VERSION ""

NS_ :

BS_:

BU_: VMM IMR BCS GSM EMS EPB SRS TEL ICM ACU VCU WCM TSCM Tester Test SCMRR SCMRL SCM SBM RCP PSDR PSDL PLGM PAS LCU IHU IBCM IAL HVSPRR HVSPRL HVSMR HVSM HVACF HUD GWM FRDCM FLDCM FCP FAPA ETC Diagnostic Messages AVAS AMP

BO_ 796 BCM_BCAN_4: 8 IBCM
 SG_ BCM_RearWiperSerPstFuncCfgSt : 26|1@0+ (1,0) [0|1] ""  IHU
 SG_ BCM_RLSAutoSRWinCloseCfgSt : 36|1@0+ (1,0) [0|1] ""  IHU,GWM
 SG_ BCM_AutoSRWinCloseCfgSt : 35|1@0+ (1,0) [0|1] ""  IHU,GWM
 SG_ BCM_HeadlightDelayCfgSt : 37|1@0+ (1,0) [0|1] ""  IHU,GWM
 SG_ BCM_IGNOffTime : 23|10@0+ (1,0) [0|1000] "min"  IHU,GWM
 SG_ BCM_IGNOffTimeVD : 29|1@0+ (1,0) [0|1] ""  IHU,GWM
 SG_ BCM_AutoDomeLightCfgSt : 27|1@0+ (1,0) [0|1] ""  IHU
 SG_ BCM_AutoWiperCfgSt : 25|1@0+ (1,0) [0|1] ""  IHU,GWM
 SG_ BCM_IALFuncCfgSt : 24|1@0+ (1,0) [0|1] ""  FCP,IHU,GWM
 SG_ BCM_OSRMAutoFoldCfgSt : 15|1@0+ (1,0) [0|1] ""  FLDCM,FRDCM,IHU,GWM
 SG_ BCM_HornCfgSt : 14|1@0+ (1,0) [0|1] ""  IHU,GWM
 SG_ BCM_DTRLFuncCfgSt : 13|1@0+ (1,0) [0|1] ""  IHU,GWM
 SG_ BCM_RGearEnableRearWipeCfgSt : 12|1@0+ (1,0) [0|1] ""  IHU,GWM
 SG_ BCM_FrontWiperSerPstFuncCfgSt : 11|1@0+ (1,0) [0|1] ""  IHU,GWM
 SG_ BCM_AutoLightSnsCfgSt : 10|3@0+ (1,0) [0|7] ""  IHU,GWM
 SG_ BCM_FollowMeHomeCfgSt : 7|2@0+ (1,0) [0|3] ""  IHU,GWM
 SG_ BCM_AutoUnlockCfgSt : 5|2@0+ (1,0) [0|3] ""  IHU,GWM
 SG_ BCM_SpdAutoLockCfgSt : 3|1@0+ (1,0) [0|1] ""  IHU,GWM
 SG_ BCM_RemoteUnlockCfgSt : 2|1@0+ (1,0) [0|1] ""  IHU,GWM
 SG_ BCM_FogLampTurnCfgSt : 1|1@0+ (1,0) [0|1] ""  IHU,GWM
 SG_ BCM_RemoteCtrlFDMRMCfgSt : 0|1@0+ (1,0) [0|1] ""  FLDCM,FRDCM,IHU,GWM

BO_ 605 BCM_BCAN_2: 8 IBCM
 SG_ BCM_CentralLockSWSt : 55|1@0+ (1,0) [0|1] ""  IHU,GWM
 SG_ BCM_InteriorTrunkReleaseSwitch : 54|1@0+ (1,0) [0|1] ""  PLGM,IHU,GWM
 SG_ BCM_MainLampSwitchSt : 47|2@0+ (1,0) [0|3] ""  LCU,IHU,GWM
 SG_ BCM_BeamSwitchSt : 45|2@0+ (1,0) [0|3] ""  LCU,IHU,GWM
 SG_ BCM_AutoHighBeamCtrlSt : 43|1@0+ (1,0) [0|1] ""  LCU,IHU,FAPA,GWM
 SG_ BCM_RightTurnLampFaultSt : 36|1@0+ (1,0) [0|1] ""  LCU,IHU,PAS,FAPA,GWM
 SG_ BCM_RightTurnLampSt : 35|1@0+ (1,0) [0|1] ""  LCU,FLDCM,FRDCM,IHU,PAS,FAPA,GWM
 SG_ BCM_LeftTurnLampFaultSt : 34|1@0+ (1,0) [0|1] ""  LCU,IHU,PAS,FAPA,GWM
 SG_ BCM_LeftTurnLampSt : 33|1@0+ (1,0) [0|1] ""  LCU,FLDCM,FRDCM,IHU,PAS,FAPA,GWM
 SG_ BCM_LowBeamFaultSt : 31|1@0+ (1,0) [0|1] ""  IHU,GWM
 SG_ BCM_PositionLightFaultSt : 30|1@0+ (1,0) [0|1] ""  IHU,GWM
 SG_ BCM_PositionLightswitchSt : 29|1@0+ (1,0) [0|1] ""  IHU,GWM
 SG_ BCM_BrakeLightFaultSt : 28|1@0+ (1,0) [0|1] ""  IHU,GWM
 SG_ BCM_DRLRFaultSt : 25|1@0+ (1,0) [0|1] ""  IHU,GWM
 SG_ BCM_DRLLFaultSt : 20|1@0+ (1,0) [0|1] ""  IHU,GWM
 SG_ BCM_RearWasherSt : 23|1@0+ (1,0) [0|1] ""  IHU,GWM
 SG_ BCM_ReverseSwitchSt : 13|1@0+ (1,0) [0|1] ""  IHU,FAPA,GWM
 SG_ BCM_RearWiperSt : 12|1@0+ (1,0) [0|1] ""  IHU,GWM
 SG_ BCM_DTRLSt : 10|1@0+ (1,0) [0|1] ""  IHU,GWM
 SG_ BCM_FrontWiperSt : 5|2@0+ (1,0) [0|3] ""  IHU,FAPA,GWM

BO_ 792 BCM_BCAN_1: 8 IBCM
 SG_ RLS_LightSwitchReason : 63|4@0+ (1,0) [0|15] ""  HVACF,IHU,GWM
 SG_ BCM_RemoteControlSt : 59|4@0+ (1,0) [0|15] ""  PLGM,FLDCM,FRDCM,IHU,SBM,GWM
 SG_ BCM_HornSt : 55|1@0+ (1,0) [0|1] ""  IHU,SBM,GWM
 SG_ BCM_FOB_ID : 54|4@0+ (1,0) [0|15] ""  IHU,GWM
 SG_ BCM_DRLRFaultSt : 50|1@0+ (1,0) [0|1] ""  IHU,GWM
 SG_ BCM_DRLLFaultSt : 49|1@0+ (1,0) [0|1] ""  IHU,GWM
 SG_ BCM_FrontWasherSt : 48|1@0+ (1,0) [0|1] ""  HVACF,IHU,GWM
 SG_ BCM_SunRoofPstSt : 47|4@0+ (1,0) [0|15] ""  AMP,IHU,SBM,GWM
 SG_ BCM_WinMoveSt : 43|2@0+ (1,0) [0|3] ""  IHU,SBM,GWM
 SG_ BCM_ETWS_St : 41|1@0+ (1,0) [0|1] ""  IHU,GWM
 SG_ BCM_RoomlampSt : 40|1@0+ (1,0) [0|1] ""  IAL,FCP,IHU,GWM
 SG_ BCM_PsngrDoorLockSt : 39|1@0+ (1,0) [0|1] ""  FLDCM,FRDCM,IAL,IHU,SBM,GWM
 SG_ BCM_DriverDoorLockSt : 38|1@0+ (1,0) [0|1] ""  FLDCM,FRDCM,IAL,IHU,SBM,GWM
 SG_ BCM_ATWS_St : 37|3@0+ (1,0) [0|7] ""  FLDCM,FRDCM,HVACF,IHU,SBM,GWM
 SG_ BCM_AlarmHistory : 34|3@0+ (1,0) [0|7] ""  IHU,GWM
 SG_ BCM_KeyInsertSt : 31|1@0+ (1,0) [0|1] ""  IHU,GWM
 SG_ BCM_KeyInReminderWarnReq : 30|1@0+ (1,0) [0|1] ""  IHU,SBM,GWM
 SG_ BCM_RmtCtrlFobBattLow : 29|1@0+ (1,0) [0|1] ""  IHU,SBM,GWM
 SG_ BCM_TransportModeSt : 28|1@0+ (1,0) [0|1] ""  IHU,GWM
 SG_ BCM_SunRoofOpenWarning : 27|1@0+ (1,0) [0|1] ""  IAL,IHU,SBM,GWM
 SG_ BCM_VehReverseSt : 26|1@0+ (1,0) [0|1] ""  AMP,IAL,IHU,SBM,GWM
 SG_ BCM_BrakeLightSwitchSt : 25|1@0+ (1,0) [0|1] ""  AMP,FLDCM,FRDCM,HVACF,IHU,GWM
 SG_ BCM_ParkingLampSt : 24|1@0+ (1,0) [0|1] ""  HVSPRR,HVSPRL,HVACF,IAL,RCP,FCP,IHU,SBM,GWM
 SG_ BCM_RearFogLampSt : 23|1@0+ (1,0) [0|1] ""  IHU,SBM,GWM
 SG_ BCM_FrontFogLampSt : 22|1@0+ (1,0) [0|1] ""  IHU,SBM,GWM
 SG_ BCM_HighBeamSt : 21|1@0+ (1,0) [0|1] ""  IHU,SBM,GWM
 SG_ BCM_LowBeamSt : 20|1@0+ (1,0) [0|1] ""  IHU,SBM,GWM
 SG_ BCM_RightTurnLampFaultSt : 19|1@0+ (1,0) [0|1] ""  IHU,SBM,GWM
 SG_ BCM_RightTurnLampSt : 18|1@0+ (1,0) [0|1] ""  IAL,FCP,IHU,SBM,GWM
 SG_ BCM_LeftTurnLampFaultSt : 17|1@0+ (1,0) [0|1] ""  IHU,SBM,GWM
 SG_ BCM_LeftTurnLampSt : 16|1@0+ (1,0) [0|1] ""  IAL,FCP,IHU,SBM,GWM
 SG_ BCM_DTRLSt : 15|1@0+ (1,0) [0|1] ""  IHU,GWM
 SG_ BCM_TrunkReleaseCmd : 14|1@0+ (1,0) [0|1] ""  IHU,SBM,GWM
 SG_ BCM_TrunkAjarSt : 13|1@0+ (1,0) [0|1] ""  AMP,IHU,SBM,GWM
 SG_ BCM_BonnetAjarSt : 12|1@0+ (1,0) [0|1] ""  AMP,IHU,SBM,GWM
 SG_ BCM_RRDoorAjarSt : 11|1@0+ (1,0) [0|1] ""  SCMRR,AMP,FLDCM,FRDCM,IAL,IHU,SBM,GWM
 SG_ BCM_RLDoorAjarSt : 10|1@0+ (1,0) [0|1] ""  SCMRL,AMP,FLDCM,FRDCM,IAL,IHU,SBM,GWM
 SG_ BCM_PsngrDoorAjarSt : 9|1@0+ (1,0) [0|1] ""  AMP,FLDCM,FRDCM,IAL,IHU,SBM,GWM
 SG_ BCM_DriverDoorAjarSt : 8|1@0+ (1,0) [0|1] ""  AMP,FLDCM,FRDCM,SCM,IAL,IHU,SBM,GWM
 SG_ BCM_LampOnWarningReq : 5|1@0+ (1,0) [0|1] ""  IHU,SBM,GWM
 SG_ BCM_PGearSt : 4|1@0+ (1,0) [0|1] ""  HUD,IHU,GWM
 SG_ BCM_KeySt : 1|2@0+ (1,0) [0|3] ""  HVSMR,HVSPRR,HVSPRL,SCMRR,SCMRL,AMP,LCU,HUD,FLDCM,FRDCM,SCM,TSCM,HVACF,IAL,RCP,FCP,HVSM,IHU,SBM,GWM

BO_ 1835 ACU_Phys_Diag_Rx: 8 Tester
 SG_ ACU_Diag_Request : 7|64@0+ (1,0) [0|0] ""  IHU

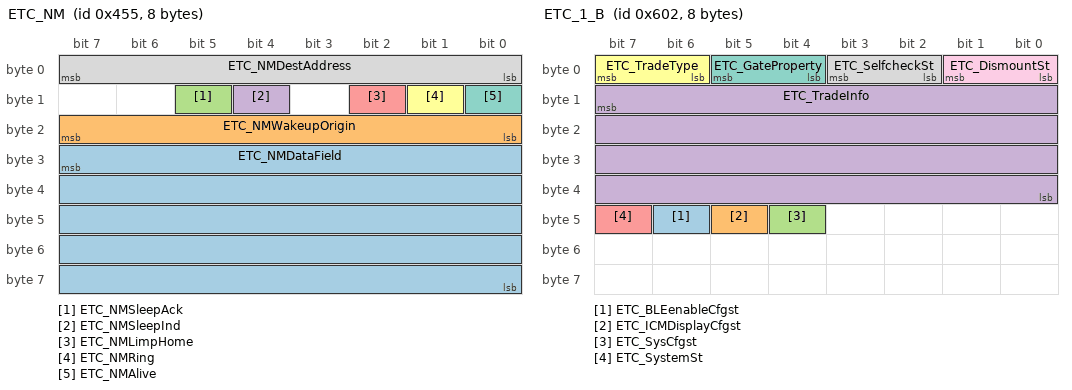
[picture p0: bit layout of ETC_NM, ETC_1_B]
BO_ 1109 ETC_NM: 8 ETC
 SG_ ETC_NMDataField : 31|40@0+ (1,0) [0|0] ""  PSDR,PSDL,AMP,LCU,HUD,PLGM,FLDCM,FRDCM,SCM,TSCM,IBCM,HVACF,IAL,RCP,FCP,HVSM,IHU,SBM,WCM
 SG_ ETC_NMWakeupOrigin : 23|8@0+ (1,0) [0|255] ""  PSDR,PSDL,AMP,LCU,HUD,PLGM,FLDCM,FRDCM,SCM,TSCM,IBCM,HVACF,IAL,RCP,FCP,HVSM,IHU,SBM,WCM
 SG_ ETC_NMSleepAck : 13|1@0+ (1,0) [0|1] ""  PSDR,PSDL,AMP,LCU,HUD,PLGM,FLDCM,FRDCM,SCM,TSCM,IBCM,HVACF,IAL,RCP,FCP,HVSM,IHU,SBM,WCM
 SG_ ETC_NMSleepInd : 12|1@0+ (1,0) [0|1] ""  PSDR,PSDL,AMP,LCU,HUD,PLGM,FLDCM,FRDCM,SCM,TSCM,IBCM,HVACF,IAL,RCP,FCP,HVSM,IHU,SBM,WCM
 SG_ ETC_NMLimpHome : 10|1@0+ (1,0) [0|1] ""  PSDR,PSDL,AMP,LCU,HUD,PLGM,FLDCM,FRDCM,SCM,TSCM,IBCM,HVACF,IAL,RCP,FCP,HVSM,IHU,SBM,WCM
 SG_ ETC_NMRing : 9|1@0+ (1,0) [0|1] ""  PSDR,PSDL,AMP,LCU,HUD,PLGM,FLDCM,FRDCM,SCM,TSCM,IBCM,HVACF,IAL,RCP,FCP,HVSM,IHU,SBM,WCM
 SG_ ETC_NMAlive : 8|1@0+ (1,0) [0|1] ""  PSDR,PSDL,AMP,LCU,HUD,PLGM,FLDCM,FRDCM,SCM,TSCM,IBCM,HVACF,IAL,RCP,FCP,HVSM,IHU,SBM,WCM
 SG_ ETC_NMDestAddress : 7|8@0+ (1,0) [0|255] ""  PSDR,PSDL,AMP,LCU,HUD,PLGM,FLDCM,FRDCM,SCM,TSCM,IBCM,HVACF,IAL,RCP,FCP,HVSM,IHU,SBM,WCM

BO_ 1538 ETC_1_B: 8 ETC
 SG_ ETC_BLEenableCfgst : 46|1@0+ (1,0) [0|1] ""  IHU
 SG_ ETC_ICMDisplayCfgst : 45|1@0+ (1,0) [0|1] ""  IHU
 SG_ ETC_SysCfgst : 44|1@0+ (1,0) [0|1] ""  IHU
 SG_ ETC_TradeInfo : 15|32@0+ (0.01,0) [0|42949672.94] ""  IHU
 SG_ ETC_SystemSt : 47|1@0+ (1,0) [0|3] ""  IHU
 SG_ ETC_TradeType : 7|2@0+ (1,0) [0|3] ""  IHU
 SG_ ETC_GateProperty : 5|2@0+ (1,0) [0|3] ""  IHU
 SG_ ETC_SelfcheckSt : 3|2@0+ (1,0) [0|3] ""  IHU
 SG_ ETC_DismountSt : 1|2@0+ (1,0) [0|3] ""  IHU

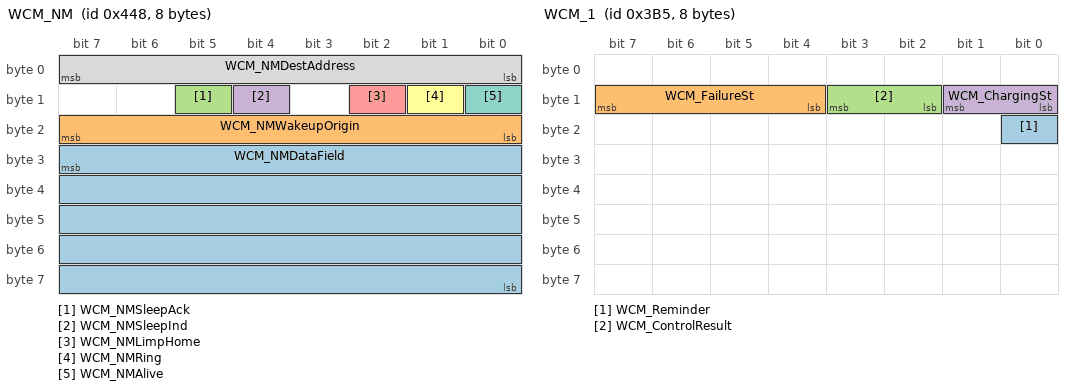
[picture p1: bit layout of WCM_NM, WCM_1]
BO_ 1096 WCM_NM: 8 WCM
 SG_ WCM_NMDataField : 31|40@0+ (1,0) [0|0] ""  PSDR,PSDL,AMP,LCU,HUD,PLGM,FLDCM,FRDCM,SCM,TSCM,IBCM,HVACF,IAL,RCP,FCP,HVSM,IHU,SBM,ETC,GWM
 SG_ WCM_NMWakeupOrigin : 23|8@0+ (1,0) [0|255] ""  PSDR,PSDL,AMP,LCU,HUD,PLGM,FLDCM,FRDCM,SCM,TSCM,IBCM,HVACF,IAL,RCP,FCP,HVSM,IHU,SBM,ETC,GWM
 SG_ WCM_NMSleepAck : 13|1@0+ (1,0) [0|1] ""  PSDR,PSDL,AMP,LCU,HUD,PLGM,FLDCM,FRDCM,SCM,TSCM,IBCM,HVACF,IAL,RCP,FCP,HVSM,IHU,SBM,ETC,GWM
 SG_ WCM_NMSleepInd : 12|1@0+ (1,0) [0|1] ""  PSDR,PSDL,AMP,LCU,HUD,PLGM,FLDCM,FRDCM,SCM,TSCM,IBCM,HVACF,IAL,RCP,FCP,HVSM,IHU,SBM,ETC,GWM
 SG_ WCM_NMLimpHome : 10|1@0+ (1,0) [0|1] ""  PSDR,PSDL,AMP,LCU,HUD,PLGM,FLDCM,FRDCM,SCM,TSCM,IBCM,HVACF,IAL,RCP,FCP,HVSM,IHU,SBM,ETC,GWM
 SG_ WCM_NMRing : 9|1@0+ (1,0) [0|1] ""  PSDR,PSDL,AMP,LCU,HUD,PLGM,FLDCM,FRDCM,SCM,TSCM,IBCM,HVACF,IAL,RCP,FCP,HVSM,IHU,SBM,ETC,GWM
 SG_ WCM_NMAlive : 8|1@0+ (1,0) [0|1] ""  PSDR,PSDL,AMP,LCU,HUD,PLGM,FLDCM,FRDCM,SCM,TSCM,IBCM,HVACF,IAL,RCP,FCP,HVSM,IHU,SBM,ETC,GWM
 SG_ WCM_NMDestAddress : 7|8@0+ (1,0) [0|255] ""  PSDR,PSDL,AMP,LCU,HUD,PLGM,FLDCM,FRDCM,SCM,TSCM,IBCM,HVACF,IAL,RCP,FCP,HVSM,IHU,SBM,ETC,GWM

BO_ 949 WCM_1: 8 WCM
 SG_ WCM_Reminder : 16|1@0+ (1,0) [0|1] ""  IHU,GWM
 SG_ WCM_FailureSt : 15|4@0+ (1,0) [0|15] ""  IHU,GWM
 SG_ WCM_ControlResult : 11|2@0+ (1,0) [0|3] ""  IHU,GWM
 SG_ WCM_ChargingSt : 9|2@0+ (1,0) [0|3] ""  IHU,GWM

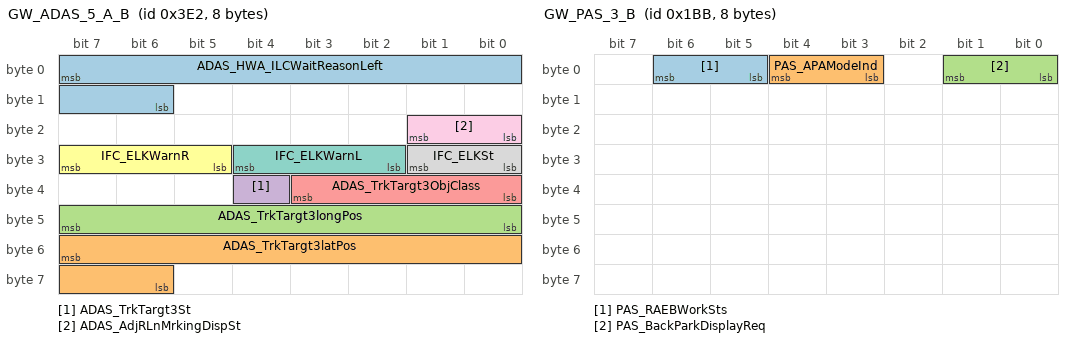
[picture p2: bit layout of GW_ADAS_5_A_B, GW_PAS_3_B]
BO_ 994 GW_ADAS_5_A_B: 8 GWM
 SG_ ADAS_HWA_ILCWaitReasonLeft : 7|10@0+ (1,0) [0|1023] ""  IHU
 SG_ ADAS_TrkTargt3latPos : 55|10@0+ (0.1,-51.2) [-51.2|51.1] "m"  IHU
 SG_ ADAS_TrkTargt3longPos : 47|8@0+ (1,0) [0|254] "m"  IHU
 SG_ ADAS_TrkTargt3St : 36|1@0+ (1,0) [0|1] ""  IHU
 SG_ ADAS_TrkTargt3ObjClass : 35|4@0+ (1,0) [0|15] ""  IHU
 SG_ IFC_ELKWarnR : 31|3@0+ (1,0) [0|7] ""  HUD,IHU
 SG_ IFC_ELKWarnL : 28|3@0+ (1,0) [0|7] ""  HUD,IHU
 SG_ IFC_ELKSt : 25|2@0+ (1,0) [0|3] ""  HUD,IHU
 SG_ ADAS_AdjRLnMrkingDispSt : 17|2@0+ (1,0) [0|3] ""  HUD,IHU

BO_ 760 GW_PADS_1_B: 8 GWM
 SG_ PADS_ICM_MenuBtnStVD : 55|1@0+ (1,0) [0|1] ""  IHU
 SG_ PADS_ICM_MenuBtnSt : 54|1@0+ (1,0) [0|1] ""  IHU
 SG_ PADS_ACU_CusBtnStVD : 53|1@0+ (1,0) [0|1] ""  IHU
 SG_ PADS_ACU_CusBtnSt : 52|1@0+ (1,0) [0|1] ""  IHU
 SG_ PADS_ACU_WechatBtnStVD : 43|1@0+ (1,0) [0|1] ""  IHU
 SG_ PADS_ACU_WechatBtnSt : 42|1@0+ (1,0) [0|1] ""  IHU
 SG_ PADS_ICM_SkipslideBtnSt : 26|2@0+ (1,0) [0|3] ""  IHU
 SG_ PADS_ICM_OkBtnStVD : 24|1@0+ (1,0) [0|1] ""  IHU
 SG_ PADS_ICM_OkBtnSt : 23|1@0+ (1,0) [0|1] ""  IHU
 SG_ PADS_ICM_DowmBtnStVD : 22|1@0+ (1,0) [0|1] ""  IHU
 SG_ PADS_ICM_DowmBtnSt : 21|1@0+ (1,0) [0|1] ""  IHU
 SG_ PADS_ICM_UpBtnStVD : 20|1@0+ (1,0) [0|1] ""  IHU
 SG_ PADS_ICM_UpBtnSt : 19|1@0+ (1,0) [0|1] ""  IHU
 SG_ PADS_ACU_PhoneBtnStVD : 18|1@0+ (1,0) [0|1] ""  IHU
 SG_ PADS_ACU_PhoneBtnSt : 17|1@0+ (1,0) [0|1] ""  IHU
 SG_ PADS_ACU_VrBtnStVD : 16|1@0+ (1,0) [0|1] ""  IHU
 SG_ PADS_ACU_VrBtnSt : 15|1@0+ (1,0) [0|1] ""  IHU
 SG_ PADS_ICM_ViewBtnStVD : 14|1@0+ (1,0) [0|1] ""  IHU
 SG_ PADS_ICM_ViewBtnSt : 13|1@0+ (1,0) [0|1] ""  IHU
 SG_ PADS_ACU_SkipslideBtnStVD : 12|1@0+ (1,0) [0|1] ""  IHU
 SG_ PADS_ACU_SkipslideBtnSt : 11|2@0+ (1,0) [0|3] ""  IHU
 SG_ PADS_ACU_SkipDecBtnStVD : 9|1@0+ (1,0) [0|1] ""  IHU
 SG_ PADS_ACU_SkipDecBtnSt : 8|1@0+ (1,0) [0|1] ""  IHU
 SG_ PADS_ACU_SkipIncBtnStVD : 7|1@0+ (1,0) [0|1] ""  IHU
 SG_ PADS_ACU_SkipIncBtnSt : 6|1@0+ (1,0) [0|1] ""  IHU
 SG_ PADS_ACU_VolDecBtnStVD : 5|1@0+ (1,0) [0|1] ""  IHU
 SG_ PADS_ACU_VolDecBtnSt : 4|1@0+ (1,0) [0|1] ""  IHU
 SG_ PADS_ACU_VolIncBtnStVD : 3|1@0+ (1,0) [0|1] ""  IHU
 SG_ PADS_ACU_VolIncBtnSt : 2|1@0+ (1,0) [0|1] ""  IHU
 SG_ PADS_ACU_ModeBtnStVD : 1|1@0+ (1,0) [0|1] ""  IHU
 SG_ PADS_ACU_ModeBtnSt : 0|1@0+ (1,0) [0|1] ""  IHU

BO_ 443 GW_PAS_3_B: 8 GWM
 SG_ PAS_RAEBWorkSts : 6|2@0+ (1,0) [0|3] "-"  IHU
 SG_ PAS_APAModeInd : 4|2@0+ (1,0) [0|3] ""  IHU
 SG_ PAS_BackParkDisplayReq : 1|2@0+ (1,0) [0|3] ""  IHU

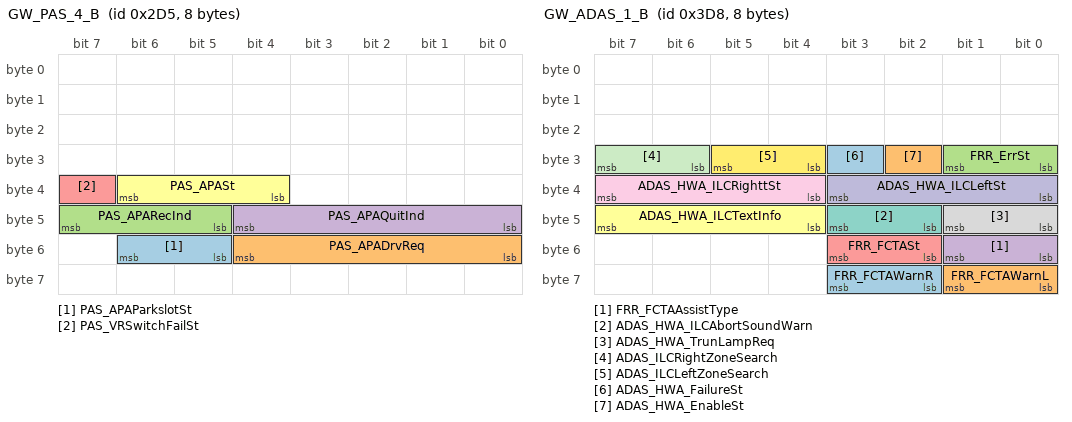
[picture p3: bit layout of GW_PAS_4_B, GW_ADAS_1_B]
BO_ 725 GW_PAS_4_B: 8 GWM
 SG_ PAS_APAParkslotSt : 54|2@0+ (1,0) [0|3] "-"  IHU
 SG_ PAS_APADrvReq : 52|5@0+ (1,0) [0|31] "-"  AMP,IHU,SBM
 SG_ PAS_APARecInd : 47|3@0+ (1,0) [0|7] "-"  AMP,IHU,SBM
 SG_ PAS_APAQuitInd : 44|5@0+ (1,0) [0|31] "-"  AMP,IHU,SBM
 SG_ PAS_VRSwitchFailSt : 39|1@0+ (1,0) [0|1] ""  IHU
 SG_ PAS_APASt : 38|3@0+ (1,0) [0|7] "-"  AMP,IBCM,IHU,SBM

BO_ 984 GW_ADAS_1_B: 8 GWM
 SG_ FRR_FCTAWarnR : 59|2@0+ (1,0) [0|3] ""  HUD,IHU
 SG_ FRR_FCTAWarnL : 57|2@0+ (1,0) [0|3] ""  HUD,IHU
 SG_ FRR_ErrSt : 25|2@0+ (1,0) [0|3] ""  IHU
 SG_ FRR_FCTAAssistType : 49|2@0+ (1,0) [0|3] ""  IHU
 SG_ FRR_FCTASt : 51|2@0+ (1,0) [0|3] ""  HUD,IHU
 SG_ ADAS_HWA_ILCTextInfo : 47|4@0+ (1,0) [0|15] ""  HUD,IHU
 SG_ ADAS_HWA_ILCAbortSoundWarn : 43|2@0+ (1,0) [0|3] ""  IHU
 SG_ ADAS_HWA_TrunLampReq : 41|2@0+ (1,0) [0|3] ""  HUD,IHU
 SG_ ADAS_HWA_ILCRighttSt : 39|4@0+ (1,0) [0|15] ""  IHU
 SG_ ADAS_HWA_ILCLeftSt : 35|4@0+ (1,0) [0|15] ""  IHU
 SG_ ADAS_ILCRightZoneSearch : 31|2@0+ (1,0) [0|3] ""  IHU
 SG_ ADAS_ILCLeftZoneSearch : 29|2@0+ (1,0) [0|3] ""  HUD,IHU
 SG_ ADAS_HWA_FailureSt : 27|1@0+ (1,0) [0|1] ""  HUD,IHU
 SG_ ADAS_HWA_EnableSt : 26|1@0+ (1,0) [0|1] ""  HUD,IHU

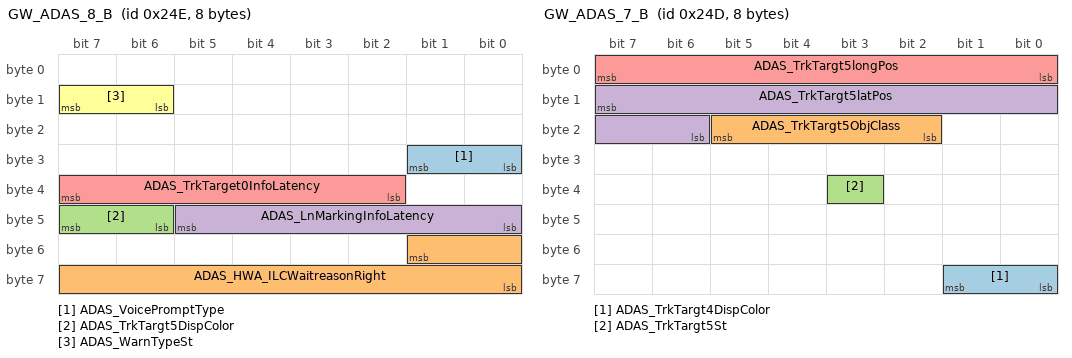
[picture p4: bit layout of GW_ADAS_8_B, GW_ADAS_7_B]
BO_ 590 GW_ADAS_8_B: 8 GWM
 SG_ ADAS_VoicePromptType : 25|2@0+ (1,0) [0|3] ""  ACU,IHU
 SG_ ADAS_HWA_ILCWaitreasonRight : 49|10@0+ (1,0) [0|1023] ""  IHU
 SG_ ADAS_TrkTargt5DispColor : 47|2@0+ (1,0) [0|3] ""  IHU
 SG_ ADAS_LnMarkingInfoLatency : 45|6@0+ (10,0) [0|630] "ms"  IHU
 SG_ ADAS_TrkTarget0InfoLatency : 39|6@0+ (10,0) [0|630] "ms"  IHU
 SG_ ADAS_WarnTypeSt : 15|2@0+ (1,0) [0|3] ""  SCM,IHU

BO_ 589 GW_ADAS_7_B: 8 GWM
 SG_ ADAS_TrkTargt4DispColor : 57|2@0+ (1,0) [0|3] ""  IHU
 SG_ ADAS_TrkTargt5ObjClass : 21|4@0+ (1,0) [0|15] "-"  IHU
 SG_ ADAS_TrkTargt5St : 35|1@0+ (1,0) [0|1] "-"  IHU
 SG_ ADAS_TrkTargt5latPos : 15|10@0+ (0.1,-51.2) [-51.2|51.1] "m"  IHU
 SG_ ADAS_TrkTargt5longPos : 7|8@0+ (1,0) [0|254] "m"  IHU

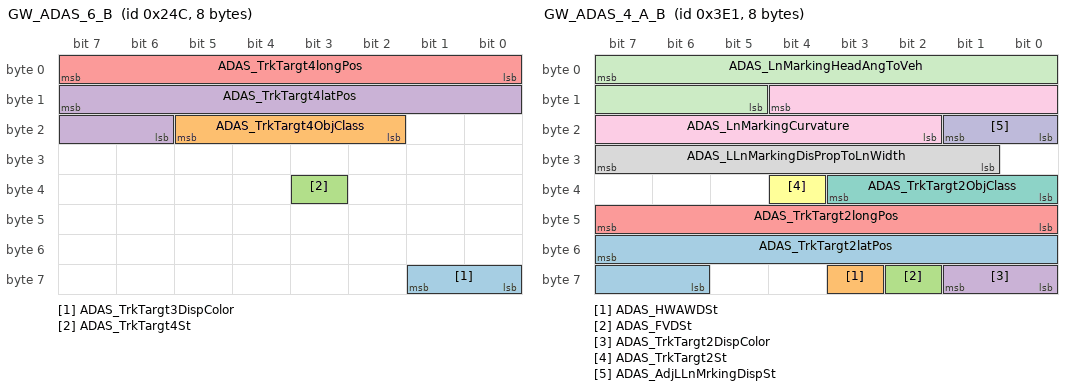
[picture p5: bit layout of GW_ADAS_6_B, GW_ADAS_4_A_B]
BO_ 588 GW_ADAS_6_B: 8 GWM
 SG_ ADAS_TrkTargt3DispColor : 57|2@0+ (1,0) [0|3] ""  HUD,IHU
 SG_ ADAS_TrkTargt4ObjClass : 21|4@0+ (1,0) [0|15] "-"  IHU
 SG_ ADAS_TrkTargt4St : 35|1@0+ (1,0) [0|1] "-"  IHU
 SG_ ADAS_TrkTargt4latPos : 15|10@0+ (0.1,-51.2) [-51.2|51.1] "m"  IHU
 SG_ ADAS_TrkTargt4longPos : 7|8@0+ (1,0) [0|254] "m"  IHU

BO_ 993 GW_ADAS_4_A_B: 8 GWM
 SG_ ADAS_TrkTargt2latPos : 55|10@0+ (0.1,-51.2) [-51.2|51.1] "m"  IHU
 SG_ ADAS_HWAWDSt : 59|1@0+ (1,0) [0|1] ""  IHU
 SG_ ADAS_FVDSt : 58|1@0+ (1,0) [0|1] ""  IHU
 SG_ ADAS_TrkTargt2DispColor : 57|2@0+ (1,0) [0|3] ""  IHU
 SG_ ADAS_TrkTargt2longPos : 47|8@0+ (1,0) [0|254] "m"  IHU
 SG_ ADAS_TrkTargt2St : 36|1@0+ (1,0) [0|1] ""  IHU
 SG_ ADAS_TrkTargt2ObjClass : 35|4@0+ (1,0) [0|15] ""  IHU
 SG_ ADAS_LLnMarkingDisPropToLnWidth : 31|7@0+ (1,0) [0|100] "%"  HUD,IHU
 SG_ ADAS_LnMarkingCurvature : 12|11@0+ (1E-005,-0.01023) [-0.01023|0.01023] "1/m"  HUD,IHU
 SG_ ADAS_AdjLLnMrkingDispSt : 17|2@0+ (1,0) [0|3] ""  HUD,IHU
 SG_ ADAS_LnMarkingHeadAngToVeh : 7|11@0+ (0.001,-1.023) [-1.023|1.023] "rad"  HUD,IHU

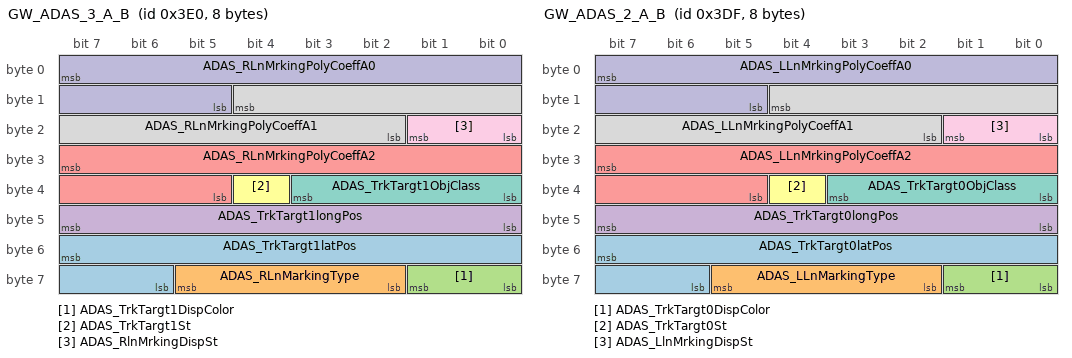
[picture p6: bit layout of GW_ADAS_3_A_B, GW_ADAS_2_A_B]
BO_ 992 GW_ADAS_3_A_B: 8 GWM
 SG_ ADAS_TrkTargt1latPos : 55|10@0+ (0.1,-51.2) [-51.2|51.1] "m"  HUD,IHU
 SG_ ADAS_RLnMarkingType : 61|4@0+ (1,0) [0|15] ""  HUD,IHU
 SG_ ADAS_TrkTargt1DispColor : 57|2@0+ (1,0) [0|3] "-"  HUD,IHU
 SG_ ADAS_TrkTargt1longPos : 47|8@0+ (1,0) [0|254] "m"  HUD,IHU
 SG_ ADAS_RLnMrkingPolyCoeffA2 : 31|11@0+ (1E-005,-0.01023) [-0.01023|0.01023] "1/m"  HUD,IHU
 SG_ ADAS_TrkTargt1St : 36|1@0+ (1,0) [0|1] ""  HUD,IHU
 SG_ ADAS_TrkTargt1ObjClass : 35|4@0+ (1,0) [0|15] ""  HUD,IHU
 SG_ ADAS_RLnMrkingPolyCoeffA1 : 12|11@0+ (0.001,-1.023) [-1.023|1.023] "rad"  HUD,IHU
 SG_ ADAS_RlnMrkingDispSt : 17|2@0+ (1,0) [0|3] ""  HUD,IHU
 SG_ ADAS_RLnMrkingPolyCoeffA0 : 7|11@0+ (0.01,-10.23) [-10.23|10.23] "m"  HUD,IHU

BO_ 991 GW_ADAS_2_A_B: 8 GWM
 SG_ ADAS_TrkTargt0latPos : 55|10@0+ (0.1,-51.2) [-51.2|51.1] "m"  HUD,IHU
 SG_ ADAS_LLnMarkingType : 61|4@0+ (1,0) [0|15] ""  HUD,IHU
 SG_ ADAS_TrkTargt0DispColor : 57|2@0+ (1,0) [0|3] "-"  HUD,IHU
 SG_ ADAS_TrkTargt0longPos : 47|8@0+ (1,0) [0|254] "m"  HUD,IHU
 SG_ ADAS_LLnMrkingPolyCoeffA2 : 31|11@0+ (1E-005,-0.01023) [-0.01023|0.01023] "1/m"  HUD,IHU
 SG_ ADAS_TrkTargt0St : 36|1@0+ (1,0) [0|1] ""  HUD,IHU
 SG_ ADAS_TrkTargt0ObjClass : 35|4@0+ (1,0) [0|15] ""  HUD,IHU
 SG_ ADAS_LLnMrkingPolyCoeffA1 : 12|11@0+ (0.001,-1.023) [-1.023|1.023] "rad"  HUD,IHU
 SG_ ADAS_LlnMrkingDispSt : 17|2@0+ (1,0) [0|3] ""  HUD,IHU
 SG_ ADAS_LLnMrkingPolyCoeffA0 : 7|11@0+ (0.01,-10.23) [-10.23|10.23] "m"  HUD,IHU

BO_ 931 GW_IFC_1_A_B: 8 GWM
 SG_ IFC_TJA_ICA_St : 55|3@0+ (1,0) [0|7] ""  HUD,IHU
 SG_ IFC_TSR_AcousticWarn : 52|1@0+ (1,0) [0|1] ""  HUD,IHU
 SG_ IFC_TSR_VisualWarn : 51|1@0+ (1,0) [0|1] ""  HUD,IHU
 SG_ IFC_IHBC_Enable : 50|1@0+ (1,0) [0|1] ""  IHU
 SG_ IFC_TSR_Enable : 49|1@0+ (1,0) [0|1] ""  HUD,IHU
 SG_ IFC_IHBC_HighBeamReq : 48|1@0+ (1,0) [0|1] ""  IBCM,IHU
 SG_ IFC_IHBC_St : 47|3@0+ (1,0) [0|7] ""  IHU
 SG_ IFC_TSR_OperatingSt : 44|3@0+ (1,0) [0|7] ""  HUD,IHU
 SG_ IFC_TSR_SpdLimitUnit : 41|2@0+ (1,0) [0|3] ""  HUD,IHU
 SG_ IFC_TSR_SpdLimit : 39|5@0+ (1,0) [0|31] ""  HUD,IHU
 SG_ IFC_HWAHF_HandsOnIcon : 34|3@0+ (1,0) [0|7] ""  HUD,IHU
 SG_ IFC_LKS_TakeoverReq : 31|1@0+ (1,0) [0|1] ""  HUD,IHU
 SG_ IFC_RightTrackingSt : 30|2@0+ (1,0) [0|3] ""  HUD,IHU
 SG_ IFC_LeftTrackingSt : 28|2@0+ (1,0) [0|3] ""  HUD,IHU
 SG_ IFC_LKS_St : 26|3@0+ (1,0) [0|7] ""  HUD,IHU
 SG_ IFC_LKS_LaneAssistType : 23|2@0+ (1,0) [0|3] ""  HUD,IHU
 SG_ IFC_TSR_AudioWarnEnable : 20|1@0+ (1,0) [0|1] ""  HUD,IHU
 SG_ IFC_CruiseMode : 15|2@0+ (1,0) [0|3] ""  HUD,IHU
 SG_ IFC_TSR_SpdLimType : 13|2@0+ (1,0) [0|3] ""  HUD,IHU
 SG_ IFC_TSR_ISDRestOfDis : 11|4@0+ (1,0) [0|12] ""  HUD,IHU
 SG_ IFC_LateralCtrlQuitWarn : 7|1@0+ (1,0) [0|1] ""  HUD,IHU
 SG_ IFC_CameraBlockageSt : 6|1@0+ (1,0) [0|1] ""  HUD,IHU
 SG_ IFC_SysCalibrationSt : 5|2@0+ (1,0) [0|3] ""  HUD,IHU
 SG_ IFC_TSR_SLCAheadDis : 3|4@0+ (1,0) [0|12] ""  HUD,IHU

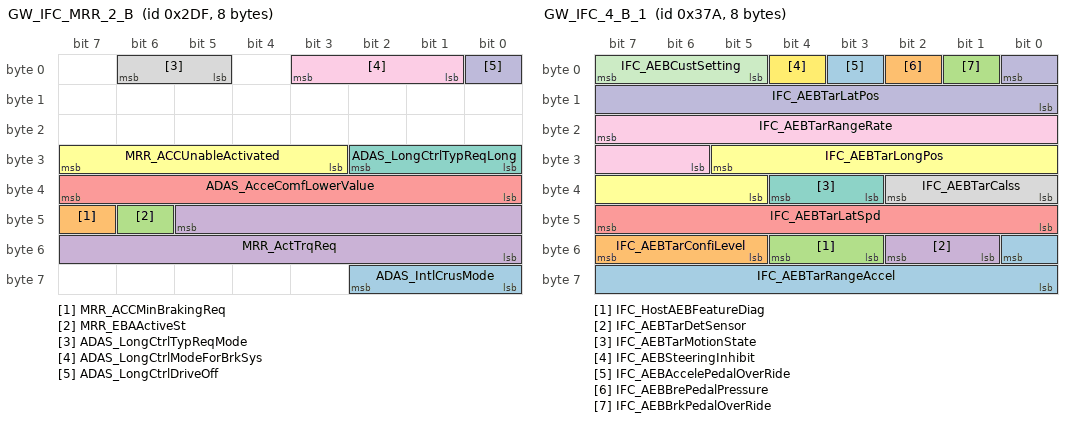
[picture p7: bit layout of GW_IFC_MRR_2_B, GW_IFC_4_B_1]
BO_ 735 GW_IFC_MRR_2_B: 8 GWM
 SG_ ADAS_IntlCrusMode : 58|3@0+ (1,0) [0|7] ""  IHU,PAS
 SG_ MRR_ACCMinBrakingReq : 47|1@0+ (1,0) [0|1] ""  IHU,PAS
 SG_ MRR_EBAActiveSt : 46|1@0+ (1,0) [0|1] ""  IHU,PAS
 SG_ MRR_ActTrqReq : 45|14@0+ (1,-5000) [-5000|5000] "Nm"  IHU,PAS
 SG_ ADAS_AcceComfLowerValue : 39|8@0+ (0.05,-7) [-7|5.75] "m/s2"  IHU,PAS
 SG_ MRR_ACCUnableActivated : 31|5@0+ (1,0) [0|31] ""  IHU,PAS
 SG_ ADAS_LongCtrlTypReqLong : 26|3@0+ (1,0) [0|7] ""  IHU,PAS
 SG_ ADAS_LongCtrlTypReqMode : 6|2@0+ (1,0) [0|3] ""  IHU,PAS
 SG_ ADAS_LongCtrlModeForBrkSys : 3|3@0+ (1,0) [0|7] ""  IHU
 SG_ ADAS_LongCtrlDriveOff : 0|1@0+ (1,0) [0|1] ""  IHU

BO_ 890 GW_IFC_4_B_1: 8 GWM
 SG_ IFC_AEBTarRangeAccel : 48|9@0+ (0.1,-25.5) [-25.5|25.5] "m/s^2"  IHU
 SG_ IFC_AEBTarConfiLevel : 55|3@0+ (1,0) [0|7] ""  IHU
 SG_ IFC_HostAEBFeatureDiag : 52|2@0+ (1,0) [0|3] ""  IHU
 SG_ IFC_AEBTarDetSensor : 50|2@0+ (1,0) [0|3] ""  IHU
 SG_ IFC_AEBTarLatSpd : 47|8@0+ (0.2,-25) [-25|25] "m/s"  IHU
 SG_ IFC_AEBTarLongPos : 29|9@0+ (0.2,0) [0|102.2] "m"  IHU
 SG_ IFC_AEBTarMotionState : 36|2@0+ (1,0) [0|3] ""  IHU
 SG_ IFC_AEBTarCalss : 34|3@0+ (1,0) [0|7] ""  IHU
 SG_ IFC_AEBTarRangeRate : 23|10@0+ (0.1,-51) [-51|51] "m/s"  IHU
 SG_ IFC_AEBTarLatPos : 0|9@0+ (0.2,-51) [-51|51] "m"  IHU
 SG_ IFC_AEBCustSetting : 7|3@0+ (1,0) [0|7] ""  IHU
 SG_ IFC_AEBSteeringInhibit : 4|1@0+ (1,0) [0|1] ""  IHU
 SG_ IFC_AEBAccelePedalOverRide : 3|1@0+ (1,0) [0|1] ""  IHU
 SG_ IFC_AEBBrePedalPressure : 2|1@0+ (1,0) [0|1] ""  IHU
 SG_ IFC_AEBBrkPedalOverRide : 1|1@0+ (1,0) [0|1] ""  IHU

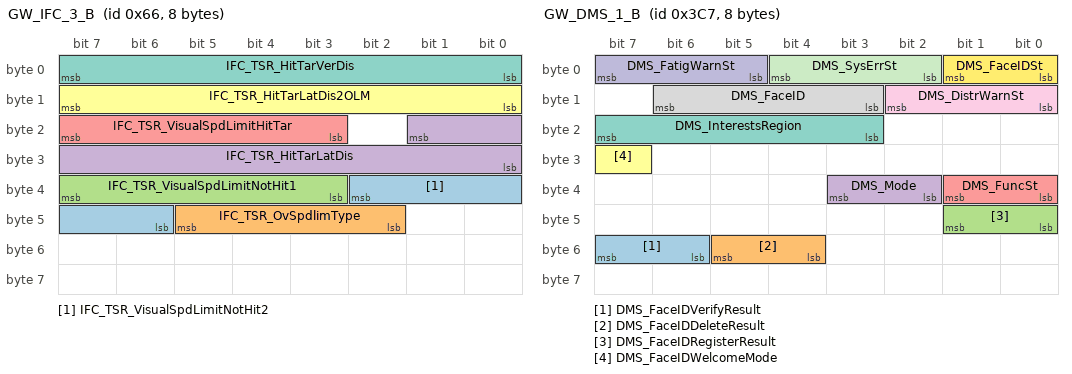
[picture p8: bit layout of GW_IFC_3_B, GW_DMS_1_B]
BO_ 102 GW_IFC_3_B: 8 GWM
 SG_ IFC_TSR_VisualSpdLimitNotHit2 : 34|5@0+ (1,0) [0|31] "km/h"  IHU
 SG_ IFC_TSR_OvSpdlimType : 45|4@0+ (1,0) [0|15] "-"  IHU
 SG_ IFC_TSR_VisualSpdLimitNotHit1 : 39|5@0+ (1,0) [0|31] "km/h"  IHU
 SG_ IFC_TSR_HitTarLatDis : 17|10@0+ (0.1,-51.2) [-25.4|25.4] "m"  IHU
 SG_ IFC_TSR_VisualSpdLimitHitTar : 23|5@0+ (1,0) [0|31] "km/h"  IHU
 SG_ IFC_TSR_HitTarLatDis2OLM : 15|8@0+ (0.1,0) [0|25.4] "m"  IHU
 SG_ IFC_TSR_HitTarVerDis : 7|8@0+ (0.1,0) [0|25.4] "m"  IHU

BO_ 967 GW_DMS_1_B: 8 GWM
 SG_ DMS_FaceIDVerifyResult : 55|2@0+ (1,0) [0|3] ""  IHU
 SG_ DMS_FaceIDDeleteResult : 53|2@0+ (1,0) [0|3] ""  IHU
 SG_ DMS_FaceIDRegisterResult : 41|2@0+ (1,0) [0|3] ""  IHU
 SG_ DMS_Mode : 35|2@0+ (1,0) [0|3] ""  IHU
 SG_ DMS_FuncSt : 33|2@0+ (1,0) [0|3] ""  IHU
 SG_ DMS_FaceIDWelcomeMode : 31|1@0+ (1,0) [0|1] ""  IHU
 SG_ DMS_InterestsRegion : 23|5@0+ (1,0) [0|31] ""  IHU
 SG_ DMS_FaceID : 14|4@0+ (1,0) [0|15] ""  IHU
 SG_ DMS_DistrWarnSt : 10|3@0+ (1,0) [0|7] ""  IHU
 SG_ DMS_FatigWarnSt : 7|3@0+ (1,0) [0|7] ""  IHU
 SG_ DMS_SysErrSt : 4|3@0+ (1,0) [0|7] ""  IHU
 SG_ DMS_FaceIDSt : 1|2@0+ (1,0) [0|3] ""  IHU

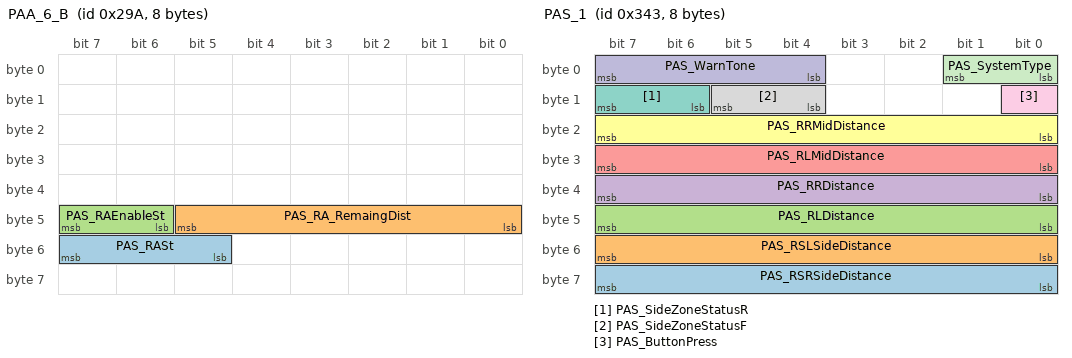
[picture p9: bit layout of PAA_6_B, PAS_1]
BO_ 666 PAA_6_B: 8 FAPA
 SG_ PAS_RASt : 55|3@0+ (1,0) [0|7] ""  IHU
 SG_ PAS_RA_RemaingDist : 45|6@0+ (1,0) [0|63] ""  IHU
 SG_ PAS_RAEnableSt : 47|2@0+ (1,0) [0|3] ""  IHU

BO_ 730 FAPA_1_B: 8 FAPA
 SG_ APA_VoiceReminder_SwitchSts : 52|1@0+ (1,0) [0|1] ""  IHU
 SG_ FAPA_APAActFuncInd : 3|4@0+ (1,0) [0|15] ""  IBCM,IHU,SBM

BO_ 355 PAS_3: 8 PAS
 SG_ PAS_Mode : 53|4@0+ (1,0) [0|15] ""  IHU

BO_ 839 PAS_2: 8 PAS
 SG_ PAS_PCSDisplayReq : 62|1@0+ (1,0) [0|1] ""  AMP,IHU,GWM
 SG_ PAS_BattVoltErrFlag : 61|1@0+ (1,0) [0|1] ""  AMP,IHU,GWM
 SG_ PAS_CtrlModulerrFlag : 60|1@0+ (1,0) [0|1] ""  AMP,IHU,GWM
 SG_ PAS_FSRSnsErrFlag : 59|1@0+ (1,0) [0|1] ""  AMP,IHU,GWM
 SG_ PAS_FSLSnsErrFlag : 58|1@0+ (1,0) [0|1] ""  AMP,IHU,GWM
 SG_ PAS_FLMidSnsErrFlag : 57|1@0+ (1,0) [0|1] ""  AMP,IHU,GWM
 SG_ PAS_FRMidSnsErrFlag : 56|1@0+ (1,0) [0|1] ""  AMP,IHU,GWM
 SG_ PAS_FLSnsErrFlag : 55|1@0+ (1,0) [0|1] "-"  AMP,IHU,GWM
 SG_ PAS_FRSnsErrFlag : 54|1@0+ (1,0) [0|1] "-"  AMP,IHU,GWM
 SG_ PAS_RSRSnsErrFlag : 53|1@0+ (1,0) [0|1] ""  AMP,IHU,GWM
 SG_ PAS_RSLSnsErrFlag : 52|1@0+ (1,0) [0|1] ""  AMP,IHU,GWM
 SG_ PAS_RLSnsErrFlag : 51|1@0+ (1,0) [0|1] ""  AMP,IHU,GWM
 SG_ PAS_RRSnsErrFlag : 50|1@0+ (1,0) [0|1] ""  AMP,IHU,GWM
 SG_ PAS_RLMidSnsErrFlag : 49|1@0+ (1,0) [0|1] ""  AMP,IHU,GWM
 SG_ PAS_RRMidSnsErrFlag : 48|1@0+ (1,0) [0|1] ""  AMP,IHU,GWM
 SG_ PAS_FSLSideDistance : 47|8@0+ (1,0) [0|255] "cm"  AMP,IHU,GWM
 SG_ PAS_FSRSideDistance : 39|8@0+ (1,0) [0|255] "cm"  AMP,IHU,GWM
 SG_ PAS_FLMidDistance : 31|8@0+ (1,0) [0|255] "cm"  AMP,IHU,GWM
 SG_ PAS_FRMidDistance : 23|8@0+ (1,0) [0|255] "cm"  AMP,IHU,GWM
 SG_ PAS_FLDistance : 15|8@0+ (1,0) [0|255] "cm"  AMP,IHU,GWM
 SG_ PAS_FRDistance : 7|8@0+ (1,0) [0|255] "cm"  AMP,IHU,GWM

BO_ 835 PAS_1: 8 PAS
 SG_ PAS_RSRSideDistance : 63|8@0+ (1,0) [0|255] "cm"  AMP,IHU,GWM
 SG_ PAS_RSLSideDistance : 55|8@0+ (1,0) [0|255] "cm"  AMP,IHU,GWM
 SG_ PAS_RLDistance : 47|8@0+ (1,0) [0|255] "cm"  AMP,IHU,GWM
 SG_ PAS_RRDistance : 39|8@0+ (1,0) [0|255] "cm"  AMP,IHU,GWM
 SG_ PAS_RLMidDistance : 31|8@0+ (1,0) [0|255] "cm"  AMP,IHU,GWM
 SG_ PAS_RRMidDistance : 23|8@0+ (1,0) [0|255] "cm"  AMP,IHU,GWM
 SG_ PAS_SideZoneStatusR : 15|2@0+ (1,0) [0|3] "-"  AMP,IHU,GWM
 SG_ PAS_SideZoneStatusF : 13|2@0+ (1,0) [0|3] "-"  AMP,IHU,GWM
 SG_ PAS_ButtonPress : 8|1@0+ (1,0) [0|1] "-"  AMP,IHU,GWM
 SG_ PAS_WarnTone : 7|4@0+ (1,0) [0|15] "-"  AMP,IHU,GWM
 SG_ PAS_SystemType : 1|2@0+ (1,0) [0|3] "-"  AMP,IHU,GWM

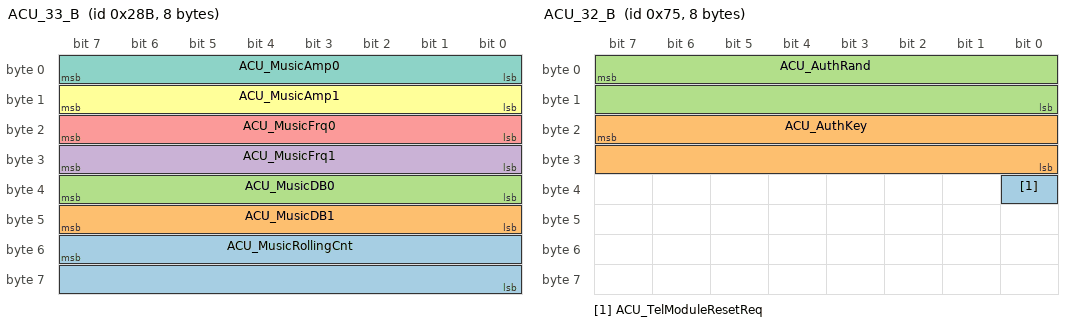
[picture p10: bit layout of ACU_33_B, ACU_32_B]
BO_ 651 ACU_33_B: 8 IHU
 SG_ ACU_MusicRollingCnt : 55|16@0+ (1,0) [0|65535] "" Vector__XXX
 SG_ ACU_MusicDB1 : 47|8@0+ (1,0) [0|255] ""  IBCM
 SG_ ACU_MusicDB0 : 39|8@0+ (1,0) [0|255] ""  IBCM
 SG_ ACU_MusicFrq1 : 31|8@0+ (1,0) [0|255] ""  IBCM
 SG_ ACU_MusicFrq0 : 23|8@0+ (1,0) [0|255] ""  IBCM
 SG_ ACU_MusicAmp1 : 15|8@0+ (1,0) [0|255] ""  IBCM
 SG_ ACU_MusicAmp0 : 7|8@0+ (1,0) [0|255] ""  IBCM

BO_ 117 ACU_32_B: 8 IHU
 SG_ ACU_TelModuleResetReq : 32|1@0+ (1,0) [0|1] ""  GWM
 SG_ ACU_AuthKey : 23|16@0+ (1,0) [0|65535] ""  GWM
 SG_ ACU_AuthRand : 7|16@0+ (1,0) [0|65535] ""  GWM

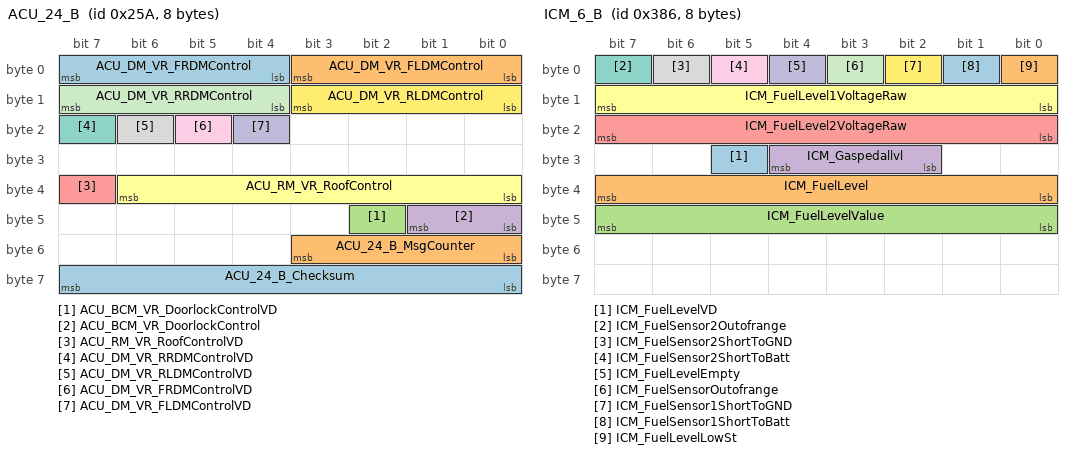
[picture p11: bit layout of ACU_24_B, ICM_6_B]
BO_ 602 ACU_24_B: 8 IHU
 SG_ ACU_24_B_Checksum : 63|8@0+ (1,0) [0|255] ""  IBCM
 SG_ ACU_24_B_MsgCounter : 51|4@0+ (1,0) [0|15] ""  IBCM
 SG_ ACU_BCM_VR_DoorlockControlVD : 42|1@0+ (1,0) [0|1] ""  IBCM
 SG_ ACU_BCM_VR_DoorlockControl : 41|2@0+ (1,0) [0|3] ""  IBCM
 SG_ ACU_RM_VR_RoofControlVD : 39|1@0+ (1,0) [0|1] ""  IBCM
 SG_ ACU_RM_VR_RoofControl : 38|7@0+ (1,0) [0|127] "1%"  IBCM
 SG_ ACU_DM_VR_RRDMControlVD : 23|1@0+ (1,0) [0|1] ""  FLDCM,FRDCM
 SG_ ACU_DM_VR_RLDMControlVD : 22|1@0+ (1,0) [0|1] ""  FLDCM,FRDCM
 SG_ ACU_DM_VR_FRDMControlVD : 21|1@0+ (1,0) [0|1] ""  FLDCM,FRDCM
 SG_ ACU_DM_VR_FLDMControlVD : 20|1@0+ (1,0) [0|1] ""  FLDCM,FRDCM
 SG_ ACU_DM_VR_RRDMControl : 15|4@0+ (1,0) [0|15] ""  FLDCM,FRDCM
 SG_ ACU_DM_VR_RLDMControl : 11|4@0+ (1,0) [0|15] ""  FLDCM,FRDCM
 SG_ ACU_DM_VR_FRDMControl : 7|4@0+ (1,0) [0|15] ""  FLDCM,FRDCM
 SG_ ACU_DM_VR_FLDMControl : 3|4@0+ (1,0) [0|15] ""  FLDCM,FRDCM

BO_ 64 ACU_8_B: 8 IHU
 SG_ ACU_NaviCharacter : 7|64@0+ (1,0) [0|0] "" Vector__XXX

BO_ 902 ICM_6_B: 8 IHU
 SG_ ICM_FuelLevelVD : 29|1@0+ (1,0) [0|1] "" Vector__XXX
 SG_ ICM_FuelLevel : 39|8@0+ (0.5,0) [0|100] "%" Vector__XXX
 SG_ ICM_FuelLevelValue : 47|8@0+ (0.3,0) [0|75] "" Vector__XXX
 SG_ ICM_Gaspedallvl : 28|3@0+ (1,0) [0|7] ""  GWM
 SG_ ICM_FuelLevel2VoltageRaw : 23|8@0+ (0.392,0) [0|99.96] "%"  GWM
 SG_ ICM_FuelLevel1VoltageRaw : 15|8@0+ (0.392,0) [0|99.96] "%"  GWM
 SG_ ICM_FuelSensor2Outofrange : 7|1@0+ (1,0) [0|1] ""  GWM
 SG_ ICM_FuelSensor2ShortToGND : 6|1@0+ (1,0) [0|1] ""  GWM
 SG_ ICM_FuelSensor2ShortToBatt : 5|1@0+ (1,0) [0|1] ""  GWM
 SG_ ICM_FuelLevelEmpty : 4|1@0+ (1,0) [0|1] ""  GWM
 SG_ ICM_FuelSensorOutofrange : 3|1@0+ (1,0) [0|1] ""  GWM
 SG_ ICM_FuelSensor1ShortToGND : 2|1@0+ (1,0) [0|1] ""  GWM
 SG_ ICM_FuelSensor1ShortToBatt : 1|1@0+ (1,0) [0|1] ""  GWM
 SG_ ICM_FuelLevelLowSt : 0|1@0+ (1,0) [0|1] ""  GWM

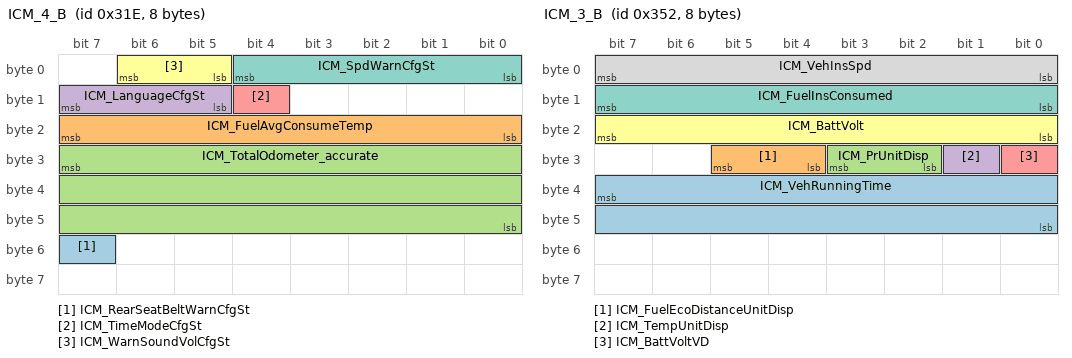
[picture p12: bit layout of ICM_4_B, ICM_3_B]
BO_ 798 ICM_4_B: 8 IHU
 SG_ ICM_RearSeatBeltWarnCfgSt : 55|1@0+ (1,0) [0|1] ""  GWM
 SG_ ICM_FuelAvgConsumeTemp : 23|8@0+ (0.1,0) [0|25.4] "L/100km"  GWM
 SG_ ICM_TotalOdometer_accurate : 31|24@0+ (0.1,0) [0|999999.9] "km"  GWM
 SG_ ICM_LanguageCfgSt : 15|3@0+ (1,0) [0|7] ""  HUD,GWM
 SG_ ICM_TimeModeCfgSt : 12|1@0+ (1,0) [0|1] ""  GWM
 SG_ ICM_WarnSoundVolCfgSt : 6|2@0+ (1,0) [0|3] ""  GWM
 SG_ ICM_SpdWarnCfgSt : 4|5@0+ (10,0) [0|200] "km/h"  GWM

BO_ 850 ICM_3_B: 8 IHU
 SG_ ICM_VehRunningTime : 39|16@0+ (1,0) [0|59999] "min"  GWM
 SG_ ICM_FuelEcoDistanceUnitDisp : 29|2@0+ (1,0) [0|3] ""  GWM
 SG_ ICM_PrUnitDisp : 27|2@0+ (1,0) [0|3] ""  GWM
 SG_ ICM_TempUnitDisp : 25|1@0+ (1,0) [0|1] ""  GWM
 SG_ ICM_BattVoltVD : 24|1@0+ (1,0) [0|1] ""  GWM
 SG_ ICM_BattVolt : 23|8@0+ (0.1,0) [0|25.4] "V"  GWM
 SG_ ICM_FuelInsConsumed : 15|8@0+ (0.1,0) [0|25.4] "L/100km"  GWM
 SG_ ICM_VehInsSpd : 7|8@0+ (1,0) [0|254] "km/h"  HUD,GWM

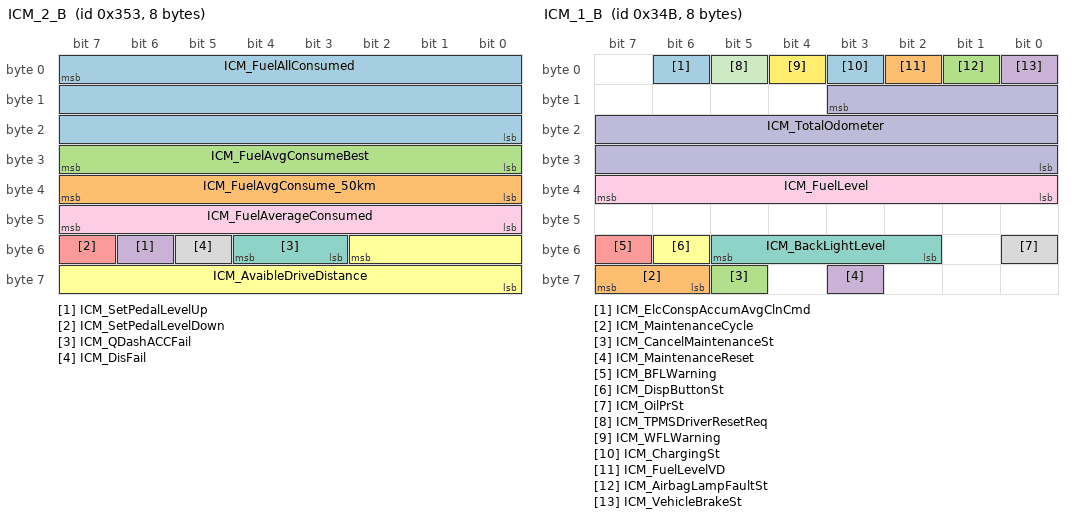
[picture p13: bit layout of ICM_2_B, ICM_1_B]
BO_ 851 ICM_2_B: 8 IHU
 SG_ ICM_FuelAllConsumed : 7|24@0+ (0.01,0) [0|167772.15] "" Vector__XXX
 SG_ ICM_FuelAvgConsume_50km : 39|8@0+ (0.1,0) [0|25.4] "" Vector__XXX
 SG_ ICM_FuelAvgConsumeBest : 31|8@0+ (0.1,0) [0|25.4] "" Vector__XXX
 SG_ ICM_SetPedalLevelUp : 54|1@0+ (1,0) [0|1] "" Vector__XXX
 SG_ ICM_SetPedalLevelDown : 55|1@0+ (1,0) [0|1] "" Vector__XXX
 SG_ ICM_AvaibleDriveDistance : 50|11@0+ (1,0) [0|2047] "km"  GWM
 SG_ ICM_QDashACCFail : 52|2@0+ (1,0) [0|3] ""  GWM
 SG_ ICM_DisFail : 53|1@0+ (1,0) [0|1] ""  GWM
 SG_ ICM_FuelAverageConsumed : 47|8@0+ (0.1,0) [0|25.4] "L/100km"  GWM

BO_ 843 ICM_1_B: 8 IHU
 SG_ ICM_ElcConspAccumAvgClnCmd : 6|1@0+ (1,0) [0|1] "" Vector__XXX
 SG_ ICM_MaintenanceCycle : 63|2@0+ (1,0) [0|3] "" Vector__XXX
 SG_ ICM_CancelMaintenanceSt : 61|1@0+ (1,0) [0|1] "" Vector__XXX
 SG_ ICM_MaintenanceReset : 59|1@0+ (1,0) [0|1] "" Vector__XXX
 SG_ ICM_BFLWarning : 55|1@0+ (1,0) [0|1] ""  GWM
 SG_ ICM_DispButtonSt : 54|1@0+ (1,0) [0|1] ""  GWM
 SG_ ICM_BackLightLevel : 53|4@0+ (1,0) [0|15] ""  HVSPRR,HVSPRL,IBCM,RCP,FCP,GWM
 SG_ ICM_OilPrSt : 48|1@0+ (1,0) [0|1] ""  GWM
 SG_ ICM_FuelLevel : 39|8@0+ (0.5,0) [0|100] "%"  GWM
 SG_ ICM_TotalOdometer : 11|20@0+ (1,0) [0|999999] "km"  IBCM,PAS,FAPA,GWM
 SG_ ICM_TPMSDriverResetReq : 5|1@0+ (1,0) [0|1] ""  GWM
 SG_ ICM_WFLWarning : 4|1@0+ (1,0) [0|1] ""  GWM
 SG_ ICM_ChargingSt : 3|1@0+ (1,0) [0|1] ""  GWM
 SG_ ICM_FuelLevelVD : 2|1@0+ (1,0) [0|1] ""  GWM
 SG_ ICM_AirbagLampFaultSt : 1|1@0+ (1,0) [0|1] ""  GWM
 SG_ ICM_VehicleBrakeSt : 0|1@0+ (1,0) [0|1] ""  HUD,PAS,FAPA,GWM

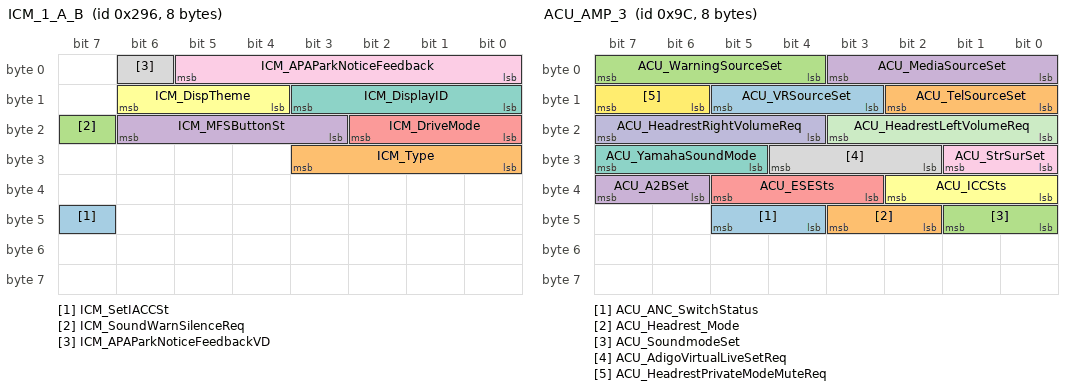
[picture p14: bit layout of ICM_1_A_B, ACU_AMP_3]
BO_ 662 ICM_1_A_B: 8 IHU
 SG_ ICM_SetIACCSt : 47|1@0+ (1,0) [0|1] "" Vector__XXX
 SG_ ICM_Type : 27|4@0+ (1,0) [0|15] "" Vector__XXX
 SG_ ICM_SoundWarnSilenceReq : 23|1@0+ (1,0) [0|1] "" Vector__XXX
 SG_ ICM_MFSButtonSt : 22|4@0+ (1,0) [0|15] "" Vector__XXX
 SG_ ICM_DriveMode : 18|3@0+ (1,0) [0|7] "" Vector__XXX
 SG_ ICM_DispTheme : 14|3@0+ (1,0) [0|7] "" Vector__XXX
 SG_ ICM_DisplayID : 11|4@0+ (1,0) [0|15] "" Vector__XXX
 SG_ ICM_APAParkNoticeFeedbackVD : 6|1@0+ (1,0) [0|1] "" Vector__XXX
 SG_ ICM_APAParkNoticeFeedback : 5|6@0+ (1,0) [0|63] "" Vector__XXX

BO_ 1963 ACU_Diag_Tx: 8 IHU
 SG_ ACU_Diag_Response : 7|64@0+ (1,0) [0|0] "" Vector__XXX

BO_ 156 ACU_AMP_3: 8 IHU
 SG_ ACU_ANC_SwitchStatus : 45|2@0+ (1,0) [0|3] ""  AMP
 SG_ ACU_Headrest_Mode : 43|2@0+ (1,0) [0|3] ""  AMP
 SG_ ACU_SoundmodeSet : 41|2@0+ (1,0) [0|3] ""  AMP
 SG_ ACU_A2BSet : 39|2@0+ (1,0) [0|3] ""  AMP
 SG_ ACU_ESESts : 37|3@0+ (1,0) [0|10] ""  AMP
 SG_ ACU_ICCSts : 34|3@0+ (1,0) [0|10] ""  AMP
 SG_ ACU_YamahaSoundMode : 31|3@0+ (1,0) [0|3] ""  AMP
 SG_ ACU_AdigoVirtualLiveSetReq : 28|3@0+ (1,0) [0|3] ""  AMP
 SG_ ACU_StrSurSet : 25|2@0+ (1,0) [0|1] ""  AMP
 SG_ ACU_HeadrestRightVolumeReq : 23|4@0+ (1,0) [0|15] ""  AMP
 SG_ ACU_HeadrestLeftVolumeReq : 19|4@0+ (1,0) [0|15] ""  AMP
 SG_ ACU_HeadrestPrivateModeMuteReq : 15|2@0+ (1,0) [0|1] ""  AMP
 SG_ ACU_VRSourceSet : 13|3@0+ (1,0) [0|7] ""  AMP
 SG_ ACU_TelSourceSet : 10|3@0+ (1,0) [0|7] ""  AMP
 SG_ ACU_WarningSourceSet : 7|4@0+ (1,0) [0|15] ""  AMP
 SG_ ACU_MediaSourceSet : 3|4@0+ (1,0) [0|15] ""  AMP

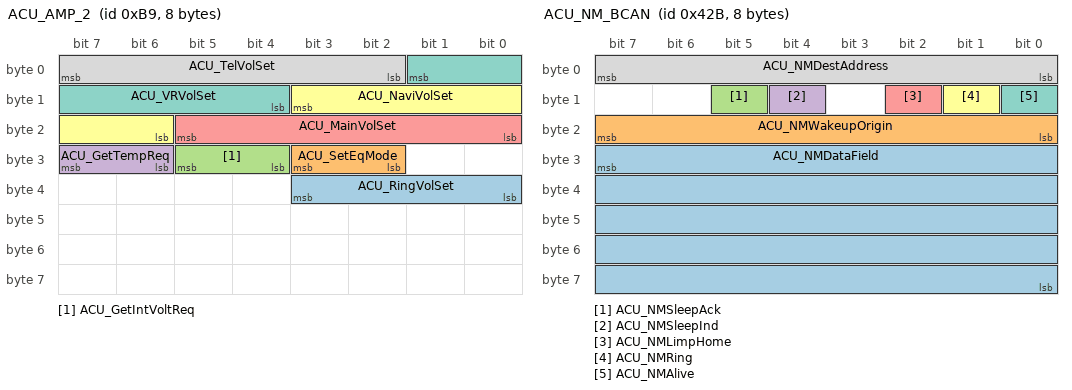
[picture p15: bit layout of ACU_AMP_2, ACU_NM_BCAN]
BO_ 185 ACU_AMP_2: 8 IHU
 SG_ ACU_RingVolSet : 35|4@0+ (1,0) [0|15] "" Vector__XXX
 SG_ ACU_SetEqMode : 27|2@0+ (1,0) [0|3] ""  AMP
 SG_ ACU_GetIntVoltReq : 29|2@0+ (1,0) [0|3] ""  AMP
 SG_ ACU_GetTempReq : 31|2@0+ (1,0) [0|3] ""  AMP
 SG_ ACU_MainVolSet : 21|6@0+ (1,0) [0|63] ""  AMP
 SG_ ACU_NaviVolSet : 11|6@0+ (1,0) [0|63] ""  AMP
 SG_ ACU_VRVolSet : 1|6@0+ (1,0) [0|63] ""  AMP
 SG_ ACU_TelVolSet : 7|6@0+ (1,0) [0|63] ""  AMP

BO_ 186 ACU_AMP_1: 8 IHU
 SG_ ACU_SpeakMid : 57|2@0+ (1,0) [0|3] ""  AMP
 SG_ ACU_SpeakRR : 59|2@0+ (1,0) [0|3] ""  AMP
 SG_ ACU_SpeakRL : 61|2@0+ (1,0) [0|3] ""  AMP
 SG_ ACU_SpeakFR : 63|2@0+ (1,0) [0|3] ""  AMP
 SG_ ACU_SpeakFL : 49|2@0+ (1,0) [0|3] ""  AMP
 SG_ ACU_ClariFiSet : 55|2@0+ (1,0) [0|3] ""  AMP
 SG_ ACU_PowerSet : 41|2@0+ (1,0) [0|3] ""  AMP
 SG_ ACU_HighFrqSet : 46|5@0+ (1,0) [0|31] ""  AMP
 SG_ ACU_TEL_ECallSet : 36|2@0+ (1,0) [0|3] ""  AMP
 SG_ ACU_MuteRearSet : 38|2@0+ (1,0) [0|1] ""  AMP
 SG_ ACU_MuteSet : 24|2@0+ (1,0) [0|1] ""  AMP
 SG_ ACU_DrvSideSet : 26|2@0+ (1,0) [0|3] ""  AMP
 SG_ ACU_MidFrqSet : 31|5@0+ (1,0) [0|31] ""  AMP
 SG_ ACU_LowFrqSet : 20|5@0+ (1,0) [0|31] ""  AMP
 SG_ ACU_VSCModeReq : 23|3@0+ (1,0) [0|3] ""  AMP
 SG_ ACU_NaviSourceSet : 10|3@0+ (1,0) [0|7] ""  AMP
 SG_ ACU_FaderSet : 15|5@0+ (1,0) [0|31] ""  AMP
 SG_ ACU_BeepSourceSet : 2|3@0+ (1,0) [0|7] ""  AMP
 SG_ ACU_BlcSet : 7|5@0+ (1,0) [0|31] ""  AMP

BO_ 1067 ACU_NM_BCAN: 8 IHU
 SG_ ACU_NMDataField : 31|40@0+ (1,0) [0|0] ""  PSDR,PSDL,AMP,LCU,HUD,PLGM,FLDCM,FRDCM,SCM,TSCM,HVACF,IAL,RCP,FCP,HVSM,SBM,WCM,ETC,GWM
 SG_ ACU_NMWakeupOrigin : 23|8@0+ (1,0) [0|255] ""  PSDR,PSDL,AMP,LCU,HUD,PLGM,FLDCM,FRDCM,SCM,TSCM,HVACF,IAL,RCP,FCP,HVSM,SBM,WCM,ETC,GWM
 SG_ ACU_NMSleepAck : 13|1@0+ (1,0) [0|1] ""  PSDR,PSDL,AMP,LCU,HUD,PLGM,FLDCM,FRDCM,SCM,TSCM,HVACF,IAL,RCP,FCP,HVSM,SBM,WCM,ETC,GWM
 SG_ ACU_NMSleepInd : 12|1@0+ (1,0) [0|1] ""  PSDR,PSDL,AMP,LCU,HUD,PLGM,FLDCM,FRDCM,SCM,TSCM,HVACF,IAL,RCP,FCP,HVSM,SBM,WCM,ETC,GWM
 SG_ ACU_NMLimpHome : 10|1@0+ (1,0) [0|1] ""  PSDR,PSDL,AMP,LCU,HUD,PLGM,FLDCM,FRDCM,SCM,TSCM,HVACF,IAL,RCP,FCP,HVSM,SBM,WCM,ETC,GWM
 SG_ ACU_NMRing : 9|1@0+ (1,0) [0|1] ""  PSDR,PSDL,AMP,LCU,HUD,PLGM,FLDCM,FRDCM,SCM,TSCM,HVACF,IAL,RCP,FCP,HVSM,SBM,WCM,ETC,GWM
 SG_ ACU_NMAlive : 8|1@0+ (1,0) [0|1] ""  PSDR,PSDL,AMP,LCU,HUD,PLGM,FLDCM,FRDCM,SCM,TSCM,HVACF,IAL,RCP,FCP,HVSM,SBM,WCM,ETC,GWM
 SG_ ACU_NMDestAddress : 7|8@0+ (1,0) [0|255] ""  PSDR,PSDL,AMP,LCU,HUD,PLGM,FLDCM,FRDCM,SCM,TSCM,HVACF,IAL,RCP,FCP,HVSM,SBM,WCM,ETC,GWM

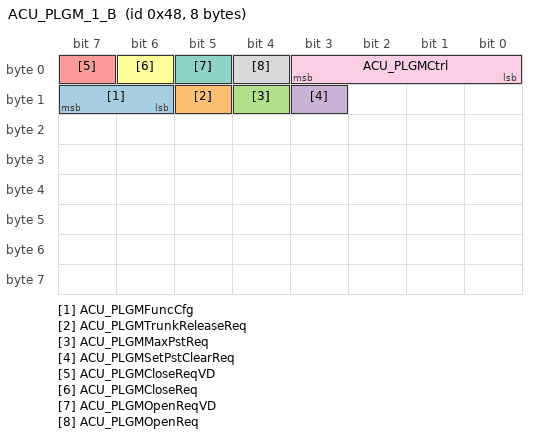
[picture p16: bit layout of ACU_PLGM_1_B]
BO_ 72 ACU_PLGM_1_B: 8 IHU
 SG_ ACU_PLGMFuncCfg : 15|2@0+ (1,0) [0|3] ""  PLGM
 SG_ ACU_PLGMTrunkReleaseReq : 13|1@0+ (1,0) [0|1] ""  PLGM
 SG_ ACU_PLGMMaxPstReq : 12|1@0+ (1,0) [0|1] ""  PLGM
 SG_ ACU_PLGMSetPstClearReq : 11|1@0+ (1,0) [0|1] ""  PLGM
 SG_ ACU_PLGMCloseReqVD : 7|1@0+ (1,0) [0|1] ""  PLGM
 SG_ ACU_PLGMCloseReq : 6|1@0+ (1,0) [0|1] ""  PLGM
 SG_ ACU_PLGMOpenReqVD : 5|1@0+ (1,0) [0|1] ""  PLGM
 SG_ ACU_PLGMOpenReq : 4|1@0+ (1,0) [0|1] ""  PLGM
 SG_ ACU_PLGMCtrl : 3|4@0+ (1,0) [0|15] ""  PLGM

CM_ SG_ 796 BCM_RLSAutoSRWinCloseCfgSt "Automactic Sunroof/Window Close configuration status in rain";
CM_ SG_ 796 BCM_AutoSRWinCloseCfgSt "Automactic Sunroof/Window Close configuration status of locking";
CM_ SG_ 796 BCM_HeadlightDelayCfgSt "Headlight Delay Function Configuration Status";
CM_ SG_ 796 BCM_IGNOffTime "Ignition off time";
CM_ SG_ 796 BCM_IGNOffTimeVD "Ignition off time validity";
CM_ SG_ 796 BCM_AutoDomeLightCfgSt "BCM auto dome light configuration status";
CM_ SG_ 796 BCM_AutoWiperCfgSt "Auto Wiper configuration status";
CM_ SG_ 796 BCM_IALFuncCfgSt "IAL(Interior Ambient Light) function status";
CM_ SG_ 796 BCM_OSRMAutoFoldCfgSt "BCM outside rear view mirror auto folding function configuration status";
CM_ SG_ 796 BCM_HornCfgSt "BCM horn active on lock and unlock
configuration status";
CM_ SG_ 796 BCM_DTRLFuncCfgSt "BCM day time running lamp function configuration status";
CM_ SG_ 796 BCM_RGearEnableRearWipeCfgSt "Reverse gear enable rear wiping configuration status";
CM_ SG_ 796 BCM_FrontWiperSerPstFuncCfgSt "Front wiper service position function configuration status";
CM_ SG_ 796 BCM_AutoLightSnsCfgSt "Sensibility of auto light configuration status";
CM_ SG_ 796 BCM_FollowMeHomeCfgSt "Follow me home function configuration status";
CM_ SG_ 796 BCM_AutoUnlockCfgSt "Auto unlock doors configuration status";
CM_ SG_ 796 BCM_SpdAutoLockCfgSt "High speed auto lock doors configuration status";
CM_ SG_ 796 BCM_RemoteUnlockCfgSt "Remote unlock doors configuration status";
CM_ SG_ 796 BCM_FogLampTurnCfgSt "Fog lamp auxiliary lighting when turning configuration status";
CM_ SG_ 796 BCM_RemoteCtrlFDMRMCfgSt "Remote control driver door window and sun roof configuration status";
CM_ SG_ 605 BCM_CentralLockSWSt "Central lock switch status";
CM_ SG_ 605 BCM_InteriorTrunkReleaseSwitch "Trunk release command";
CM_ SG_ 605 BCM_MainLampSwitchSt "Main Lamp switch status";
CM_ SG_ 605 BCM_BeamSwitchSt "Beam switch status";
CM_ SG_ 605 BCM_AutoHighBeamCtrlSt "Auto high Beam control by IFC(Intelligent Front Camera)status";
CM_ SG_ 605 BCM_RightTurnLampFaultSt "Right turn lamp fault status";
CM_ SG_ 605 BCM_RightTurnLampSt "Right turn lamp status";
CM_ SG_ 605 BCM_LeftTurnLampFaultSt "Left turn lamp fault status";
CM_ SG_ 605 BCM_LeftTurnLampSt "Left turn lamp status";
CM_ SG_ 605 BCM_LowBeamFaultSt "Lowbeam fault status";
CM_ SG_ 605 BCM_PositionLightFaultSt "Position light fault status";
CM_ SG_ 605 BCM_PositionLightswitchSt "Position light switch status";
CM_ SG_ 605 BCM_BrakeLightFaultSt "Brake light fault status";
CM_ SG_ 605 BCM_DRLRFaultSt "Right side DRL(Daytime Running Lamp) fault status";
CM_ SG_ 605 BCM_DRLLFaultSt "Left side DRL(Daytime Running Lamp) fault status";
CM_ SG_ 605 BCM_RearWasherSt "Rear washer status";
CM_ SG_ 605 BCM_ReverseSwitchSt "Reverse switch status";
CM_ SG_ 605 BCM_RearWiperSt "Rear wiper status";
CM_ SG_ 605 BCM_DTRLSt "Day time running lamp status";
CM_ SG_ 605 BCM_FrontWiperSt "Front wiper status";
CM_ SG_ 792 RLS_LightSwitchReason "This signal indicates which ambient conditions have been detected by the running light sensor";
CM_ SG_ 792 BCM_RemoteControlSt "BCM leave out remote mode reasons";
CM_ SG_ 792 BCM_HornSt "Horn status";
CM_ SG_ 792 BCM_FOB_ID "Fob Identification";
CM_ SG_ 792 BCM_DRLRFaultSt "Right side DRL(Daytime Running Lamp) fault status";
CM_ SG_ 792 BCM_DRLLFaultSt "Left side DRL(Daytime Running Lamp) fault status";
CM_ SG_ 792 BCM_FrontWasherSt "Front washer status";
CM_ SG_ 792 BCM_SunRoofPstSt "The sun roof position status.";
CM_ SG_ 792 BCM_WinMoveSt "Window move Status";
CM_ SG_ 792 BCM_ETWS_St "Engine theft warning status";
CM_ SG_ 792 BCM_RoomlampSt "Room lamp status";
CM_ SG_ 792 BCM_PsngrDoorLockSt "Passenger door lock status";
CM_ SG_ 792 BCM_DriverDoorLockSt "Driver door lock status";
CM_ SG_ 792 BCM_ATWS_St "Anti-theft warning status";
CM_ SG_ 792 BCM_AlarmHistory "BCM recent alarm trigger reason";
CM_ SG_ 792 BCM_KeyInsertSt "Key insert status";
CM_ SG_ 792 BCM_KeyInReminderWarnReq "Key in reminder warning";
CM_ SG_ 792 BCM_RmtCtrlFobBattLow "Remote Control Fob Battery Low";
CM_ SG_ 792 BCM_TransportModeSt "Vehicle transport mode request";
CM_ SG_ 792 BCM_SunRoofOpenWarning "SunRoofOpenWarning";
CM_ SG_ 792 BCM_VehReverseSt "Indication the BCM judgement of the vehicle reverse status";
CM_ SG_ 792 BCM_BrakeLightSwitchSt "Brake light switch status";
CM_ SG_ 792 BCM_ParkingLampSt "Parking lamp status";
CM_ SG_ 792 BCM_RearFogLampSt "Rear fog lamp status";
CM_ SG_ 792 BCM_FrontFogLampSt "Front fog lamp status";
CM_ SG_ 792 BCM_HighBeamSt "High beam status";
CM_ SG_ 792 BCM_LowBeamSt "Low beam status";
CM_ SG_ 792 BCM_RightTurnLampFaultSt "Right turn lamp fault status";
CM_ SG_ 792 BCM_RightTurnLampSt "Right turn lamp status";
CM_ SG_ 792 BCM_LeftTurnLampFaultSt "Left turn lamp fault status";
CM_ SG_ 792 BCM_LeftTurnLampSt "Left turn lamp status";
CM_ SG_ 792 BCM_DTRLSt "Day time running lamp status";
CM_ SG_ 792 BCM_TrunkReleaseCmd "Trunk release command";
CM_ SG_ 792 BCM_TrunkAjarSt "Trunk ajar status";
CM_ SG_ 792 BCM_BonnetAjarSt "Bonnet/hood ajar status";
CM_ SG_ 792 BCM_RRDoorAjarSt "Rear right door ajar status";
CM_ SG_ 792 BCM_RLDoorAjarSt "Rear left door ajar status";
CM_ SG_ 792 BCM_PsngrDoorAjarSt "Passenger door ajar status";
CM_ SG_ 792 BCM_DriverDoorAjarSt "Driver door ajar status";
CM_ SG_ 792 BCM_LampOnWarningReq "Lamp left on warning request";
CM_ SG_ 792 BCM_PGearSt "P gear status";
CM_ SG_ 792 BCM_KeySt "Ignition key position status";
CM_ SG_ 1835 ACU_Diag_Request "Diagnostic physical request";
CM_ SG_ 1109 ETC_NMWakeupOrigin "Origin of the wake up";
CM_ SG_ 1109 ETC_NMDestAddress "NM destination address";
CM_ SG_ 1538 ETC_BLEenableCfgst "ETC Bluetooth function Enable & Disable configuration status";
CM_ SG_ 1538 ETC_ICMDisplayCfgst "ETC infomation display on ICM function Enable & Disable configuration status";
CM_ SG_ 1538 ETC_SysCfgst "ETC System Enable & Disable configuration status";
CM_ SG_ 1538 ETC_TradeInfo "Trade infomation";
CM_ SG_ 1538 ETC_SystemSt "OBU System status";
CM_ SG_ 1538 ETC_TradeType "RSU trade type";
CM_ SG_ 1538 ETC_GateProperty "RSU gate property";
CM_ SG_ 1538 ETC_SelfcheckSt "OBU Self check statue";
CM_ SG_ 1538 ETC_DismountSt "OBU dismount status";
CM_ SG_ 1096 WCM_NMWakeupOrigin "Origin of the wake up";
CM_ SG_ 1096 WCM_NMDestAddress "NM destination address";
CM_ SG_ 949 WCM_Reminder "Reminder the Phone left";
CM_ SG_ 949 WCM_FailureSt "WCM failure status";
CM_ SG_ 949 WCM_ControlResult "WCM enable/disable status";
CM_ SG_ 949 WCM_ChargingSt "Charging is ongoing or stopped";
CM_ SG_ 994 ADAS_TrkTargt3latPos "Track Target 3（Closest Right Lane）
Lateral Position";
CM_ SG_ 994 ADAS_TrkTargt3longPos "Track Target 3（Closest Right Lane）
Longitudinal Position";
CM_ SG_ 994 ADAS_TrkTargt3St "Track Target 3（Closest Right Lane）
detection state";
CM_ SG_ 994 ADAS_TrkTargt3ObjClass "Track Target 3（Closest Right Lane）
Object class";
CM_ SG_ 994 IFC_ELKWarnR "ELKA warning right";
CM_ SG_ 994 IFC_ELKWarnL "ELKA warning left";
CM_ SG_ 994 IFC_ELKSt "ELK feature status";
CM_ SG_ 994 ADAS_AdjRLnMrkingDispSt "Display state of Right adjacent Lane's
Right Lane Marking";
CM_ SG_ 760 PADS_ICM_MenuBtnStVD "Indicates PADS_ICM_MenuBtnStVD validity";
CM_ SG_ 760 PADS_ICM_MenuBtnSt "Indicates PADS's ICM Menu button press status";
CM_ SG_ 760 PADS_ACU_CusBtnStVD "Indicates signal PADS_ACU_CusBtnStVD validity";
CM_ SG_ 760 PADS_ACU_CusBtnSt "Indicates PADS's ACU Custom  button press status";
CM_ SG_ 760 PADS_ACU_WechatBtnStVD "Indicates signal PADS_ACU_WechaBtnStVD validity";
CM_ SG_ 760 PADS_ACU_WechatBtnSt "Indicates PADS's ACU Wechat Recognition  button press status";
CM_ SG_ 760 PADS_ICM_SkipslideBtnSt "Indicates PADS's ICM Skipslide button press status";
CM_ SG_ 760 PADS_ICM_OkBtnStVD "Indicates PADS_ICM_OkBtnStVD validity";
CM_ SG_ 760 PADS_ICM_OkBtnSt "Indicates PADS's ICM Ok button press status";
CM_ SG_ 760 PADS_ICM_DowmBtnStVD "Indicates signal PADS_ICM_DowmBtnStVD validity";
CM_ SG_ 760 PADS_ICM_DowmBtnSt "Indicates PADS's ICM Dowm button press status";
CM_ SG_ 760 PADS_ICM_UpBtnStVD "Indicates signal PADS_ICM_UpBtnStVD validity";
CM_ SG_ 760 PADS_ICM_UpBtnSt "Indicates PADS's ICM Up button press status";
CM_ SG_ 760 PADS_ACU_PhoneBtnStVD "Indicates PADS_ACU_PhoneBtnStVD validity";
CM_ SG_ 760 PADS_ACU_PhoneBtnSt "Indicates PADS's ACU Phone button press status";
CM_ SG_ 760 PADS_ACU_VrBtnStVD "Indicates signal PADS_ACU_VrBtnStVD validity";
CM_ SG_ 760 PADS_ACU_VrBtnSt "Indicates PADS's ACU Voice Recognition  button press status";
CM_ SG_ 760 PADS_ICM_ViewBtnStVD "Indicates PADS_ICM_ViewBtnStVD validity";
CM_ SG_ 760 PADS_ICM_ViewBtnSt "Indicates PADS's ICM VIEW button press status";
CM_ SG_ 760 PADS_ACU_SkipslideBtnStVD "Indicates PADS_ACU_SkipslideBtnStVD validity";
CM_ SG_ 760 PADS_ACU_SkipslideBtnSt "Indicates PADS's ACU Skipslide button press status";
CM_ SG_ 760 PADS_ACU_SkipDecBtnStVD "Indicates PADS_ACU_SkipDecBtnStVD validity";
CM_ SG_ 760 PADS_ACU_SkipDecBtnSt "Indicates PADS's ACU SKIP decrease button press status";
CM_ SG_ 760 PADS_ACU_SkipIncBtnStVD "Indicates PADS_ACU_SkipIncBtnStVD validity";
CM_ SG_ 760 PADS_ACU_SkipIncBtnSt "Indicates PADS's ACU SKIP increase button press status";
CM_ SG_ 760 PADS_ACU_VolDecBtnStVD "Indicates PADS_ACU_VolDecBtnStVD validity";
CM_ SG_ 760 PADS_ACU_VolDecBtnSt "Indicates PADS's ACU volume decrease button press status";
CM_ SG_ 760 PADS_ACU_VolIncBtnStVD "Indicates PADS_ACU_VolIncBtnStVD validity";
CM_ SG_ 760 PADS_ACU_VolIncBtnSt "Indicates PADS's ACU volume increase button press status";
CM_ SG_ 760 PADS_ACU_ModeBtnStVD "Indicates PADS_ACU_ModeBtnStVD validity";
CM_ SG_ 760 PADS_ACU_ModeBtnSt "Indicates PADS's ACU MODE button press status";
CM_ BO_ 443 "Implement in PT1 phase";
CM_ SG_ 443 PAS_RAEBWorkSts "RAEB working status";
CM_ SG_ 443 PAS_APAModeInd "APA mode indication";
CM_ SG_ 443 PAS_BackParkDisplayReq "APA Background Parking For AVNT Display";
CM_ SG_ 725 PAS_APAParkslotSt "APA parkslot state";
CM_ SG_ 725 PAS_APADrvReq "APA drive request";
CM_ SG_ 725 PAS_APARecInd "APA Recover indication";
CM_ SG_ 725 PAS_APAQuitInd "APA Quit indication";
CM_ SG_ 725 PAS_VRSwitchFailSt "PAS VR Switch Fail State";
CM_ SG_ 725 PAS_APASt "APA status";
CM_ SG_ 984 FRR_FCTAWarnR "FCTA warning right";
CM_ SG_ 984 FRR_FCTAWarnL "FCTA warning left";
CM_ SG_ 984 FRR_ErrSt "front Corner radar error state";
CM_ SG_ 984 FRR_FCTAAssistType "FCTA assist type request";
CM_ SG_ 984 FRR_FCTASt "FCTA feature status";
CM_ SG_ 984 ADAS_HWA_ILCTextInfo "HWA(High Way Assist)  indication lane change text information";
CM_ SG_ 984 ADAS_HWA_ILCAbortSoundWarn "HWA(High Way Assist)  indication lane change abort sound warning";
CM_ SG_ 984 ADAS_HWA_TrunLampReq "HWA(High Way Assist) indication lanechange turn lamp request";
CM_ SG_ 984 ADAS_HWA_ILCRighttSt "HWA(High Way Assist)  indication lane change right side state";
CM_ SG_ 984 ADAS_HWA_ILCLeftSt "HWA(High Way Assist)  indication lane change left side state";
CM_ SG_ 984 ADAS_ILCRightZoneSearch "HWA(High Way Assist) indication lanechange right side indication symbol fordisplay";
CM_ SG_ 984 ADAS_ILCLeftZoneSearch "HWA(High Way Assist) indication lanechange left side indication symbol fordisplay";
CM_ SG_ 984 ADAS_HWA_FailureSt "The HWA(High Way Assist) function
Failure State";
CM_ SG_ 984 ADAS_HWA_EnableSt "The HWA(High Way Assist) function
Enable state";
CM_ SG_ 590 ADAS_LnMarkingInfoLatency "the latency of lanemarking";
CM_ SG_ 590 ADAS_TrkTarget0InfoLatency "the latency of tracking target0 info";
CM_ SG_ 590 ADAS_WarnTypeSt "ADAS warning type state";
CM_ SG_ 589 ADAS_TrkTargt5ObjClass "Track Target 5（Before Tarcet 3, The Second Closest Right Lane）Object class";
CM_ SG_ 589 ADAS_TrkTargt5St "Track Target 5（Before Tarcet 3, The Second Closest Right Lane）detection state";
CM_ SG_ 589 ADAS_TrkTargt5latPos "Track Target 5（Before Tarcet 3, The Second Closest Right Lane） Lateral Position";
CM_ SG_ 589 ADAS_TrkTargt5longPos "Track Target 5（Before Tarcet 3, The Second Closest Right Lane） Longitudinal Position";
CM_ SG_ 588 ADAS_TrkTargt3DispColor "Track Target 3（Closest Right Lane）
Object color";
CM_ SG_ 588 ADAS_TrkTargt4ObjClass "Track Target 2（Closest Left Lane）Object class";
CM_ SG_ 588 ADAS_TrkTargt4St "Track Target 4（Before Tarcet 2, The Second Closest Left Lane）detection state";
CM_ SG_ 588 ADAS_TrkTargt4latPos "Track Target 4（Before Tarcet 2, The Second Closest Left Lane） Lateral Position";
CM_ SG_ 588 ADAS_TrkTargt4longPos "Track Target 4（Before Tarcet 2, The Second Closest Left Lane） Longitudinal Position";
CM_ SG_ 993 ADAS_TrkTargt2latPos "Track Target 2（Closest Left Lane）
Lateral Position";
CM_ SG_ 993 ADAS_HWAWDSt "HWAWD(Wisdom Deviation) Status";
CM_ SG_ 993 ADAS_FVDSt "FVD(Front Vehicle Distance) Status";
CM_ SG_ 993 ADAS_TrkTargt2DispColor "Track Target 2（Closest Left Lane）Object color";
CM_ SG_ 993 ADAS_TrkTargt2longPos "Track Target 2（Closest Left Lane）
Longitudinal Position";
CM_ SG_ 993 ADAS_TrkTargt2St "Track Target 2（Closest Left Lane）
detection state";
CM_ SG_ 993 ADAS_TrkTargt2ObjClass "Track Target 2（Closest Left Lane）
Object class";
CM_ SG_ 993 ADAS_LLnMarkingDisPropToLnWidth "The proportion of left lane marking distance to the lane width.It also stands for The lane markings position to the middle of the ego vehicle for HMI display. 0% means the point the middle of ego vehicle cross left lane marking while 100% means crossing ";
CM_ SG_ 993 ADAS_LnMarkingCurvature "The curvature of the lane markings for HMI display.";
CM_ SG_ 993 ADAS_AdjLLnMrkingDispSt "Display state of Left adjacent Lane's
Left Lane Marking";
CM_ SG_ 993 ADAS_LnMarkingHeadAngToVeh "The heading angle between lane markings and ego vehicle for HMI display.";
CM_ SG_ 992 ADAS_TrkTargt1latPos "Track Target 1（Before Tarcet 0, The
Second Closest Same Lane） Lateral
Position";
CM_ SG_ 992 ADAS_RLnMarkingType "Right side of lane marking indication type";
CM_ SG_ 992 ADAS_TrkTargt1DispColor "Track Target 1（Before Tarcet 0, The Second Closest Same Lane）display color";
CM_ SG_ 992 ADAS_TrkTargt1longPos "Track Target 1（Before Tarcet 0, The
Second Closest Same Lane）
Longitudinal Position";
CM_ SG_ 992 ADAS_RLnMrkingPolyCoeffA2 "Right Lane Marking Polynomial
Coefficient A2, which stands for the
curvature of the lane marking.";
CM_ SG_ 992 ADAS_TrkTargt1St "Track Target 1（Before Tarcet 0, The
Second Closest Same Lane）detection
state";
CM_ SG_ 992 ADAS_TrkTargt1ObjClass "Track Target 1（Before Tarcet 0, The
Second Closest Same Lane）Object
class";
CM_ SG_ 992 ADAS_RLnMrkingPolyCoeffA1 "Right Lane Marking Polynomial
Coefficient A1, which stands for the
heading angle between the lane
marking and the ego vehicle.";
CM_ SG_ 992 ADAS_RlnMrkingDispSt "Display state of the right lane marking";
CM_ SG_ 992 ADAS_RLnMrkingPolyCoeffA0 "Right Lane Marking Polynomial
Coefficient A0, which stands for the
lateral distance between the lane
marking and the middle of the eog
vehicle.";
CM_ SG_ 991 ADAS_TrkTargt0latPos "Track Target 0（Closest Same Lane）
Lateral Position";
CM_ SG_ 991 ADAS_LLnMarkingType "Left side of lane marking indication type";
CM_ SG_ 991 ADAS_TrkTargt0DispColor "Display color of track target 0";
CM_ SG_ 991 ADAS_TrkTargt0longPos "Track Target 0（Closest Same Lane）
Longitudinal Position";
CM_ SG_ 991 ADAS_LLnMrkingPolyCoeffA2 "Left Lane Marking Polynomial
Coefficient A2, which stands for the
curvature of the lane marking.";
CM_ SG_ 991 ADAS_TrkTargt0St "Track Target 0（Closest Same Lane）
detection state";
CM_ SG_ 991 ADAS_TrkTargt0ObjClass "Track Target 0（Closest Same Lane）
Object class";
CM_ SG_ 991 ADAS_LLnMrkingPolyCoeffA1 "Left Lane Marking Polynomial
Coefficient A1, which stands for the
heading angle between the lane
marking and the ego vehicle.";
CM_ SG_ 991 ADAS_LlnMrkingDispSt "Display state of the left lane marking";
CM_ SG_ 991 ADAS_LLnMrkingPolyCoeffA0 "Left Lane Marking Polynomial
Coefficient A0, which stands for the
lateral distance between lane marking
and the middle of the eog vehicle.";
CM_ SG_ 931 IFC_TJA_ICA_St "TJA/ICA（Traffic Jam Assist/Integrated Cruise Assist） Status";
CM_ SG_ 931 IFC_TSR_AcousticWarn "TSR(Traffic Sign Recognition) acoustic  warning";
CM_ SG_ 931 IFC_TSR_VisualWarn "TSR(Traffic Sign Recognition) visual warning";
CM_ SG_ 931 IFC_IHBC_Enable "IHBC (Intelligent High Beam Control) enable status";
CM_ SG_ 931 IFC_TSR_Enable "TSR(Traffic Sign Recognition) enable status";
CM_ SG_ 931 IFC_IHBC_HighBeamReq "IHBC high beam request";
CM_ SG_ 931 IFC_IHBC_St "IHBC (Intelligent High Beam Control) status";
CM_ SG_ 931 IFC_TSR_OperatingSt "Operation status of traffic sign functions";
CM_ SG_ 931 IFC_TSR_SpdLimitUnit "TSR(Traffic Sign Recognition) speed limit unit";
CM_ SG_ 931 IFC_TSR_SpdLimit "TSR(Traffic Sign Recognition)Speed limit values";
CM_ SG_ 931 IFC_HWAHF_HandsOnIcon "TJA/ICA and HWA HandsOff function request driver hands on icon";
CM_ SG_ 931 IFC_LKS_TakeoverReq "Take over request to driver";
CM_ SG_ 931 IFC_RightTrackingSt "Right line tracking/intervention/warning status";
CM_ SG_ 931 IFC_LeftTrackingSt "Left line tracking/intervention/warning status";
CM_ SG_ 931 IFC_LKS_St "LKS state information";
CM_ SG_ 931 IFC_LKS_LaneAssistType "operation mode of IFC(Intelligent Front Camera)";
CM_ SG_ 931 IFC_TSR_AudioWarnEnable "TSR(Traffic Sign Recognition) audio warning on off status";
CM_ SG_ 931 IFC_CruiseMode "ADAS Cruise Mode Setting State";
CM_ SG_ 931 IFC_TSR_SpdLimType "TSR specific speed limit type";
CM_ SG_ 931 IFC_TSR_ISDRestOfDis "the distance(percentage) has passed durning currnt interval speed dectection.";
CM_ SG_ 931 IFC_LateralCtrlQuitWarn "Lateral control quit warning, which would be used to let the driver pay attention to the situation that lateral control is quit while the longitudinal contrl may still working.";
CM_ SG_ 931 IFC_CameraBlockageSt "IFC(Intelligent Front Camera) camera blockage status";
CM_ SG_ 931 IFC_SysCalibrationSt "IFC(Intelligent Front Camera) system calibration status";
CM_ SG_ 931 IFC_TSR_SLCAheadDis "Speed Limit Camera Ahead distance ahead(percentage)";
CM_ SG_ 735 ADAS_IntlCrusMode "Intelligent Cruise Mode For HMI";
CM_ SG_ 735 MRR_ACCMinBrakingReq "From ACC side, after override, ACC should send the bit until the vehcile speed decease and reach the ACC set speed in order to have a smooth brake";
CM_ SG_ 735 MRR_EBAActiveSt "This signal indicates if the EBA(Emergency Braking Assist)  is actived";
CM_ SG_ 735 MRR_ActTrqReq "Effective target torque on wheel level";
CM_ SG_ 735 ADAS_AcceComfLowerValue "this signal indicates the lower taget acceleration";
CM_ SG_ 735 MRR_ACCUnableActivated "ACC suppression/abortion condition";
CM_ SG_ 735 ADAS_LongCtrlTypReqLong "motion service type from LongitudinalControl(from driving)";
CM_ SG_ 735 ADAS_LongCtrlTypReqMode "IntelligentCruise from LongitudinalControl";
CM_ SG_ 735 ADAS_LongCtrlModeForBrkSys "LongitudinalControl Mode For BrakeSys";
CM_ SG_ 735 ADAS_LongCtrlDriveOff "LongitudinalControl requires driving off";
CM_ SG_ 890 IFC_AEBTarRangeAccel "AEB Target Longtitul Acceleration";
CM_ SG_ 890 IFC_AEBTarConfiLevel "AEB Target Confidence Level";
CM_ SG_ 890 IFC_HostAEBFeatureDiag "AEB Diagnosis In Feature Host";
CM_ SG_ 890 IFC_AEBTarDetSensor "AEB Target Property Detected by Sensor";
CM_ SG_ 890 IFC_AEBTarLatSpd "AEB Target  lateral Speed";
CM_ SG_ 890 IFC_AEBTarLongPos "AEB Target Longitudinal Possition";
CM_ SG_ 890 IFC_AEBTarMotionState "Indictate AEB Target in Moving or stationary";
CM_ SG_ 890 IFC_AEBTarCalss "AEB Target Object Class";
CM_ SG_ 890 IFC_AEBTarRangeRate "AEB Target RangeRate";
CM_ SG_ 890 IFC_AEBTarLatPos "AEB Target  lateral Position";
CM_ SG_ 890 IFC_AEBCustSetting "AEB Working Mode setting by the Customer";
CM_ SG_ 890 IFC_AEBSteeringInhibit "AEB override status whith Certain Steering angel or angelSpeed";
CM_ SG_ 890 IFC_AEBAccelePedalOverRide "AEB override status whith Certain gaspedal";
CM_ SG_ 890 IFC_AEBBrePedalPressure "AEB override status when Brakepedal with ESP Pressure";
CM_ SG_ 890 IFC_AEBBrkPedalOverRide "AEB override status when Brakepedal applied";
CM_ SG_ 102 IFC_TSR_VisualSpdLimitNotHit2 "the value of speed limit sign detected by IFC, which is already jduge as NOT belong to current road by IFC.";
CM_ SG_ 102 IFC_TSR_OvSpdlimType "the type of speed limit type detected by IFC";
CM_ SG_ 102 IFC_TSR_VisualSpdLimitNotHit1 "the value of speed limit sign detected by IFC, which is already jduge as NOT belong to current road by IFC.";
CM_ SG_ 102 IFC_TSR_HitTarLatDis "lateral distance between the center of the speed limit sign and the middle of ego vehicle";
CM_ SG_ 102 IFC_TSR_VisualSpdLimitHitTar "the value of speed limit sign detected by IFC, which is already jduge as belong to current road by IFC.";
CM_ SG_ 102 IFC_TSR_HitTarLatDis2OLM "lateral distance between the center of the speed limit sign and the most outside lane marking detected by IFC";
CM_ SG_ 102 IFC_TSR_HitTarVerDis "vertical distance between the center of the speed limit sign and the center point of the rear axle of ego vehicle";
CM_ SG_ 967 DMS_FaceIDVerifyResult "Indication FaceID_Verify_result";
CM_ SG_ 967 DMS_FaceIDDeleteResult "Indication FaceID_Delete_result";
CM_ SG_ 967 DMS_FaceIDRegisterResult "Indication FaceID_Register_result";
CM_ SG_ 967 DMS_Mode "DMS function mode";
CM_ SG_ 967 DMS_FuncSt "DMS function disable state";
CM_ SG_ 967 DMS_FaceIDWelcomeMode "Indication FaceID Welcome mode";
CM_ SG_ 967 DMS_InterestsRegion "region of interests";
CM_ SG_ 967 DMS_FaceID "FaceID";
CM_ SG_ 967 DMS_DistrWarnSt "Provides the driver distraction determined by the driver facing camera.";
CM_ SG_ 967 DMS_FatigWarnSt "Indicates the fatigue level of the driver.";
CM_ SG_ 967 DMS_SysErrSt "Driver monitoring system error status";
CM_ SG_ 967 DMS_FaceIDSt "Indication FaceID Status";
CM_ BO_ 666 "后续可能调整";
CM_ SG_ 666 PAS_RASt "RA working state";
CM_ SG_ 666 PAS_RA_RemaingDist "RA the remaining distance";
CM_ SG_ 666 PAS_RAEnableSt "RA enable state";
CM_ SG_ 730 FAPA_APAActFuncInd "Auto_parking Active Function Indication";
CM_ SG_ 355 PAS_Mode "Ultrasonic Sensor Working Mode";
CM_ SG_ 839 PAS_PCSDisplayReq "PAS request PCS to display";
CM_ SG_ 839 PAS_BattVoltErrFlag "Error flag of IGN voltage.";
CM_ SG_ 839 PAS_CtrlModulerrFlag "Error flag of EEPROM.";
CM_ SG_ 839 PAS_FSRSnsErrFlag "Error flag of front right side sensor";
CM_ SG_ 839 PAS_FSLSnsErrFlag "Error flag of front left side sensor";
CM_ SG_ 839 PAS_FLMidSnsErrFlag "Error flag of front left middle sensor";
CM_ SG_ 839 PAS_FRMidSnsErrFlag "Error flag of front right middle sensor";
CM_ SG_ 839 PAS_FLSnsErrFlag "Error flag of front left sensor";
CM_ SG_ 839 PAS_FRSnsErrFlag "Error flag of front right sensor";
CM_ SG_ 839 PAS_RSRSnsErrFlag "Error flag of rear right side sensor";
CM_ SG_ 839 PAS_RSLSnsErrFlag "Error flag of rear left side sensor";
CM_ SG_ 839 PAS_RLSnsErrFlag "Error flag of rear left sensor";
CM_ SG_ 839 PAS_RRSnsErrFlag "Error flag of rear right sensor";
CM_ SG_ 839 PAS_RLMidSnsErrFlag "Error flag of rear leftt middle sensor";
CM_ SG_ 839 PAS_RRMidSnsErrFlag "Error flag of rear right middle sensor";
CM_ SG_ 839 PAS_FSLSideDistance "Distance from front left side sensor";
CM_ SG_ 839 PAS_FSRSideDistance "Distance from front right side sensor";
CM_ SG_ 839 PAS_FLMidDistance "Distance from front left middle sensor";
CM_ SG_ 839 PAS_FRMidDistance "Distance from front right middle sensor";
CM_ SG_ 839 PAS_FLDistance "Distance from front left sensor";
CM_ SG_ 839 PAS_FRDistance "Distance from front right sensor";
CM_ SG_ 835 PAS_RSRSideDistance "Distance from rear right side sensor";
CM_ SG_ 835 PAS_RSLSideDistance "Distance from rear left side sensor";
CM_ SG_ 835 PAS_RLDistance "Distance from rear left sensor";
CM_ SG_ 835 PAS_RRDistance "Distance from rear right  sensor";
CM_ SG_ 835 PAS_RLMidDistance "Distance from rear left middle sensor";
CM_ SG_ 835 PAS_RRMidDistance "Distance from rear right middle sensor";
CM_ SG_ 835 PAS_SideZoneStatusR "Rear side zone status";
CM_ SG_ 835 PAS_SideZoneStatusF "Front side zone status";
CM_ SG_ 835 PAS_ButtonPress "RPA button press status";
CM_ SG_ 835 PAS_WarnTone "Warning tone";
CM_ SG_ 835 PAS_SystemType "PAS(Parking Assistant Sytem)  system type";
CM_ SG_ 651 ACU_MusicRollingCnt "Music Rolling Counter";
CM_ SG_ 651 ACU_MusicDB1 "Music DB 1";
CM_ SG_ 651 ACU_MusicDB0 "Music DB 0";
CM_ SG_ 651 ACU_MusicFrq1 "Music Frequency 1";
CM_ SG_ 651 ACU_MusicFrq0 "Music Frequency 0";
CM_ SG_ 651 ACU_MusicAmp1 "Music Amplitude 1";
CM_ SG_ 651 ACU_MusicAmp0 "Music Amplitude 0";
CM_ SG_ 117 ACU_TelModuleResetReq "ACU TBOX Module Reset Requst";
CM_ SG_ 117 ACU_AuthKey "ACU TBOX Author  Key";
CM_ SG_ 117 ACU_AuthRand "ACU TBOX Author Random Number";
CM_ BO_ 602 "Only for AVNT";
CM_ SG_ 602 ACU_24_B_MsgCounter "The message counter is a 0-15 counter, increased of one unit on every message transmission";
CM_ SG_ 602 ACU_BCM_VR_DoorlockControlVD "Indicates signal ACU_BCM_VR_DoorlockControlvalidity";
CM_ SG_ 602 ACU_BCM_VR_DoorlockControl "control vehicle lock by VR";
CM_ SG_ 602 ACU_RM_VR_RoofControlVD "Indicates signal ACU_RM_VR_RoofControl validity";
CM_ SG_ 602 ACU_RM_VR_RoofControl "Control the Roof and shade action by VR.";
CM_ SG_ 602 ACU_DM_VR_RRDMControlVD "Indicates signal ACU_DM_VR_RRDMControl validity";
CM_ SG_ 602 ACU_DM_VR_RLDMControlVD "Indicates signal ACU_DM_VR_RLDMControl validity";
CM_ SG_ 602 ACU_DM_VR_FRDMControlVD "Indicates signal ACU_DM_VR_FRDMControl validity";
CM_ SG_ 602 ACU_DM_VR_FLDMControlVD "Indicates signal ACU_DM_VR_FLDMControl validity";
CM_ SG_ 602 ACU_DM_VR_RRDMControl "Control the RR window moving by VR";
CM_ SG_ 602 ACU_DM_VR_RLDMControl "Control the RL window moving by VR";
CM_ SG_ 602 ACU_DM_VR_FRDMControl "Control the FR window moving by VR";
CM_ SG_ 602 ACU_DM_VR_FLDMControl "Control the FL window moving by VR";
CM_ SG_ 64 ACU_NaviCharacter "Navigation character information";
CM_ SG_ 902 ICM_FuelLevelVD "Fuel level sensor fault status";
CM_ SG_ 902 ICM_FuelLevel "Fuel level";
CM_ SG_ 902 ICM_Gaspedallvl "ICM gas pedal level";
CM_ SG_ 902 ICM_FuelLevel2VoltageRaw "Raw/Unprocessed signal for Fuel Level 2 (transfer side)";
CM_ SG_ 902 ICM_FuelLevel1VoltageRaw "Raw/Unprocessed signal for Fuel Level 1 (main side)";
CM_ SG_ 902 ICM_FuelSensor2Outofrange "Fuel level sensor2  value out of normal range";
CM_ SG_ 902 ICM_FuelSensor2ShortToGND "Fuel level sensor2 short to GND";
CM_ SG_ 902 ICM_FuelSensor2ShortToBatt "Fuel level sensor2 short to battry";
CM_ SG_ 902 ICM_FuelLevelEmpty "Fuel level is very low，almost empty";
CM_ SG_ 902 ICM_FuelSensorOutofrange "Fuel level sensor  value out of normal range";
CM_ SG_ 902 ICM_FuelSensor1ShortToGND "Fuel level sensor1 short to GND";
CM_ SG_ 902 ICM_FuelSensor1ShortToBatt "Fuel level sensor1 short to battry";
CM_ SG_ 902 ICM_FuelLevelLowSt "Fuel level low state";
CM_ SG_ 798 ICM_RearSeatBeltWarnCfgSt "turn on the rear seat belt warning  in ICM";
CM_ SG_ 798 ICM_FuelAvgConsumeTemp "ICM fuel average consumed at temporary";
CM_ SG_ 798 ICM_TotalOdometer_accurate "ODO value as accuracy of 0.1 km";
CM_ SG_ 798 ICM_LanguageCfgSt "ICM language configuration status";
CM_ SG_ 798 ICM_TimeModeCfgSt "ICM time mode configuration status";
CM_ SG_ 798 ICM_WarnSoundVolCfgSt "Warning sound volume configuration status";
CM_ SG_ 798 ICM_SpdWarnCfgSt "Speed warning configuration status";
CM_ SG_ 850 ICM_VehRunningTime "Vehicle running time";
CM_ SG_ 850 ICM_FuelEcoDistanceUnitDisp "Unit of fuel economy and distance display";
CM_ SG_ 850 ICM_PrUnitDisp "Unit of pressure display";
CM_ SG_ 850 ICM_TempUnitDisp "Unit of temperature display";
CM_ SG_ 850 ICM_BattVoltVD "Battery voltage valid data";
CM_ SG_ 850 ICM_BattVolt "Battery voltage";
CM_ SG_ 850 ICM_FuelInsConsumed "Engine's instantaneous fuel consumption";
CM_ SG_ 850 ICM_VehInsSpd "Vehicle instantaneous speed";
CM_ SG_ 851 ICM_AvaibleDriveDistance "The available driving distance according to the fuel";
CM_ SG_ 851 ICM_QDashACCFail "Error in the ACC message detected by the ICM, like timeout or alivecounter error.
The error should distinguish reversible and irreversible errors.";
CM_ SG_ 851 ICM_DisFail "Error in the display";
CM_ SG_ 851 ICM_FuelAverageConsumed "Engine's average fuel consumption";
CM_ SG_ 843 ICM_MaintenanceCycle "ICM maintenance reminder cycle";
CM_ SG_ 843 ICM_CancelMaintenanceSt "ICM sending out the repeated reminding status";
CM_ SG_ 843 ICM_MaintenanceReset "ICM reset maintenance reminder";
CM_ SG_ 843 ICM_BFLWarning "Brake fluid level signal status";
CM_ SG_ 843 ICM_DispButtonSt "Display button status";
CM_ SG_ 843 ICM_BackLightLevel "Back light level";
CM_ SG_ 843 ICM_OilPrSt "Oil pressure signal status";
CM_ SG_ 843 ICM_FuelLevel "Fuel level";
CM_ SG_ 843 ICM_TotalOdometer "Total odometer";
CM_ SG_ 843 ICM_TPMSDriverResetReq "For sending the TPMS reset request to ESC";
CM_ SG_ 843 ICM_WFLWarning "Washer fluid level signal status";
CM_ SG_ 843 ICM_ChargingSt "Battery charging signal status";
CM_ SG_ 843 ICM_FuelLevelVD "Fuel level sensor fault status";
CM_ SG_ 843 ICM_AirbagLampFaultSt "Airbag warning lamp fault status";
CM_ SG_ 843 ICM_VehicleBrakeSt "Indicate the vehicle brake status,ICM judge from the Hand brake status or the EPB brake status";
CM_ SG_ 662 ICM_SetIACCSt "ICM set IACC Status";
CM_ SG_ 662 ICM_Type "Type of ICM";
CM_ SG_ 662 ICM_SoundWarnSilenceReq "ICM have some important sound warning,need ACU keep mute";
CM_ SG_ 662 ICM_MFSButtonSt "The button's status of ICM operated by user";
CM_ SG_ 662 ICM_DriveMode "Drive mode of ICM's current display";
CM_ SG_ 662 ICM_DispTheme "Theme of ICM's current display";
CM_ SG_ 662 ICM_DisplayID "Main interface of ICM's current display";
CM_ SG_ 662 ICM_APAParkNoticeFeedbackVD "Signal_ICM_APAParkNoticeFeedback_Validity";
CM_ SG_ 662 ICM_APAParkNoticeFeedback "APA park notice feedback";
CM_ SG_ 1963 ACU_Diag_Response "Diagnostic  response";
CM_ SG_ 156 ACU_ANC_SwitchStatus "ANC_SwitchStatus";
CM_ SG_ 156 ACU_Headrest_Mode "Headrest_Mode";
CM_ SG_ 156 ACU_SoundmodeSet "SoundmodeSet";
CM_ SG_ 156 ACU_A2BSet "ACU_A2BSet";
CM_ SG_ 156 ACU_ESESts "ESESts";
CM_ SG_ 156 ACU_ICCSts "ICCSts";
CM_ SG_ 156 ACU_YamahaSoundMode "Yamaha Sound effect Mode";
CM_ SG_ 156 ACU_AdigoVirtualLiveSetReq "Adigo_VirtualLiveSet_Request";
CM_ SG_ 156 ACU_StrSurSet "Stereo or surround set.";
CM_ SG_ 156 ACU_HeadrestRightVolumeReq "Headrest Right Private Mode Volume Request";
CM_ SG_ 156 ACU_HeadrestLeftVolumeReq "Headrest_Left_PrivateModeVolumeRequest";
CM_ SG_ 156 ACU_HeadrestPrivateModeMuteReq "Headrest (Left or Right) Private Mode Volume Request";
CM_ SG_ 156 ACU_VRSourceSet "VR source set.";
CM_ SG_ 156 ACU_TelSourceSet "Telephone source set.";
CM_ SG_ 156 ACU_WarningSourceSet "Warningsource set.";
CM_ SG_ 156 ACU_MediaSourceSet "Media Source Set";
CM_ SG_ 185 ACU_SetEqMode "Set EQ mode.";
CM_ SG_ 185 ACU_GetIntVoltReq "Get internal working voltage of AMP";
CM_ SG_ 185 ACU_GetTempReq "Get internal temperature of AMP";
CM_ SG_ 185 ACU_MainVolSet "Main volume adjustment";
CM_ SG_ 185 ACU_NaviVolSet "Navi volume adjustment";
CM_ SG_ 185 ACU_VRVolSet "VR/TTS(text to sound).";
CM_ SG_ 185 ACU_TelVolSet "HFM(hand free mode), RT(ring tone) and Tbox-I/B call volume set.";
CM_ SG_ 186 ACU_SpeakMid "Mid speaker";
CM_ SG_ 186 ACU_SpeakRR "RR speaker";
CM_ SG_ 186 ACU_SpeakRL "RL speaker";
CM_ SG_ 186 ACU_SpeakFR "FR speaker";
CM_ SG_ 186 ACU_SpeakFL "FL speaker";
CM_ SG_ 186 ACU_ClariFiSet "Clari-Fi Status request.";
CM_ SG_ 186 ACU_PowerSet "AMP power set. When the systerm power mode (from PEPS or BCM)change to OFF,the bluetooh communication should't be interrupted ,so AMP need this signal to turn off.";
CM_ SG_ 186 ACU_HighFrqSet "High frequency audio set";
CM_ SG_ 186 ACU_TEL_ECallSet "T_box Ecall(emergency call)  set.";
CM_ SG_ 186 ACU_MuteRearSet "Mute rear speakers";
CM_ SG_ 186 ACU_MuteSet "Mute all speakers";
CM_ SG_ 186 ACU_DrvSideSet "Drive side set(Left helm drive or right helm drive).";
CM_ SG_ 186 ACU_MidFrqSet "Mid frequency audio set";
CM_ SG_ 186 ACU_LowFrqSet "Low frequency audio set";
CM_ SG_ 186 ACU_VSCModeReq "Vehicle Speed Compensation mode(on/off) request.";
CM_ SG_ 186 ACU_NaviSourceSet "Navi source set.";
CM_ SG_ 186 ACU_FaderSet "Front/rear audio fader set";
CM_ SG_ 186 ACU_BeepSourceSet "Beep source set.";
CM_ SG_ 186 ACU_BlcSet "Left/Right Audio Balance set";
CM_ SG_ 1067 ACU_NMWakeupOrigin "Origin of the wake up";
CM_ SG_ 72 ACU_PLGMFuncCfg "Configurates power lift gate function";
CM_ SG_ 72 ACU_PLGMTrunkReleaseReq "Power lift gate release request";
CM_ SG_ 72 ACU_PLGMMaxPstReq "Power lift gate Maximum position setting request";
CM_ SG_ 72 ACU_PLGMSetPstClearReq "PLGM set position clear requset(clear = set to 100%)";
CM_ SG_ 72 ACU_PLGMCloseReqVD "AVNT_PLGMCloseReq valid value";
CM_ SG_ 72 ACU_PLGMCloseReq "PLGM(Power Liftgate Module) close request";
CM_ SG_ 72 ACU_PLGMOpenReqVD "AVNT_PLGMOpenReq valid value";
CM_ SG_ 72 ACU_PLGMOpenReq "PLGM(Power Liftgate Module) open request";
CM_ SG_ 72 ACU_PLGMCtrl "Power lift gate position control";
BA_DEF_ SG_  "Remark" STRING ;
BA_DEF_ SG_  "EventCommandSignal" ENUM  "No","Yes";
BA_DEF_ SG_  "GatewayedSignals" ENUM  "No","Yes";
BA_DEF_ SG_  "GenSigTimeoutValue" INT 0 0;
BA_DEF_ SG_  "GenSigStartValue" INT 0 0;
BA_DEF_ SG_  "GenSigInvalidValue" INT 0 0;
BA_DEF_ SG_  "GenSigInactiveValue" INT 0 0;
BA_DEF_ BO_  "GenMsgCycleTimeFast" INT 0 0;
BA_DEF_ BO_  "GenMsgCycleTime" INT 0 0;
BA_DEF_ SG_  "GenSigSendType" ENUM  "Trigger","Passive";
BA_DEF_ BO_  "GenMsgSendType" ENUM  "Periodic","Event","IfActive","POE","PA";
BA_DEF_ SG_  "SystemSignalLongSymbol" STRING ;
BA_DEF_DEF_  "Remark" "*";
BA_DEF_DEF_  "EventCommandSignal" "No";
BA_DEF_DEF_  "GatewayedSignals" "No";
BA_DEF_DEF_  "GenSigTimeoutValue" 0;
BA_DEF_DEF_  "GenSigStartValue" 0;
BA_DEF_DEF_  "GenSigInvalidValue" 0;
BA_DEF_DEF_  "GenSigInactiveValue" 0;
BA_DEF_DEF_  "GenMsgCycleTimeFast" 0;
BA_DEF_DEF_  "GenMsgCycleTime" 0;
BA_DEF_DEF_  "GenSigSendType" "Trigger";
BA_DEF_DEF_  "GenMsgSendType" "Periodic";
BA_DEF_DEF_  "SystemSignalLongSymbol" "";
BA_ "GenMsgCycleTime" BO_ 796 500;
BA_ "GenMsgCycleTime" BO_ 605 20;
BA_ "GenMsgCycleTime" BO_ 792 100;
BA_ "GenMsgCycleTime" BO_ 1538 1000;
BA_ "GenMsgCycleTime" BO_ 949 200;
BA_ "GenMsgCycleTime" BO_ 994 100;
BA_ "GenMsgCycleTime" BO_ 760 75;
BA_ "GenMsgCycleTime" BO_ 443 20;
BA_ "GenMsgCycleTime" BO_ 725 100;
BA_ "GenMsgCycleTime" BO_ 984 100;
BA_ "GenMsgCycleTime" BO_ 590 50;
BA_ "GenMsgCycleTime" BO_ 589 50;
BA_ "GenMsgCycleTime" BO_ 588 50;
BA_ "GenMsgCycleTime" BO_ 993 50;
BA_ "GenMsgCycleTime" BO_ 992 50;
BA_ "GenMsgCycleTime" BO_ 991 50;
BA_ "GenMsgCycleTime" BO_ 931 50;
BA_ "GenMsgCycleTime" BO_ 735 100;
BA_ "GenMsgCycleTime" BO_ 890 50;
BA_ "GenMsgSendType" BO_ 102 1;
BA_ "GenMsgCycleTime" BO_ 967 200;
BA_ "GenMsgCycleTime" BO_ 666 100;
BA_ "GenMsgCycleTime" BO_ 730 100;
BA_ "GenMsgCycleTime" BO_ 355 100;
BA_ "GenMsgCycleTime" BO_ 839 100;
BA_ "GenMsgCycleTime" BO_ 835 100;
BA_ "GenMsgCycleTime" BO_ 651 50;
BA_ "GenMsgSendType" BO_ 117 1;
BA_ "GenMsgSendType" BO_ 602 4;
BA_ "GenMsgCycleTimeFast" BO_ 602 40;
BA_ "GenMsgCycleTime" BO_ 602 500;
BA_ "GenMsgSendType" BO_ 64 1;
BA_ "GenMsgCycleTime" BO_ 902 100;
BA_ "GenMsgCycleTime" BO_ 798 500;
BA_ "GenMsgCycleTime" BO_ 850 200;
BA_ "GenMsgCycleTime" BO_ 851 100;
BA_ "GenMsgCycleTime" BO_ 843 200;
BA_ "GenMsgCycleTime" BO_ 662 50;
BA_ "GenMsgSendType" BO_ 156 1;
BA_ "GenMsgSendType" BO_ 185 1;
BA_ "GenMsgSendType" BO_ 186 1;
BA_ "GenMsgSendType" BO_ 72 1;
BA_ "Remark" SG_ 796 BCM_RLSAutoSRWinCloseCfgSt "";
BA_ "GenSigSendType" SG_ 796 BCM_RLSAutoSRWinCloseCfgSt 1;
BA_ "Remark" SG_ 796 BCM_AutoSRWinCloseCfgSt "";
BA_ "GenSigSendType" SG_ 796 BCM_AutoSRWinCloseCfgSt 1;
BA_ "GenSigStartValue" SG_ 796 BCM_AutoSRWinCloseCfgSt 1;
BA_ "Remark" SG_ 796 BCM_HeadlightDelayCfgSt "";
BA_ "GenSigSendType" SG_ 796 BCM_HeadlightDelayCfgSt 1;
BA_ "Remark" SG_ 796 BCM_IGNOffTime "";
BA_ "GenSigSendType" SG_ 796 BCM_IGNOffTime 1;
BA_ "Remark" SG_ 796 BCM_IGNOffTimeVD "";
BA_ "GenSigSendType" SG_ 796 BCM_IGNOffTimeVD 1;
BA_ "Remark" SG_ 796 BCM_AutoDomeLightCfgSt "";
BA_ "GenSigSendType" SG_ 796 BCM_AutoDomeLightCfgSt 1;
BA_ "Remark" SG_ 796 BCM_AutoWiperCfgSt "";
BA_ "GenSigSendType" SG_ 796 BCM_AutoWiperCfgSt 1;
BA_ "Remark" SG_ 796 BCM_IALFuncCfgSt "";
BA_ "GenSigSendType" SG_ 796 BCM_IALFuncCfgSt 1;
BA_ "GenSigStartValue" SG_ 796 BCM_IALFuncCfgSt 1;
BA_ "Remark" SG_ 796 BCM_OSRMAutoFoldCfgSt "";
BA_ "GenSigSendType" SG_ 796 BCM_OSRMAutoFoldCfgSt 1;
BA_ "GenSigStartValue" SG_ 796 BCM_OSRMAutoFoldCfgSt 1;
BA_ "Remark" SG_ 796 BCM_HornCfgSt "";
BA_ "GenSigSendType" SG_ 796 BCM_HornCfgSt 1;
BA_ "GenSigStartValue" SG_ 796 BCM_HornCfgSt 1;
BA_ "Remark" SG_ 796 BCM_DTRLFuncCfgSt "";
BA_ "GenSigSendType" SG_ 796 BCM_DTRLFuncCfgSt 1;
BA_ "GenSigStartValue" SG_ 796 BCM_DTRLFuncCfgSt 1;
BA_ "Remark" SG_ 796 BCM_RGearEnableRearWipeCfgSt "";
BA_ "GenSigSendType" SG_ 796 BCM_RGearEnableRearWipeCfgSt 1;
BA_ "GenSigStartValue" SG_ 796 BCM_RGearEnableRearWipeCfgSt 1;
BA_ "Remark" SG_ 796 BCM_FrontWiperSerPstFuncCfgSt "";
BA_ "GenSigSendType" SG_ 796 BCM_FrontWiperSerPstFuncCfgSt 1;
BA_ "GenSigStartValue" SG_ 796 BCM_FrontWiperSerPstFuncCfgSt 1;
BA_ "Remark" SG_ 796 BCM_AutoLightSnsCfgSt "";
BA_ "GenSigSendType" SG_ 796 BCM_AutoLightSnsCfgSt 1;
BA_ "GenSigStartValue" SG_ 796 BCM_AutoLightSnsCfgSt 2;
BA_ "Remark" SG_ 796 BCM_FollowMeHomeCfgSt "";
BA_ "GenSigSendType" SG_ 796 BCM_FollowMeHomeCfgSt 1;
BA_ "GenSigStartValue" SG_ 796 BCM_FollowMeHomeCfgSt 1;
BA_ "Remark" SG_ 796 BCM_AutoUnlockCfgSt "";
BA_ "GenSigSendType" SG_ 796 BCM_AutoUnlockCfgSt 1;
BA_ "Remark" SG_ 796 BCM_SpdAutoLockCfgSt "";
BA_ "GenSigSendType" SG_ 796 BCM_SpdAutoLockCfgSt 1;
BA_ "Remark" SG_ 796 BCM_RemoteUnlockCfgSt "";
BA_ "GenSigSendType" SG_ 796 BCM_RemoteUnlockCfgSt 1;
BA_ "Remark" SG_ 796 BCM_FogLampTurnCfgSt "";
BA_ "GenSigSendType" SG_ 796 BCM_FogLampTurnCfgSt 1;
BA_ "GenSigStartValue" SG_ 796 BCM_FogLampTurnCfgSt 1;
BA_ "Remark" SG_ 796 BCM_RemoteCtrlFDMRMCfgSt "";
BA_ "GenSigSendType" SG_ 796 BCM_RemoteCtrlFDMRMCfgSt 1;
BA_ "GenSigStartValue" SG_ 796 BCM_RemoteCtrlFDMRMCfgSt 1;
BA_ "Remark" SG_ 605 BCM_CentralLockSWSt "";
BA_ "GatewayedSignals" SG_ 605 BCM_CentralLockSWSt 1;
BA_ "GenSigSendType" SG_ 605 BCM_CentralLockSWSt 1;
BA_ "Remark" SG_ 605 BCM_InteriorTrunkReleaseSwitch "";
BA_ "GatewayedSignals" SG_ 605 BCM_InteriorTrunkReleaseSwitch 1;
BA_ "GenSigSendType" SG_ 605 BCM_InteriorTrunkReleaseSwitch 1;
BA_ "Remark" SG_ 605 BCM_MainLampSwitchSt "";
BA_ "GatewayedSignals" SG_ 605 BCM_MainLampSwitchSt 1;
BA_ "GenSigSendType" SG_ 605 BCM_MainLampSwitchSt 1;
BA_ "GenSigStartValue" SG_ 605 BCM_MainLampSwitchSt 1;
BA_ "Remark" SG_ 605 BCM_BeamSwitchSt "";
BA_ "GatewayedSignals" SG_ 605 BCM_BeamSwitchSt 1;
BA_ "GenSigSendType" SG_ 605 BCM_BeamSwitchSt 1;
BA_ "GenSigStartValue" SG_ 605 BCM_BeamSwitchSt 1;
BA_ "Remark" SG_ 605 BCM_AutoHighBeamCtrlSt "";
BA_ "GatewayedSignals" SG_ 605 BCM_AutoHighBeamCtrlSt 1;
BA_ "GenSigSendType" SG_ 605 BCM_AutoHighBeamCtrlSt 1;
BA_ "Remark" SG_ 605 BCM_RightTurnLampFaultSt "";
BA_ "GatewayedSignals" SG_ 605 BCM_RightTurnLampFaultSt 1;
BA_ "GenSigSendType" SG_ 605 BCM_RightTurnLampFaultSt 1;
BA_ "Remark" SG_ 605 BCM_RightTurnLampSt "";
BA_ "GatewayedSignals" SG_ 605 BCM_RightTurnLampSt 1;
BA_ "GenSigSendType" SG_ 605 BCM_RightTurnLampSt 1;
BA_ "Remark" SG_ 605 BCM_LeftTurnLampFaultSt "";
BA_ "GatewayedSignals" SG_ 605 BCM_LeftTurnLampFaultSt 1;
BA_ "GenSigSendType" SG_ 605 BCM_LeftTurnLampFaultSt 1;
BA_ "Remark" SG_ 605 BCM_LeftTurnLampSt "";
BA_ "GatewayedSignals" SG_ 605 BCM_LeftTurnLampSt 1;
BA_ "GenSigSendType" SG_ 605 BCM_LeftTurnLampSt 1;
BA_ "Remark" SG_ 605 BCM_LowBeamFaultSt "";
BA_ "GatewayedSignals" SG_ 605 BCM_LowBeamFaultSt 1;
BA_ "GenSigSendType" SG_ 605 BCM_LowBeamFaultSt 1;
BA_ "Remark" SG_ 605 BCM_PositionLightFaultSt "";
BA_ "GatewayedSignals" SG_ 605 BCM_PositionLightFaultSt 1;
BA_ "GenSigSendType" SG_ 605 BCM_PositionLightFaultSt 1;
BA_ "Remark" SG_ 605 BCM_PositionLightswitchSt "";
BA_ "GatewayedSignals" SG_ 605 BCM_PositionLightswitchSt 1;
BA_ "GenSigSendType" SG_ 605 BCM_PositionLightswitchSt 1;
BA_ "Remark" SG_ 605 BCM_BrakeLightFaultSt "";
BA_ "GatewayedSignals" SG_ 605 BCM_BrakeLightFaultSt 1;
BA_ "GenSigSendType" SG_ 605 BCM_BrakeLightFaultSt 1;
BA_ "Remark" SG_ 605 BCM_DRLRFaultSt "";
BA_ "GatewayedSignals" SG_ 605 BCM_DRLRFaultSt 1;
BA_ "GenSigSendType" SG_ 605 BCM_DRLRFaultSt 1;
BA_ "Remark" SG_ 605 BCM_DRLLFaultSt "";
BA_ "GatewayedSignals" SG_ 605 BCM_DRLLFaultSt 1;
BA_ "GenSigSendType" SG_ 605 BCM_DRLLFaultSt 1;
BA_ "Remark" SG_ 605 BCM_RearWasherSt "";
BA_ "GatewayedSignals" SG_ 605 BCM_RearWasherSt 1;
BA_ "GenSigSendType" SG_ 605 BCM_RearWasherSt 1;
BA_ "Remark" SG_ 605 BCM_ReverseSwitchSt "";
BA_ "GatewayedSignals" SG_ 605 BCM_ReverseSwitchSt 1;
BA_ "GenSigSendType" SG_ 605 BCM_ReverseSwitchSt 1;
BA_ "Remark" SG_ 605 BCM_RearWiperSt "";
BA_ "GatewayedSignals" SG_ 605 BCM_RearWiperSt 1;
BA_ "GenSigSendType" SG_ 605 BCM_RearWiperSt 1;
BA_ "Remark" SG_ 605 BCM_DTRLSt "";
BA_ "GenSigSendType" SG_ 605 BCM_DTRLSt 1;
BA_ "Remark" SG_ 605 BCM_FrontWiperSt "";
BA_ "GatewayedSignals" SG_ 605 BCM_FrontWiperSt 1;
BA_ "GenSigSendType" SG_ 605 BCM_FrontWiperSt 1;
BA_ "Remark" SG_ 792 RLS_LightSwitchReason "";
BA_ "GenSigSendType" SG_ 792 RLS_LightSwitchReason 1;
BA_ "GenSigInvalidValue" SG_ 792 RLS_LightSwitchReason 15;
BA_ "GenSigStartValue" SG_ 792 RLS_LightSwitchReason 15;
BA_ "Remark" SG_ 792 BCM_RemoteControlSt "";
BA_ "GenSigSendType" SG_ 792 BCM_RemoteControlSt 1;
BA_ "Remark" SG_ 792 BCM_HornSt "";
BA_ "GenSigSendType" SG_ 792 BCM_HornSt 1;
BA_ "Remark" SG_ 792 BCM_FOB_ID "";
BA_ "GenSigSendType" SG_ 792 BCM_FOB_ID 1;
BA_ "Remark" SG_ 792 BCM_DRLRFaultSt "";
BA_ "GenSigSendType" SG_ 792 BCM_DRLRFaultSt 1;
BA_ "Remark" SG_ 792 BCM_DRLLFaultSt "";
BA_ "GenSigSendType" SG_ 792 BCM_DRLLFaultSt 1;
BA_ "Remark" SG_ 792 BCM_FrontWasherSt "";
BA_ "GenSigSendType" SG_ 792 BCM_FrontWasherSt 1;
BA_ "Remark" SG_ 792 BCM_SunRoofPstSt "";
BA_ "GenSigSendType" SG_ 792 BCM_SunRoofPstSt 1;
BA_ "Remark" SG_ 792 BCM_WinMoveSt "";
BA_ "GenSigSendType" SG_ 792 BCM_WinMoveSt 1;
BA_ "GenSigInvalidValue" SG_ 792 BCM_WinMoveSt 3;
BA_ "Remark" SG_ 792 BCM_ETWS_St "";
BA_ "GenSigSendType" SG_ 792 BCM_ETWS_St 1;
BA_ "Remark" SG_ 792 BCM_RoomlampSt "";
BA_ "GenSigSendType" SG_ 792 BCM_RoomlampSt 1;
BA_ "Remark" SG_ 792 BCM_PsngrDoorLockSt "";
BA_ "GenSigSendType" SG_ 792 BCM_PsngrDoorLockSt 1;
BA_ "Remark" SG_ 792 BCM_DriverDoorLockSt "";
BA_ "GenSigSendType" SG_ 792 BCM_DriverDoorLockSt 1;
BA_ "Remark" SG_ 792 BCM_ATWS_St "";
BA_ "GenSigSendType" SG_ 792 BCM_ATWS_St 1;
BA_ "GenSigStartValue" SG_ 792 BCM_ATWS_St 2;
BA_ "Remark" SG_ 792 BCM_AlarmHistory "";
BA_ "GenSigSendType" SG_ 792 BCM_AlarmHistory 1;
BA_ "GenSigStartValue" SG_ 792 BCM_AlarmHistory 7;
BA_ "Remark" SG_ 792 BCM_KeyInsertSt "";
BA_ "GenSigSendType" SG_ 792 BCM_KeyInsertSt 1;
BA_ "Remark" SG_ 792 BCM_KeyInReminderWarnReq "";
BA_ "GenSigSendType" SG_ 792 BCM_KeyInReminderWarnReq 1;
BA_ "Remark" SG_ 792 BCM_RmtCtrlFobBattLow "";
BA_ "GenSigSendType" SG_ 792 BCM_RmtCtrlFobBattLow 1;
BA_ "Remark" SG_ 792 BCM_TransportModeSt "";
BA_ "GenSigSendType" SG_ 792 BCM_TransportModeSt 1;
BA_ "Remark" SG_ 792 BCM_SunRoofOpenWarning "";
BA_ "GenSigSendType" SG_ 792 BCM_SunRoofOpenWarning 1;
BA_ "Remark" SG_ 792 BCM_VehReverseSt "";
BA_ "GenSigSendType" SG_ 792 BCM_VehReverseSt 1;
BA_ "Remark" SG_ 792 BCM_BrakeLightSwitchSt "";
BA_ "GenSigSendType" SG_ 792 BCM_BrakeLightSwitchSt 1;
BA_ "Remark" SG_ 792 BCM_ParkingLampSt "";
BA_ "GatewayedSignals" SG_ 792 BCM_ParkingLampSt 1;
BA_ "GenSigSendType" SG_ 792 BCM_ParkingLampSt 1;
BA_ "Remark" SG_ 792 BCM_RearFogLampSt "";
BA_ "GenSigSendType" SG_ 792 BCM_RearFogLampSt 1;
BA_ "Remark" SG_ 792 BCM_FrontFogLampSt "";
BA_ "GenSigSendType" SG_ 792 BCM_FrontFogLampSt 1;
BA_ "Remark" SG_ 792 BCM_HighBeamSt "";
BA_ "GenSigSendType" SG_ 792 BCM_HighBeamSt 1;
BA_ "Remark" SG_ 792 BCM_LowBeamSt "";
BA_ "GenSigSendType" SG_ 792 BCM_LowBeamSt 1;
BA_ "Remark" SG_ 792 BCM_RightTurnLampFaultSt "";
BA_ "GenSigSendType" SG_ 792 BCM_RightTurnLampFaultSt 1;
BA_ "Remark" SG_ 792 BCM_RightTurnLampSt "";
BA_ "GenSigSendType" SG_ 792 BCM_RightTurnLampSt 1;
BA_ "Remark" SG_ 792 BCM_LeftTurnLampFaultSt "";
BA_ "GenSigSendType" SG_ 792 BCM_LeftTurnLampFaultSt 1;
BA_ "Remark" SG_ 792 BCM_LeftTurnLampSt "";
BA_ "GenSigSendType" SG_ 792 BCM_LeftTurnLampSt 1;
BA_ "Remark" SG_ 792 BCM_DTRLSt "";
BA_ "GenSigSendType" SG_ 792 BCM_DTRLSt 1;
BA_ "Remark" SG_ 792 BCM_TrunkReleaseCmd "";
BA_ "GenSigSendType" SG_ 792 BCM_TrunkReleaseCmd 1;
BA_ "Remark" SG_ 792 BCM_TrunkAjarSt "";
BA_ "GenSigSendType" SG_ 792 BCM_TrunkAjarSt 1;
BA_ "Remark" SG_ 792 BCM_BonnetAjarSt "";
BA_ "GenSigSendType" SG_ 792 BCM_BonnetAjarSt 1;
BA_ "Remark" SG_ 792 BCM_RRDoorAjarSt "";
BA_ "GenSigSendType" SG_ 792 BCM_RRDoorAjarSt 1;
BA_ "Remark" SG_ 792 BCM_RLDoorAjarSt "";
BA_ "GenSigSendType" SG_ 792 BCM_RLDoorAjarSt 1;
BA_ "Remark" SG_ 792 BCM_PsngrDoorAjarSt "";
BA_ "GenSigSendType" SG_ 792 BCM_PsngrDoorAjarSt 1;
BA_ "Remark" SG_ 792 BCM_DriverDoorAjarSt "";
BA_ "GenSigSendType" SG_ 792 BCM_DriverDoorAjarSt 1;
BA_ "Remark" SG_ 792 BCM_LampOnWarningReq "";
BA_ "GenSigSendType" SG_ 792 BCM_LampOnWarningReq 1;
BA_ "Remark" SG_ 792 BCM_PGearSt "";
BA_ "GenSigSendType" SG_ 792 BCM_PGearSt 1;
BA_ "GenSigStartValue" SG_ 792 BCM_PGearSt 1;
BA_ "Remark" SG_ 792 BCM_KeySt "";
BA_ "GatewayedSignals" SG_ 792 BCM_KeySt 1;
BA_ "GenSigSendType" SG_ 792 BCM_KeySt 1;
BA_ "Remark" SG_ 1835 ACU_Diag_Request "";
BA_ "GenSigSendType" SG_ 1835 ACU_Diag_Request 1;
BA_ "Remark" SG_ 1109 ETC_NMDataField "";
BA_ "GenSigSendType" SG_ 1109 ETC_NMDataField 1;
BA_ "Remark" SG_ 1109 ETC_NMWakeupOrigin "";
BA_ "GenSigSendType" SG_ 1109 ETC_NMWakeupOrigin 1;
BA_ "Remark" SG_ 1109 ETC_NMSleepAck "";
BA_ "GenSigSendType" SG_ 1109 ETC_NMSleepAck 1;
BA_ "Remark" SG_ 1109 ETC_NMSleepInd "";
BA_ "GenSigSendType" SG_ 1109 ETC_NMSleepInd 1;
BA_ "Remark" SG_ 1109 ETC_NMLimpHome "";
BA_ "GenSigSendType" SG_ 1109 ETC_NMLimpHome 1;
BA_ "Remark" SG_ 1109 ETC_NMRing "";
BA_ "GenSigSendType" SG_ 1109 ETC_NMRing 1;
BA_ "Remark" SG_ 1109 ETC_NMAlive "";
BA_ "GenSigSendType" SG_ 1109 ETC_NMAlive 1;
BA_ "Remark" SG_ 1109 ETC_NMDestAddress "";
BA_ "GenSigSendType" SG_ 1109 ETC_NMDestAddress 1;
BA_ "Remark" SG_ 1538 ETC_BLEenableCfgst "";
BA_ "GenSigSendType" SG_ 1538 ETC_BLEenableCfgst 1;
BA_ "GenSigStartValue" SG_ 1538 ETC_BLEenableCfgst 1;
BA_ "Remark" SG_ 1538 ETC_ICMDisplayCfgst "";
BA_ "GenSigSendType" SG_ 1538 ETC_ICMDisplayCfgst 1;
BA_ "GenSigStartValue" SG_ 1538 ETC_ICMDisplayCfgst 1;
BA_ "Remark" SG_ 1538 ETC_SysCfgst "";
BA_ "GenSigSendType" SG_ 1538 ETC_SysCfgst 1;
BA_ "GenSigStartValue" SG_ 1538 ETC_SysCfgst 1;
BA_ "Remark" SG_ 1538 ETC_TradeInfo "";
BA_ "GenSigSendType" SG_ 1538 ETC_TradeInfo 1;
BA_ "Remark" SG_ 1538 ETC_SystemSt "";
BA_ "GenSigSendType" SG_ 1538 ETC_SystemSt 1;
BA_ "Remark" SG_ 1538 ETC_TradeType "";
BA_ "GenSigSendType" SG_ 1538 ETC_TradeType 1;
BA_ "GenSigStartValue" SG_ 1538 ETC_TradeType 1;
BA_ "Remark" SG_ 1538 ETC_GateProperty "";
BA_ "GenSigSendType" SG_ 1538 ETC_GateProperty 1;
BA_ "Remark" SG_ 1538 ETC_SelfcheckSt "";
BA_ "GenSigSendType" SG_ 1538 ETC_SelfcheckSt 1;
BA_ "Remark" SG_ 1538 ETC_DismountSt "";
BA_ "GenSigSendType" SG_ 1538 ETC_DismountSt 1;
BA_ "Remark" SG_ 1096 WCM_NMDataField "";
BA_ "GenSigSendType" SG_ 1096 WCM_NMDataField 1;
BA_ "Remark" SG_ 1096 WCM_NMWakeupOrigin "";
BA_ "GenSigSendType" SG_ 1096 WCM_NMWakeupOrigin 1;
BA_ "Remark" SG_ 1096 WCM_NMSleepAck "";
BA_ "GenSigSendType" SG_ 1096 WCM_NMSleepAck 1;
BA_ "Remark" SG_ 1096 WCM_NMSleepInd "";
BA_ "GenSigSendType" SG_ 1096 WCM_NMSleepInd 1;
BA_ "Remark" SG_ 1096 WCM_NMLimpHome "";
BA_ "GenSigSendType" SG_ 1096 WCM_NMLimpHome 1;
BA_ "Remark" SG_ 1096 WCM_NMRing "";
BA_ "GenSigSendType" SG_ 1096 WCM_NMRing 1;
BA_ "Remark" SG_ 1096 WCM_NMAlive "";
BA_ "GenSigSendType" SG_ 1096 WCM_NMAlive 1;
BA_ "Remark" SG_ 1096 WCM_NMDestAddress "";
BA_ "GenSigSendType" SG_ 1096 WCM_NMDestAddress 1;
BA_ "Remark" SG_ 949 WCM_Reminder "";
BA_ "GenSigSendType" SG_ 949 WCM_Reminder 1;
BA_ "Remark" SG_ 949 WCM_FailureSt "";
BA_ "GenSigSendType" SG_ 949 WCM_FailureSt 1;
BA_ "Remark" SG_ 949 WCM_ControlResult "";
BA_ "GenSigSendType" SG_ 949 WCM_ControlResult 1;
BA_ "Remark" SG_ 949 WCM_ChargingSt "";
BA_ "GenSigSendType" SG_ 949 WCM_ChargingSt 1;
BA_ "GenSigSendType" SG_ 994 ADAS_HWA_ILCWaitReasonLeft 1;
BA_ "Remark" SG_ 994 ADAS_TrkTargt3latPos "";
BA_ "GenSigSendType" SG_ 994 ADAS_TrkTargt3latPos 1;
BA_ "GenSigInvalidValue" SG_ 994 ADAS_TrkTargt3latPos 1023;
BA_ "GenSigStartValue" SG_ 994 ADAS_TrkTargt3latPos 512;
BA_ "Remark" SG_ 994 ADAS_TrkTargt3longPos "";
BA_ "GenSigSendType" SG_ 994 ADAS_TrkTargt3longPos 1;
BA_ "GenSigInvalidValue" SG_ 994 ADAS_TrkTargt3longPos 255;
BA_ "Remark" SG_ 994 ADAS_TrkTargt3St "";
BA_ "GenSigSendType" SG_ 994 ADAS_TrkTargt3St 1;
BA_ "Remark" SG_ 994 ADAS_TrkTargt3ObjClass "";
BA_ "GenSigSendType" SG_ 994 ADAS_TrkTargt3ObjClass 1;
BA_ "Remark" SG_ 994 IFC_ELKWarnR "";
BA_ "GenSigSendType" SG_ 994 IFC_ELKWarnR 1;
BA_ "Remark" SG_ 994 IFC_ELKWarnL "";
BA_ "GenSigSendType" SG_ 994 IFC_ELKWarnL 1;
BA_ "Remark" SG_ 994 IFC_ELKSt "";
BA_ "GenSigSendType" SG_ 994 IFC_ELKSt 1;
BA_ "GenSigInvalidValue" SG_ 994 IFC_ELKSt 3;
BA_ "Remark" SG_ 994 ADAS_AdjRLnMrkingDispSt "";
BA_ "GenSigSendType" SG_ 994 ADAS_AdjRLnMrkingDispSt 1;
BA_ "Remark" SG_ 760 PADS_ICM_MenuBtnStVD "";
BA_ "GenSigSendType" SG_ 760 PADS_ICM_MenuBtnStVD 1;
BA_ "Remark" SG_ 760 PADS_ICM_MenuBtnSt "";
BA_ "GenSigSendType" SG_ 760 PADS_ICM_MenuBtnSt 1;
BA_ "Remark" SG_ 760 PADS_ACU_CusBtnStVD "";
BA_ "GenSigSendType" SG_ 760 PADS_ACU_CusBtnStVD 1;
BA_ "Remark" SG_ 760 PADS_ACU_CusBtnSt "";
BA_ "GenSigSendType" SG_ 760 PADS_ACU_CusBtnSt 1;
BA_ "Remark" SG_ 760 PADS_ACU_WechatBtnStVD "";
BA_ "GenSigSendType" SG_ 760 PADS_ACU_WechatBtnStVD 1;
BA_ "Remark" SG_ 760 PADS_ACU_WechatBtnSt "";
BA_ "GenSigSendType" SG_ 760 PADS_ACU_WechatBtnSt 1;
BA_ "Remark" SG_ 760 PADS_ICM_SkipslideBtnSt "";
BA_ "GenSigSendType" SG_ 760 PADS_ICM_SkipslideBtnSt 1;
BA_ "Remark" SG_ 760 PADS_ICM_OkBtnStVD "";
BA_ "GenSigSendType" SG_ 760 PADS_ICM_OkBtnStVD 1;
BA_ "Remark" SG_ 760 PADS_ICM_OkBtnSt "";
BA_ "GenSigSendType" SG_ 760 PADS_ICM_OkBtnSt 1;
BA_ "Remark" SG_ 760 PADS_ICM_DowmBtnStVD "";
BA_ "GenSigSendType" SG_ 760 PADS_ICM_DowmBtnStVD 1;
BA_ "Remark" SG_ 760 PADS_ICM_DowmBtnSt "";
BA_ "GenSigSendType" SG_ 760 PADS_ICM_DowmBtnSt 1;
BA_ "Remark" SG_ 760 PADS_ICM_UpBtnStVD "";
BA_ "GenSigSendType" SG_ 760 PADS_ICM_UpBtnStVD 1;
BA_ "Remark" SG_ 760 PADS_ICM_UpBtnSt "";
BA_ "GenSigSendType" SG_ 760 PADS_ICM_UpBtnSt 1;
BA_ "Remark" SG_ 760 PADS_ACU_PhoneBtnStVD "";
BA_ "GenSigSendType" SG_ 760 PADS_ACU_PhoneBtnStVD 1;
BA_ "Remark" SG_ 760 PADS_ACU_PhoneBtnSt "";
BA_ "GenSigSendType" SG_ 760 PADS_ACU_PhoneBtnSt 1;
BA_ "Remark" SG_ 760 PADS_ACU_VrBtnStVD "";
BA_ "GenSigSendType" SG_ 760 PADS_ACU_VrBtnStVD 1;
BA_ "Remark" SG_ 760 PADS_ACU_VrBtnSt "";
BA_ "GenSigSendType" SG_ 760 PADS_ACU_VrBtnSt 1;
BA_ "Remark" SG_ 760 PADS_ICM_ViewBtnStVD "";
BA_ "GenSigSendType" SG_ 760 PADS_ICM_ViewBtnStVD 1;
BA_ "Remark" SG_ 760 PADS_ICM_ViewBtnSt "";
BA_ "GenSigSendType" SG_ 760 PADS_ICM_ViewBtnSt 1;
BA_ "Remark" SG_ 760 PADS_ACU_SkipslideBtnStVD "";
BA_ "GenSigSendType" SG_ 760 PADS_ACU_SkipslideBtnStVD 1;
BA_ "Remark" SG_ 760 PADS_ACU_SkipslideBtnSt "";
BA_ "GenSigSendType" SG_ 760 PADS_ACU_SkipslideBtnSt 1;
BA_ "Remark" SG_ 760 PADS_ACU_SkipDecBtnStVD "";
BA_ "GenSigSendType" SG_ 760 PADS_ACU_SkipDecBtnStVD 1;
BA_ "Remark" SG_ 760 PADS_ACU_SkipDecBtnSt "";
BA_ "GenSigSendType" SG_ 760 PADS_ACU_SkipDecBtnSt 1;
BA_ "Remark" SG_ 760 PADS_ACU_SkipIncBtnStVD "";
BA_ "GenSigSendType" SG_ 760 PADS_ACU_SkipIncBtnStVD 1;
BA_ "Remark" SG_ 760 PADS_ACU_SkipIncBtnSt "";
BA_ "GenSigSendType" SG_ 760 PADS_ACU_SkipIncBtnSt 1;
BA_ "Remark" SG_ 760 PADS_ACU_VolDecBtnStVD "";
BA_ "GenSigSendType" SG_ 760 PADS_ACU_VolDecBtnStVD 1;
BA_ "Remark" SG_ 760 PADS_ACU_VolDecBtnSt "";
BA_ "GenSigSendType" SG_ 760 PADS_ACU_VolDecBtnSt 1;
BA_ "Remark" SG_ 760 PADS_ACU_VolIncBtnStVD "";
BA_ "GenSigSendType" SG_ 760 PADS_ACU_VolIncBtnStVD 1;
BA_ "Remark" SG_ 760 PADS_ACU_VolIncBtnSt "";
BA_ "GenSigSendType" SG_ 760 PADS_ACU_VolIncBtnSt 1;
BA_ "Remark" SG_ 760 PADS_ACU_ModeBtnStVD "";
BA_ "GenSigSendType" SG_ 760 PADS_ACU_ModeBtnStVD 1;
BA_ "Remark" SG_ 760 PADS_ACU_ModeBtnSt "";
BA_ "GenSigSendType" SG_ 760 PADS_ACU_ModeBtnSt 1;
BA_ "Remark" SG_ 443 PAS_RAEBWorkSts "";
BA_ "GenSigSendType" SG_ 443 PAS_RAEBWorkSts 1;
BA_ "Remark" SG_ 443 PAS_APAModeInd "";
BA_ "GenSigSendType" SG_ 443 PAS_APAModeInd 1;
BA_ "Remark" SG_ 443 PAS_BackParkDisplayReq "Implement in PT1 phase";
BA_ "GenSigSendType" SG_ 443 PAS_BackParkDisplayReq 1;
BA_ "Remark" SG_ 725 PAS_APAParkslotSt "";
BA_ "GenSigSendType" SG_ 725 PAS_APAParkslotSt 1;
BA_ "Remark" SG_ 725 PAS_APADrvReq "";
BA_ "GenSigSendType" SG_ 725 PAS_APADrvReq 1;
BA_ "Remark" SG_ 725 PAS_APARecInd "";
BA_ "GenSigSendType" SG_ 725 PAS_APARecInd 1;
BA_ "Remark" SG_ 725 PAS_APAQuitInd "";
BA_ "GenSigSendType" SG_ 725 PAS_APAQuitInd 1;
BA_ "Remark" SG_ 725 PAS_VRSwitchFailSt "";
BA_ "GenSigSendType" SG_ 725 PAS_VRSwitchFailSt 1;
BA_ "Remark" SG_ 725 PAS_APASt "";
BA_ "GenSigSendType" SG_ 725 PAS_APASt 1;
BA_ "Remark" SG_ 984 FRR_FCTAWarnR "";
BA_ "GenSigSendType" SG_ 984 FRR_FCTAWarnR 1;
BA_ "Remark" SG_ 984 FRR_FCTAWarnL "";
BA_ "GenSigSendType" SG_ 984 FRR_FCTAWarnL 1;
BA_ "GenSigTimeoutValue" SG_ 984 FRR_ErrSt 3;
BA_ "Remark" SG_ 984 FRR_ErrSt "";
BA_ "GenSigSendType" SG_ 984 FRR_ErrSt 1;
BA_ "Remark" SG_ 984 FRR_FCTAAssistType "";
BA_ "GenSigSendType" SG_ 984 FRR_FCTAAssistType 1;
BA_ "GenSigTimeoutValue" SG_ 984 FRR_FCTASt 3;
BA_ "Remark" SG_ 984 FRR_FCTASt "";
BA_ "GenSigSendType" SG_ 984 FRR_FCTASt 1;
BA_ "Remark" SG_ 984 ADAS_HWA_ILCTextInfo "";
BA_ "GenSigSendType" SG_ 984 ADAS_HWA_ILCTextInfo 1;
BA_ "Remark" SG_ 984 ADAS_HWA_ILCAbortSoundWarn "";
BA_ "GenSigSendType" SG_ 984 ADAS_HWA_ILCAbortSoundWarn 1;
BA_ "Remark" SG_ 984 ADAS_HWA_TrunLampReq "";
BA_ "GenSigSendType" SG_ 984 ADAS_HWA_TrunLampReq 1;
BA_ "Remark" SG_ 984 ADAS_HWA_ILCRighttSt "";
BA_ "GenSigSendType" SG_ 984 ADAS_HWA_ILCRighttSt 1;
BA_ "Remark" SG_ 984 ADAS_HWA_ILCLeftSt "";
BA_ "GenSigSendType" SG_ 984 ADAS_HWA_ILCLeftSt 1;
BA_ "Remark" SG_ 984 ADAS_ILCRightZoneSearch "";
BA_ "GenSigSendType" SG_ 984 ADAS_ILCRightZoneSearch 1;
BA_ "Remark" SG_ 984 ADAS_ILCLeftZoneSearch "";
BA_ "GenSigSendType" SG_ 984 ADAS_ILCLeftZoneSearch 1;
BA_ "GenSigTimeoutValue" SG_ 984 ADAS_HWA_FailureSt 1;
BA_ "Remark" SG_ 984 ADAS_HWA_FailureSt "";
BA_ "GenSigSendType" SG_ 984 ADAS_HWA_FailureSt 1;
BA_ "Remark" SG_ 984 ADAS_HWA_EnableSt "";
BA_ "GenSigSendType" SG_ 984 ADAS_HWA_EnableSt 1;
BA_ "GenSigStartValue" SG_ 590 ADAS_VoicePromptType 2;
BA_ "GenSigSendType" SG_ 590 ADAS_HWA_ILCWaitreasonRight 1;
BA_ "GenSigSendType" SG_ 590 ADAS_TrkTargt5DispColor 1;
BA_ "Remark" SG_ 590 ADAS_LnMarkingInfoLatency "";
BA_ "GatewayedSignals" SG_ 590 ADAS_LnMarkingInfoLatency 1;
BA_ "GenSigSendType" SG_ 590 ADAS_LnMarkingInfoLatency 1;
BA_ "Remark" SG_ 590 ADAS_TrkTarget0InfoLatency "";
BA_ "GatewayedSignals" SG_ 590 ADAS_TrkTarget0InfoLatency 1;
BA_ "GenSigSendType" SG_ 590 ADAS_TrkTarget0InfoLatency 1;
BA_ "Remark" SG_ 590 ADAS_WarnTypeSt "";
BA_ "GatewayedSignals" SG_ 590 ADAS_WarnTypeSt 1;
BA_ "GenSigSendType" SG_ 590 ADAS_WarnTypeSt 1;
BA_ "GenSigSendType" SG_ 589 ADAS_TrkTargt4DispColor 1;
BA_ "Remark" SG_ 589 ADAS_TrkTargt5ObjClass "";
BA_ "GatewayedSignals" SG_ 589 ADAS_TrkTargt5ObjClass 1;
BA_ "GenSigSendType" SG_ 589 ADAS_TrkTargt5ObjClass 1;
BA_ "Remark" SG_ 589 ADAS_TrkTargt5St "";
BA_ "GatewayedSignals" SG_ 589 ADAS_TrkTargt5St 1;
BA_ "GenSigSendType" SG_ 589 ADAS_TrkTargt5St 1;
BA_ "Remark" SG_ 589 ADAS_TrkTargt5latPos "";
BA_ "GatewayedSignals" SG_ 589 ADAS_TrkTargt5latPos 1;
BA_ "GenSigSendType" SG_ 589 ADAS_TrkTargt5latPos 1;
BA_ "GenSigInvalidValue" SG_ 589 ADAS_TrkTargt5latPos 1023;
BA_ "GenSigStartValue" SG_ 589 ADAS_TrkTargt5latPos 512;
BA_ "Remark" SG_ 589 ADAS_TrkTargt5longPos "";
BA_ "GatewayedSignals" SG_ 589 ADAS_TrkTargt5longPos 1;
BA_ "GenSigSendType" SG_ 589 ADAS_TrkTargt5longPos 1;
BA_ "GenSigInvalidValue" SG_ 589 ADAS_TrkTargt5longPos 255;
BA_ "Remark" SG_ 588 ADAS_TrkTargt3DispColor "";
BA_ "GatewayedSignals" SG_ 588 ADAS_TrkTargt3DispColor 1;
BA_ "GenSigSendType" SG_ 588 ADAS_TrkTargt3DispColor 1;
BA_ "Remark" SG_ 588 ADAS_TrkTargt4ObjClass "";
BA_ "GatewayedSignals" SG_ 588 ADAS_TrkTargt4ObjClass 1;
BA_ "GenSigSendType" SG_ 588 ADAS_TrkTargt4ObjClass 1;
BA_ "Remark" SG_ 588 ADAS_TrkTargt4St "";
BA_ "GatewayedSignals" SG_ 588 ADAS_TrkTargt4St 1;
BA_ "GenSigSendType" SG_ 588 ADAS_TrkTargt4St 1;
BA_ "Remark" SG_ 588 ADAS_TrkTargt4latPos "";
BA_ "GatewayedSignals" SG_ 588 ADAS_TrkTargt4latPos 1;
BA_ "GenSigSendType" SG_ 588 ADAS_TrkTargt4latPos 1;
BA_ "GenSigInvalidValue" SG_ 588 ADAS_TrkTargt4latPos 1023;
BA_ "GenSigStartValue" SG_ 588 ADAS_TrkTargt4latPos 512;
BA_ "Remark" SG_ 588 ADAS_TrkTargt4longPos "";
BA_ "GatewayedSignals" SG_ 588 ADAS_TrkTargt4longPos 1;
BA_ "GenSigSendType" SG_ 588 ADAS_TrkTargt4longPos 1;
BA_ "GenSigInvalidValue" SG_ 588 ADAS_TrkTargt4longPos 255;
BA_ "Remark" SG_ 993 ADAS_TrkTargt2latPos "";
BA_ "GenSigSendType" SG_ 993 ADAS_TrkTargt2latPos 1;
BA_ "GenSigInvalidValue" SG_ 993 ADAS_TrkTargt2latPos 1023;
BA_ "GenSigStartValue" SG_ 993 ADAS_TrkTargt2latPos 512;
BA_ "Remark" SG_ 993 ADAS_HWAWDSt "";
BA_ "GenSigSendType" SG_ 993 ADAS_HWAWDSt 1;
BA_ "Remark" SG_ 993 ADAS_FVDSt "";
BA_ "GenSigSendType" SG_ 993 ADAS_FVDSt 1;
BA_ "Remark" SG_ 993 ADAS_TrkTargt2DispColor "";
BA_ "GenSigSendType" SG_ 993 ADAS_TrkTargt2DispColor 1;
BA_ "Remark" SG_ 993 ADAS_TrkTargt2longPos "";
BA_ "GenSigSendType" SG_ 993 ADAS_TrkTargt2longPos 1;
BA_ "GenSigInvalidValue" SG_ 993 ADAS_TrkTargt2longPos 255;
BA_ "Remark" SG_ 993 ADAS_TrkTargt2St "";
BA_ "GenSigSendType" SG_ 993 ADAS_TrkTargt2St 1;
BA_ "Remark" SG_ 993 ADAS_TrkTargt2ObjClass "";
BA_ "GenSigSendType" SG_ 993 ADAS_TrkTargt2ObjClass 1;
BA_ "GenSigTimeoutValue" SG_ 993 ADAS_LLnMarkingDisPropToLnWidth 127;
BA_ "Remark" SG_ 993 ADAS_LLnMarkingDisPropToLnWidth "";
BA_ "GenSigSendType" SG_ 993 ADAS_LLnMarkingDisPropToLnWidth 1;
BA_ "GenSigStartValue" SG_ 993 ADAS_LLnMarkingDisPropToLnWidth 50;
BA_ "GenSigTimeoutValue" SG_ 993 ADAS_LnMarkingCurvature 1023;
BA_ "Remark" SG_ 993 ADAS_LnMarkingCurvature "";
BA_ "GenSigSendType" SG_ 993 ADAS_LnMarkingCurvature 1;
BA_ "GenSigStartValue" SG_ 993 ADAS_LnMarkingCurvature 1023;
BA_ "Remark" SG_ 993 ADAS_AdjLLnMrkingDispSt "";
BA_ "GenSigSendType" SG_ 993 ADAS_AdjLLnMrkingDispSt 1;
BA_ "GenSigTimeoutValue" SG_ 993 ADAS_LnMarkingHeadAngToVeh 1023;
BA_ "Remark" SG_ 993 ADAS_LnMarkingHeadAngToVeh "";
BA_ "GenSigSendType" SG_ 993 ADAS_LnMarkingHeadAngToVeh 1;
BA_ "GenSigStartValue" SG_ 993 ADAS_LnMarkingHeadAngToVeh 1023;
BA_ "Remark" SG_ 992 ADAS_TrkTargt1latPos "";
BA_ "GenSigSendType" SG_ 992 ADAS_TrkTargt1latPos 1;
BA_ "GenSigInvalidValue" SG_ 992 ADAS_TrkTargt1latPos 1023;
BA_ "GenSigStartValue" SG_ 992 ADAS_TrkTargt1latPos 512;
BA_ "Remark" SG_ 992 ADAS_RLnMarkingType "";
BA_ "GenSigSendType" SG_ 992 ADAS_RLnMarkingType 1;
BA_ "Remark" SG_ 992 ADAS_TrkTargt1DispColor "";
BA_ "GenSigSendType" SG_ 992 ADAS_TrkTargt1DispColor 1;
BA_ "Remark" SG_ 992 ADAS_TrkTargt1longPos "";
BA_ "GenSigSendType" SG_ 992 ADAS_TrkTargt1longPos 1;
BA_ "GenSigInvalidValue" SG_ 992 ADAS_TrkTargt1longPos 255;
BA_ "Remark" SG_ 992 ADAS_RLnMrkingPolyCoeffA2 "";
BA_ "GenSigSendType" SG_ 992 ADAS_RLnMrkingPolyCoeffA2 1;
BA_ "GenSigInvalidValue" SG_ 992 ADAS_RLnMrkingPolyCoeffA2 2047;
BA_ "GenSigStartValue" SG_ 992 ADAS_RLnMrkingPolyCoeffA2 1023;
BA_ "Remark" SG_ 992 ADAS_TrkTargt1St "";
BA_ "GenSigSendType" SG_ 992 ADAS_TrkTargt1St 1;
BA_ "Remark" SG_ 992 ADAS_TrkTargt1ObjClass "";
BA_ "GenSigSendType" SG_ 992 ADAS_TrkTargt1ObjClass 1;
BA_ "Remark" SG_ 992 ADAS_RLnMrkingPolyCoeffA1 "";
BA_ "GenSigSendType" SG_ 992 ADAS_RLnMrkingPolyCoeffA1 1;
BA_ "GenSigInvalidValue" SG_ 992 ADAS_RLnMrkingPolyCoeffA1 2047;
BA_ "GenSigStartValue" SG_ 992 ADAS_RLnMrkingPolyCoeffA1 1023;
BA_ "Remark" SG_ 992 ADAS_RlnMrkingDispSt "";
BA_ "GenSigSendType" SG_ 992 ADAS_RlnMrkingDispSt 1;
BA_ "Remark" SG_ 992 ADAS_RLnMrkingPolyCoeffA0 "";
BA_ "GenSigSendType" SG_ 992 ADAS_RLnMrkingPolyCoeffA0 1;
BA_ "GenSigInvalidValue" SG_ 992 ADAS_RLnMrkingPolyCoeffA0 2047;
BA_ "GenSigStartValue" SG_ 992 ADAS_RLnMrkingPolyCoeffA0 1023;
BA_ "Remark" SG_ 991 ADAS_TrkTargt0latPos "";
BA_ "GenSigSendType" SG_ 991 ADAS_TrkTargt0latPos 1;
BA_ "GenSigInvalidValue" SG_ 991 ADAS_TrkTargt0latPos 1023;
BA_ "GenSigStartValue" SG_ 991 ADAS_TrkTargt0latPos 512;
BA_ "Remark" SG_ 991 ADAS_LLnMarkingType "";
BA_ "GenSigSendType" SG_ 991 ADAS_LLnMarkingType 1;
BA_ "Remark" SG_ 991 ADAS_TrkTargt0DispColor "";
BA_ "GenSigSendType" SG_ 991 ADAS_TrkTargt0DispColor 1;
BA_ "Remark" SG_ 991 ADAS_TrkTargt0longPos "";
BA_ "GenSigSendType" SG_ 991 ADAS_TrkTargt0longPos 1;
BA_ "GenSigInvalidValue" SG_ 991 ADAS_TrkTargt0longPos 255;
BA_ "Remark" SG_ 991 ADAS_LLnMrkingPolyCoeffA2 "";
BA_ "GenSigSendType" SG_ 991 ADAS_LLnMrkingPolyCoeffA2 1;
BA_ "GenSigInvalidValue" SG_ 991 ADAS_LLnMrkingPolyCoeffA2 2047;
BA_ "GenSigStartValue" SG_ 991 ADAS_LLnMrkingPolyCoeffA2 1023;
BA_ "Remark" SG_ 991 ADAS_TrkTargt0St "";
BA_ "GenSigSendType" SG_ 991 ADAS_TrkTargt0St 1;
BA_ "Remark" SG_ 991 ADAS_TrkTargt0ObjClass "";
BA_ "GenSigSendType" SG_ 991 ADAS_TrkTargt0ObjClass 1;
BA_ "Remark" SG_ 991 ADAS_LLnMrkingPolyCoeffA1 "";
BA_ "GenSigSendType" SG_ 991 ADAS_LLnMrkingPolyCoeffA1 1;
BA_ "GenSigInvalidValue" SG_ 991 ADAS_LLnMrkingPolyCoeffA1 2047;
BA_ "GenSigStartValue" SG_ 991 ADAS_LLnMrkingPolyCoeffA1 1023;
BA_ "Remark" SG_ 991 ADAS_LlnMrkingDispSt "";
BA_ "GenSigSendType" SG_ 991 ADAS_LlnMrkingDispSt 1;
BA_ "Remark" SG_ 991 ADAS_LLnMrkingPolyCoeffA0 "";
BA_ "GenSigSendType" SG_ 991 ADAS_LLnMrkingPolyCoeffA0 1;
BA_ "GenSigInvalidValue" SG_ 991 ADAS_LLnMrkingPolyCoeffA0 2047;
BA_ "GenSigStartValue" SG_ 991 ADAS_LLnMrkingPolyCoeffA0 1023;
BA_ "Remark" SG_ 931 IFC_TJA_ICA_St "";
BA_ "GenSigSendType" SG_ 931 IFC_TJA_ICA_St 1;
BA_ "Remark" SG_ 931 IFC_TSR_AcousticWarn "";
BA_ "GenSigSendType" SG_ 931 IFC_TSR_AcousticWarn 1;
BA_ "Remark" SG_ 931 IFC_TSR_VisualWarn "";
BA_ "GenSigSendType" SG_ 931 IFC_TSR_VisualWarn 1;
BA_ "Remark" SG_ 931 IFC_IHBC_Enable "";
BA_ "GenSigSendType" SG_ 931 IFC_IHBC_Enable 1;
BA_ "Remark" SG_ 931 IFC_TSR_Enable "";
BA_ "GenSigSendType" SG_ 931 IFC_TSR_Enable 1;
BA_ "Remark" SG_ 931 IFC_IHBC_HighBeamReq "";
BA_ "GenSigSendType" SG_ 931 IFC_IHBC_HighBeamReq 1;
BA_ "GenSigTimeoutValue" SG_ 931 IFC_IHBC_St 3;
BA_ "Remark" SG_ 931 IFC_IHBC_St "";
BA_ "GenSigSendType" SG_ 931 IFC_IHBC_St 1;
BA_ "Remark" SG_ 931 IFC_TSR_OperatingSt "";
BA_ "GenSigSendType" SG_ 931 IFC_TSR_OperatingSt 1;
BA_ "Remark" SG_ 931 IFC_TSR_SpdLimitUnit "";
BA_ "GenSigSendType" SG_ 931 IFC_TSR_SpdLimitUnit 1;
BA_ "Remark" SG_ 931 IFC_TSR_SpdLimit "";
BA_ "GenSigSendType" SG_ 931 IFC_TSR_SpdLimit 1;
BA_ "Remark" SG_ 931 IFC_HWAHF_HandsOnIcon "";
BA_ "GenSigSendType" SG_ 931 IFC_HWAHF_HandsOnIcon 1;
BA_ "Remark" SG_ 931 IFC_LKS_TakeoverReq "";
BA_ "GenSigSendType" SG_ 931 IFC_LKS_TakeoverReq 1;
BA_ "Remark" SG_ 931 IFC_RightTrackingSt "";
BA_ "GenSigSendType" SG_ 931 IFC_RightTrackingSt 1;
BA_ "Remark" SG_ 931 IFC_LeftTrackingSt "";
BA_ "GenSigSendType" SG_ 931 IFC_LeftTrackingSt 1;
BA_ "GenSigTimeoutValue" SG_ 931 IFC_LKS_St 3;
BA_ "Remark" SG_ 931 IFC_LKS_St "";
BA_ "GenSigSendType" SG_ 931 IFC_LKS_St 1;
BA_ "Remark" SG_ 931 IFC_LKS_LaneAssistType "";
BA_ "GenSigSendType" SG_ 931 IFC_LKS_LaneAssistType 1;
BA_ "Remark" SG_ 931 IFC_TSR_AudioWarnEnable "";
BA_ "GenSigSendType" SG_ 931 IFC_TSR_AudioWarnEnable 1;
BA_ "Remark" SG_ 931 IFC_CruiseMode "";
BA_ "GenSigSendType" SG_ 931 IFC_CruiseMode 1;
BA_ "Remark" SG_ 931 IFC_TSR_SpdLimType "";
BA_ "GenSigSendType" SG_ 931 IFC_TSR_SpdLimType 1;
BA_ "Remark" SG_ 931 IFC_TSR_ISDRestOfDis "";
BA_ "GenSigSendType" SG_ 931 IFC_TSR_ISDRestOfDis 1;
BA_ "Remark" SG_ 931 IFC_LateralCtrlQuitWarn "";
BA_ "GenSigSendType" SG_ 931 IFC_LateralCtrlQuitWarn 1;
BA_ "Remark" SG_ 931 IFC_CameraBlockageSt "";
BA_ "GenSigSendType" SG_ 931 IFC_CameraBlockageSt 1;
BA_ "Remark" SG_ 931 IFC_SysCalibrationSt "";
BA_ "GenSigSendType" SG_ 931 IFC_SysCalibrationSt 1;
BA_ "Remark" SG_ 931 IFC_TSR_SLCAheadDis "";
BA_ "GenSigSendType" SG_ 931 IFC_TSR_SLCAheadDis 1;
BA_ "Remark" SG_ 735 ADAS_IntlCrusMode "";
BA_ "GenSigSendType" SG_ 735 ADAS_IntlCrusMode 1;
BA_ "Remark" SG_ 735 MRR_ACCMinBrakingReq "";
BA_ "GenSigSendType" SG_ 735 MRR_ACCMinBrakingReq 1;
BA_ "Remark" SG_ 735 MRR_EBAActiveSt "";
BA_ "GenSigSendType" SG_ 735 MRR_EBAActiveSt 1;
BA_ "Remark" SG_ 735 MRR_ActTrqReq "";
BA_ "GenSigSendType" SG_ 735 MRR_ActTrqReq 1;
BA_ "Remark" SG_ 735 ADAS_AcceComfLowerValue "";
BA_ "GenSigSendType" SG_ 735 ADAS_AcceComfLowerValue 1;
BA_ "Remark" SG_ 735 MRR_ACCUnableActivated "";
BA_ "GenSigSendType" SG_ 735 MRR_ACCUnableActivated 1;
BA_ "Remark" SG_ 735 ADAS_LongCtrlTypReqLong "";
BA_ "GenSigSendType" SG_ 735 ADAS_LongCtrlTypReqLong 1;
BA_ "Remark" SG_ 735 ADAS_LongCtrlTypReqMode "";
BA_ "GenSigSendType" SG_ 735 ADAS_LongCtrlTypReqMode 1;
BA_ "Remark" SG_ 735 ADAS_LongCtrlModeForBrkSys "";
BA_ "GenSigSendType" SG_ 735 ADAS_LongCtrlModeForBrkSys 1;
BA_ "Remark" SG_ 735 ADAS_LongCtrlDriveOff "";
BA_ "GenSigSendType" SG_ 735 ADAS_LongCtrlDriveOff 1;
BA_ "Remark" SG_ 890 IFC_AEBTarRangeAccel "";
BA_ "GenSigSendType" SG_ 890 IFC_AEBTarRangeAccel 1;
BA_ "Remark" SG_ 890 IFC_AEBTarConfiLevel "";
BA_ "GenSigSendType" SG_ 890 IFC_AEBTarConfiLevel 1;
BA_ "Remark" SG_ 890 IFC_HostAEBFeatureDiag "";
BA_ "GenSigSendType" SG_ 890 IFC_HostAEBFeatureDiag 1;
BA_ "Remark" SG_ 890 IFC_AEBTarDetSensor "";
BA_ "GenSigSendType" SG_ 890 IFC_AEBTarDetSensor 1;
BA_ "Remark" SG_ 890 IFC_AEBTarLatSpd "";
BA_ "GenSigSendType" SG_ 890 IFC_AEBTarLatSpd 1;
BA_ "Remark" SG_ 890 IFC_AEBTarLongPos "";
BA_ "GenSigSendType" SG_ 890 IFC_AEBTarLongPos 1;
BA_ "Remark" SG_ 890 IFC_AEBTarMotionState "";
BA_ "GenSigSendType" SG_ 890 IFC_AEBTarMotionState 1;
BA_ "Remark" SG_ 890 IFC_AEBTarCalss "";
BA_ "GenSigSendType" SG_ 890 IFC_AEBTarCalss 1;
BA_ "Remark" SG_ 890 IFC_AEBTarRangeRate "";
BA_ "GenSigSendType" SG_ 890 IFC_AEBTarRangeRate 1;
BA_ "Remark" SG_ 890 IFC_AEBTarLatPos "";
BA_ "GenSigSendType" SG_ 890 IFC_AEBTarLatPos 1;
BA_ "Remark" SG_ 890 IFC_AEBCustSetting "";
BA_ "GenSigSendType" SG_ 890 IFC_AEBCustSetting 1;
BA_ "Remark" SG_ 890 IFC_AEBSteeringInhibit "";
BA_ "GenSigSendType" SG_ 890 IFC_AEBSteeringInhibit 1;
BA_ "Remark" SG_ 890 IFC_AEBAccelePedalOverRide "";
BA_ "GenSigSendType" SG_ 890 IFC_AEBAccelePedalOverRide 1;
BA_ "Remark" SG_ 890 IFC_AEBBrePedalPressure "";
BA_ "GenSigSendType" SG_ 890 IFC_AEBBrePedalPressure 1;
BA_ "Remark" SG_ 890 IFC_AEBBrkPedalOverRide "";
BA_ "GenSigSendType" SG_ 890 IFC_AEBBrkPedalOverRide 1;
BA_ "Remark" SG_ 102 IFC_TSR_VisualSpdLimitNotHit2 "";
BA_ "EventCommandSignal" SG_ 102 IFC_TSR_VisualSpdLimitNotHit2 1;
BA_ "Remark" SG_ 102 IFC_TSR_OvSpdlimType "";
BA_ "EventCommandSignal" SG_ 102 IFC_TSR_OvSpdlimType 1;
BA_ "Remark" SG_ 102 IFC_TSR_VisualSpdLimitNotHit1 "";
BA_ "EventCommandSignal" SG_ 102 IFC_TSR_VisualSpdLimitNotHit1 1;
BA_ "GenSigTimeoutValue" SG_ 102 IFC_TSR_HitTarLatDis 512;
BA_ "Remark" SG_ 102 IFC_TSR_HitTarLatDis "";
BA_ "EventCommandSignal" SG_ 102 IFC_TSR_HitTarLatDis 1;
BA_ "GenSigInvalidValue" SG_ 102 IFC_TSR_HitTarLatDis 1023;
BA_ "GenSigStartValue" SG_ 102 IFC_TSR_HitTarLatDis 512;
BA_ "Remark" SG_ 102 IFC_TSR_VisualSpdLimitHitTar "";
BA_ "EventCommandSignal" SG_ 102 IFC_TSR_VisualSpdLimitHitTar 1;
BA_ "Remark" SG_ 102 IFC_TSR_HitTarLatDis2OLM "";
BA_ "EventCommandSignal" SG_ 102 IFC_TSR_HitTarLatDis2OLM 1;
BA_ "GenSigInvalidValue" SG_ 102 IFC_TSR_HitTarLatDis2OLM 255;
BA_ "Remark" SG_ 102 IFC_TSR_HitTarVerDis "";
BA_ "EventCommandSignal" SG_ 102 IFC_TSR_HitTarVerDis 1;
BA_ "GenSigInvalidValue" SG_ 102 IFC_TSR_HitTarVerDis 255;
BA_ "Remark" SG_ 967 DMS_FaceIDVerifyResult "";
BA_ "GenSigSendType" SG_ 967 DMS_FaceIDVerifyResult 1;
BA_ "Remark" SG_ 967 DMS_FaceIDDeleteResult "";
BA_ "GenSigSendType" SG_ 967 DMS_FaceIDDeleteResult 1;
BA_ "Remark" SG_ 967 DMS_FaceIDRegisterResult "";
BA_ "GenSigSendType" SG_ 967 DMS_FaceIDRegisterResult 1;
BA_ "Remark" SG_ 967 DMS_Mode "";
BA_ "GenSigSendType" SG_ 967 DMS_Mode 1;
BA_ "GenSigStartValue" SG_ 967 DMS_Mode 2;
BA_ "Remark" SG_ 967 DMS_FuncSt "";
BA_ "GenSigSendType" SG_ 967 DMS_FuncSt 1;
BA_ "Remark" SG_ 967 DMS_FaceIDWelcomeMode "";
BA_ "GenSigSendType" SG_ 967 DMS_FaceIDWelcomeMode 1;
BA_ "Remark" SG_ 967 DMS_InterestsRegion "";
BA_ "GenSigSendType" SG_ 967 DMS_InterestsRegion 1;
BA_ "Remark" SG_ 967 DMS_FaceID "";
BA_ "GenSigSendType" SG_ 967 DMS_FaceID 1;
BA_ "Remark" SG_ 967 DMS_DistrWarnSt "";
BA_ "GenSigSendType" SG_ 967 DMS_DistrWarnSt 1;
BA_ "Remark" SG_ 967 DMS_FatigWarnSt "";
BA_ "GenSigSendType" SG_ 967 DMS_FatigWarnSt 1;
BA_ "Remark" SG_ 967 DMS_SysErrSt "";
BA_ "GenSigSendType" SG_ 967 DMS_SysErrSt 1;
BA_ "Remark" SG_ 967 DMS_FaceIDSt "";
BA_ "GenSigSendType" SG_ 967 DMS_FaceIDSt 1;
BA_ "Remark" SG_ 666 PAS_RASt "后续可能调整";
BA_ "GenSigSendType" SG_ 666 PAS_RASt 1;
BA_ "Remark" SG_ 666 PAS_RA_RemaingDist "后续可能调整";
BA_ "GenSigSendType" SG_ 666 PAS_RA_RemaingDist 1;
BA_ "Remark" SG_ 666 PAS_RAEnableSt "后续可能调整";
BA_ "GenSigSendType" SG_ 666 PAS_RAEnableSt 1;
BA_ "GenSigSendType" SG_ 730 APA_VoiceReminder_SwitchSts 1;
BA_ "Remark" SG_ 730 FAPA_APAActFuncInd "";
BA_ "GenSigSendType" SG_ 730 FAPA_APAActFuncInd 1;
BA_ "Remark" SG_ 355 PAS_Mode "";
BA_ "GenSigSendType" SG_ 355 PAS_Mode 1;
BA_ "Remark" SG_ 839 PAS_PCSDisplayReq "";
BA_ "GenSigSendType" SG_ 839 PAS_PCSDisplayReq 1;
BA_ "Remark" SG_ 839 PAS_BattVoltErrFlag "";
BA_ "GenSigSendType" SG_ 839 PAS_BattVoltErrFlag 1;
BA_ "Remark" SG_ 839 PAS_CtrlModulerrFlag "";
BA_ "GenSigSendType" SG_ 839 PAS_CtrlModulerrFlag 1;
BA_ "Remark" SG_ 839 PAS_FSRSnsErrFlag "";
BA_ "GenSigSendType" SG_ 839 PAS_FSRSnsErrFlag 1;
BA_ "Remark" SG_ 839 PAS_FSLSnsErrFlag "";
BA_ "GenSigSendType" SG_ 839 PAS_FSLSnsErrFlag 1;
BA_ "Remark" SG_ 839 PAS_FLMidSnsErrFlag "";
BA_ "GenSigSendType" SG_ 839 PAS_FLMidSnsErrFlag 1;
BA_ "Remark" SG_ 839 PAS_FRMidSnsErrFlag "";
BA_ "GenSigSendType" SG_ 839 PAS_FRMidSnsErrFlag 1;
BA_ "Remark" SG_ 839 PAS_FLSnsErrFlag "";
BA_ "GenSigSendType" SG_ 839 PAS_FLSnsErrFlag 1;
BA_ "Remark" SG_ 839 PAS_FRSnsErrFlag "";
BA_ "GenSigSendType" SG_ 839 PAS_FRSnsErrFlag 1;
BA_ "Remark" SG_ 839 PAS_RSRSnsErrFlag "";
BA_ "GenSigSendType" SG_ 839 PAS_RSRSnsErrFlag 1;
BA_ "Remark" SG_ 839 PAS_RSLSnsErrFlag "";
BA_ "GenSigSendType" SG_ 839 PAS_RSLSnsErrFlag 1;
BA_ "Remark" SG_ 839 PAS_RLSnsErrFlag "";
BA_ "GenSigSendType" SG_ 839 PAS_RLSnsErrFlag 1;
BA_ "Remark" SG_ 839 PAS_RRSnsErrFlag "";
BA_ "GenSigSendType" SG_ 839 PAS_RRSnsErrFlag 1;
BA_ "Remark" SG_ 839 PAS_RLMidSnsErrFlag "";
BA_ "GenSigSendType" SG_ 839 PAS_RLMidSnsErrFlag 1;
BA_ "Remark" SG_ 839 PAS_RRMidSnsErrFlag "";
BA_ "GenSigSendType" SG_ 839 PAS_RRMidSnsErrFlag 1;
BA_ "GenSigTimeoutValue" SG_ 839 PAS_FSLSideDistance 255;
BA_ "Remark" SG_ 839 PAS_FSLSideDistance "";
BA_ "GenSigSendType" SG_ 839 PAS_FSLSideDistance 1;
BA_ "GenSigStartValue" SG_ 839 PAS_FSLSideDistance 255;
BA_ "GenSigTimeoutValue" SG_ 839 PAS_FSRSideDistance 255;
BA_ "Remark" SG_ 839 PAS_FSRSideDistance "";
BA_ "GenSigSendType" SG_ 839 PAS_FSRSideDistance 1;
BA_ "GenSigStartValue" SG_ 839 PAS_FSRSideDistance 255;
BA_ "GenSigTimeoutValue" SG_ 839 PAS_FLMidDistance 255;
BA_ "Remark" SG_ 839 PAS_FLMidDistance "";
BA_ "GenSigSendType" SG_ 839 PAS_FLMidDistance 1;
BA_ "GenSigStartValue" SG_ 839 PAS_FLMidDistance 255;
BA_ "GenSigTimeoutValue" SG_ 839 PAS_FRMidDistance 255;
BA_ "Remark" SG_ 839 PAS_FRMidDistance "";
BA_ "GenSigSendType" SG_ 839 PAS_FRMidDistance 1;
BA_ "GenSigStartValue" SG_ 839 PAS_FRMidDistance 255;
BA_ "GenSigTimeoutValue" SG_ 839 PAS_FLDistance 255;
BA_ "Remark" SG_ 839 PAS_FLDistance "";
BA_ "GenSigSendType" SG_ 839 PAS_FLDistance 1;
BA_ "GenSigStartValue" SG_ 839 PAS_FLDistance 255;
BA_ "GenSigTimeoutValue" SG_ 839 PAS_FRDistance 255;
BA_ "Remark" SG_ 839 PAS_FRDistance "";
BA_ "GenSigSendType" SG_ 839 PAS_FRDistance 1;
BA_ "GenSigStartValue" SG_ 839 PAS_FRDistance 255;
BA_ "GenSigTimeoutValue" SG_ 835 PAS_RSRSideDistance 255;
BA_ "Remark" SG_ 835 PAS_RSRSideDistance "";
BA_ "GenSigSendType" SG_ 835 PAS_RSRSideDistance 1;
BA_ "GenSigStartValue" SG_ 835 PAS_RSRSideDistance 255;
BA_ "GenSigTimeoutValue" SG_ 835 PAS_RSLSideDistance 255;
BA_ "Remark" SG_ 835 PAS_RSLSideDistance "";
BA_ "GenSigSendType" SG_ 835 PAS_RSLSideDistance 1;
BA_ "GenSigStartValue" SG_ 835 PAS_RSLSideDistance 255;
BA_ "GenSigTimeoutValue" SG_ 835 PAS_RLDistance 255;
BA_ "Remark" SG_ 835 PAS_RLDistance "";
BA_ "GenSigSendType" SG_ 835 PAS_RLDistance 1;
BA_ "GenSigStartValue" SG_ 835 PAS_RLDistance 255;
BA_ "GenSigTimeoutValue" SG_ 835 PAS_RRDistance 255;
BA_ "Remark" SG_ 835 PAS_RRDistance "";
BA_ "GenSigSendType" SG_ 835 PAS_RRDistance 1;
BA_ "GenSigStartValue" SG_ 835 PAS_RRDistance 255;
BA_ "GenSigTimeoutValue" SG_ 835 PAS_RLMidDistance 255;
BA_ "Remark" SG_ 835 PAS_RLMidDistance "";
BA_ "GenSigSendType" SG_ 835 PAS_RLMidDistance 1;
BA_ "GenSigStartValue" SG_ 835 PAS_RLMidDistance 255;
BA_ "GenSigTimeoutValue" SG_ 835 PAS_RRMidDistance 255;
BA_ "Remark" SG_ 835 PAS_RRMidDistance "";
BA_ "GenSigSendType" SG_ 835 PAS_RRMidDistance 1;
BA_ "GenSigStartValue" SG_ 835 PAS_RRMidDistance 255;
BA_ "Remark" SG_ 835 PAS_SideZoneStatusR "";
BA_ "GenSigSendType" SG_ 835 PAS_SideZoneStatusR 1;
BA_ "Remark" SG_ 835 PAS_SideZoneStatusF "";
BA_ "GenSigSendType" SG_ 835 PAS_SideZoneStatusF 1;
BA_ "Remark" SG_ 835 PAS_ButtonPress "";
BA_ "GenSigSendType" SG_ 835 PAS_ButtonPress 1;
BA_ "Remark" SG_ 835 PAS_WarnTone "";
BA_ "GenSigSendType" SG_ 835 PAS_WarnTone 1;
BA_ "Remark" SG_ 835 PAS_SystemType "";
BA_ "GenSigSendType" SG_ 835 PAS_SystemType 1;
BA_ "Remark" SG_ 651 ACU_MusicRollingCnt "";
BA_ "GenSigSendType" SG_ 651 ACU_MusicRollingCnt 1;
BA_ "Remark" SG_ 651 ACU_MusicDB1 "";
BA_ "GenSigSendType" SG_ 651 ACU_MusicDB1 1;
BA_ "Remark" SG_ 651 ACU_MusicDB0 "";
BA_ "GenSigSendType" SG_ 651 ACU_MusicDB0 1;
BA_ "Remark" SG_ 651 ACU_MusicFrq1 "";
BA_ "GenSigSendType" SG_ 651 ACU_MusicFrq1 1;
BA_ "Remark" SG_ 651 ACU_MusicFrq0 "";
BA_ "GenSigSendType" SG_ 651 ACU_MusicFrq0 1;
BA_ "Remark" SG_ 651 ACU_MusicAmp1 "";
BA_ "GenSigSendType" SG_ 651 ACU_MusicAmp1 1;
BA_ "Remark" SG_ 651 ACU_MusicAmp0 "";
BA_ "GenSigSendType" SG_ 651 ACU_MusicAmp0 1;
BA_ "Remark" SG_ 117 ACU_TelModuleResetReq "";
BA_ "EventCommandSignal" SG_ 117 ACU_TelModuleResetReq 1;
BA_ "Remark" SG_ 117 ACU_AuthKey "";
BA_ "EventCommandSignal" SG_ 117 ACU_AuthKey 1;
BA_ "Remark" SG_ 117 ACU_AuthRand "";
BA_ "EventCommandSignal" SG_ 117 ACU_AuthRand 1;
BA_ "Remark" SG_ 602 ACU_24_B_Checksum "Only for AVNT";
BA_ "GenSigSendType" SG_ 602 ACU_24_B_Checksum 1;
BA_ "GenSigStartValue" SG_ 602 ACU_24_B_Checksum 255;
BA_ "Remark" SG_ 602 ACU_24_B_MsgCounter "Only for AVNT";
BA_ "GenSigSendType" SG_ 602 ACU_24_B_MsgCounter 1;
BA_ "Remark" SG_ 602 ACU_BCM_VR_DoorlockControlVD "";
BA_ "EventCommandSignal" SG_ 602 ACU_BCM_VR_DoorlockControlVD 1;
BA_ "GenSigSendType" SG_ 602 ACU_BCM_VR_DoorlockControlVD 1;
BA_ "Remark" SG_ 602 ACU_BCM_VR_DoorlockControl "";
BA_ "EventCommandSignal" SG_ 602 ACU_BCM_VR_DoorlockControl 1;
BA_ "Remark" SG_ 602 ACU_RM_VR_RoofControlVD "";
BA_ "GenSigSendType" SG_ 602 ACU_RM_VR_RoofControlVD 1;
BA_ "Remark" SG_ 602 ACU_RM_VR_RoofControl "";
BA_ "EventCommandSignal" SG_ 602 ACU_RM_VR_RoofControl 1;
BA_ "GenSigInactiveValue" SG_ 602 ACU_RM_VR_RoofControl 127;
BA_ "GenSigStartValue" SG_ 602 ACU_RM_VR_RoofControl 127;
BA_ "Remark" SG_ 602 ACU_DM_VR_RRDMControlVD "Only for AVNT";
BA_ "GenSigSendType" SG_ 602 ACU_DM_VR_RRDMControlVD 1;
BA_ "Remark" SG_ 602 ACU_DM_VR_RLDMControlVD "Only for AVNT";
BA_ "GenSigSendType" SG_ 602 ACU_DM_VR_RLDMControlVD 1;
BA_ "Remark" SG_ 602 ACU_DM_VR_FRDMControlVD "Only for AVNT";
BA_ "GenSigSendType" SG_ 602 ACU_DM_VR_FRDMControlVD 1;
BA_ "Remark" SG_ 602 ACU_DM_VR_FLDMControlVD "Only for AVNT";
BA_ "GenSigSendType" SG_ 602 ACU_DM_VR_FLDMControlVD 1;
BA_ "Remark" SG_ 602 ACU_DM_VR_RRDMControl "Only for AVNT";
BA_ "Remark" SG_ 602 ACU_DM_VR_RLDMControl "Only for AVNT";
BA_ "Remark" SG_ 602 ACU_DM_VR_FRDMControl "Only for AVNT";
BA_ "Remark" SG_ 602 ACU_DM_VR_FLDMControl "Only for AVNT";
BA_ "Remark" SG_ 64 ACU_NaviCharacter "";
BA_ "EventCommandSignal" SG_ 64 ACU_NaviCharacter 1;
BA_ "Remark" SG_ 902 ICM_FuelLevelVD "";
BA_ "GenSigSendType" SG_ 902 ICM_FuelLevelVD 1;
BA_ "GenSigStartValue" SG_ 902 ICM_FuelLevelVD 1;
BA_ "Remark" SG_ 902 ICM_FuelLevel "";
BA_ "GenSigSendType" SG_ 902 ICM_FuelLevel 1;
BA_ "GenSigInvalidValue" SG_ 902 ICM_FuelLevel 101;
BA_ "GenSigSendType" SG_ 902 ICM_FuelLevelValue 1;
BA_ "GenSigInvalidValue" SG_ 902 ICM_FuelLevelValue 251;
BA_ "Remark" SG_ 902 ICM_Gaspedallvl "";
BA_ "GenSigSendType" SG_ 902 ICM_Gaspedallvl 1;
BA_ "Remark" SG_ 902 ICM_FuelLevel2VoltageRaw "";
BA_ "GenSigSendType" SG_ 902 ICM_FuelLevel2VoltageRaw 1;
BA_ "Remark" SG_ 902 ICM_FuelLevel1VoltageRaw "";
BA_ "GenSigSendType" SG_ 902 ICM_FuelLevel1VoltageRaw 1;
BA_ "Remark" SG_ 902 ICM_FuelSensor2Outofrange "";
BA_ "GenSigSendType" SG_ 902 ICM_FuelSensor2Outofrange 1;
BA_ "Remark" SG_ 902 ICM_FuelSensor2ShortToGND "";
BA_ "GenSigSendType" SG_ 902 ICM_FuelSensor2ShortToGND 1;
BA_ "Remark" SG_ 902 ICM_FuelSensor2ShortToBatt "";
BA_ "GenSigSendType" SG_ 902 ICM_FuelSensor2ShortToBatt 1;
BA_ "Remark" SG_ 902 ICM_FuelLevelEmpty "";
BA_ "GenSigSendType" SG_ 902 ICM_FuelLevelEmpty 1;
BA_ "Remark" SG_ 902 ICM_FuelSensorOutofrange "";
BA_ "GenSigSendType" SG_ 902 ICM_FuelSensorOutofrange 1;
BA_ "Remark" SG_ 902 ICM_FuelSensor1ShortToGND "";
BA_ "GenSigSendType" SG_ 902 ICM_FuelSensor1ShortToGND 1;
BA_ "Remark" SG_ 902 ICM_FuelSensor1ShortToBatt "";
BA_ "GenSigSendType" SG_ 902 ICM_FuelSensor1ShortToBatt 1;
BA_ "Remark" SG_ 902 ICM_FuelLevelLowSt "";
BA_ "GenSigSendType" SG_ 902 ICM_FuelLevelLowSt 1;
BA_ "Remark" SG_ 798 ICM_RearSeatBeltWarnCfgSt "";
BA_ "GenSigSendType" SG_ 798 ICM_RearSeatBeltWarnCfgSt 1;
BA_ "Remark" SG_ 798 ICM_FuelAvgConsumeTemp "";
BA_ "GenSigSendType" SG_ 798 ICM_FuelAvgConsumeTemp 1;
BA_ "GenSigInvalidValue" SG_ 798 ICM_FuelAvgConsumeTemp 255;
BA_ "Remark" SG_ 798 ICM_TotalOdometer_accurate "";
BA_ "GenSigSendType" SG_ 798 ICM_TotalOdometer_accurate 1;
BA_ "Remark" SG_ 798 ICM_LanguageCfgSt "";
BA_ "GenSigSendType" SG_ 798 ICM_LanguageCfgSt 1;
BA_ "Remark" SG_ 798 ICM_TimeModeCfgSt "";
BA_ "GenSigSendType" SG_ 798 ICM_TimeModeCfgSt 1;
BA_ "Remark" SG_ 798 ICM_WarnSoundVolCfgSt "";
BA_ "GenSigSendType" SG_ 798 ICM_WarnSoundVolCfgSt 1;
BA_ "GenSigStartValue" SG_ 798 ICM_WarnSoundVolCfgSt 1;
BA_ "Remark" SG_ 798 ICM_SpdWarnCfgSt "";
BA_ "GenSigSendType" SG_ 798 ICM_SpdWarnCfgSt 1;
BA_ "Remark" SG_ 850 ICM_VehRunningTime "";
BA_ "GenSigSendType" SG_ 850 ICM_VehRunningTime 1;
BA_ "Remark" SG_ 850 ICM_FuelEcoDistanceUnitDisp "";
BA_ "GenSigSendType" SG_ 850 ICM_FuelEcoDistanceUnitDisp 1;
BA_ "Remark" SG_ 850 ICM_PrUnitDisp "";
BA_ "GenSigSendType" SG_ 850 ICM_PrUnitDisp 1;
BA_ "Remark" SG_ 850 ICM_TempUnitDisp "";
BA_ "GenSigSendType" SG_ 850 ICM_TempUnitDisp 1;
BA_ "Remark" SG_ 850 ICM_BattVoltVD "";
BA_ "GenSigSendType" SG_ 850 ICM_BattVoltVD 1;
BA_ "Remark" SG_ 850 ICM_BattVolt "";
BA_ "GenSigSendType" SG_ 850 ICM_BattVolt 1;
BA_ "GenSigInvalidValue" SG_ 850 ICM_BattVolt 255;
BA_ "GenSigStartValue" SG_ 850 ICM_BattVolt 128;
BA_ "Remark" SG_ 850 ICM_FuelInsConsumed "";
BA_ "GenSigSendType" SG_ 850 ICM_FuelInsConsumed 1;
BA_ "GenSigInvalidValue" SG_ 850 ICM_FuelInsConsumed 255;
BA_ "Remark" SG_ 850 ICM_VehInsSpd "";
BA_ "GatewayedSignals" SG_ 850 ICM_VehInsSpd 1;
BA_ "GenSigSendType" SG_ 850 ICM_VehInsSpd 1;
BA_ "GenSigInvalidValue" SG_ 850 ICM_VehInsSpd 255;
BA_ "GenSigInvalidValue" SG_ 851 ICM_FuelAllConsumed 16777215;
BA_ "GenSigSendType" SG_ 851 ICM_FuelAllConsumed 1;
BA_ "GenSigInvalidValue" SG_ 851 ICM_FuelAvgConsume_50km 255;
BA_ "GenSigSendType" SG_ 851 ICM_FuelAvgConsume_50km 1;
BA_ "GenSigInvalidValue" SG_ 851 ICM_FuelAvgConsumeBest 255;
BA_ "GenSigSendType" SG_ 851 ICM_FuelAvgConsumeBest 1;
BA_ "GenSigSendType" SG_ 851 ICM_SetPedalLevelUp 1;
BA_ "GenSigSendType" SG_ 851 ICM_SetPedalLevelDown 1;
BA_ "Remark" SG_ 851 ICM_AvaibleDriveDistance "";
BA_ "GenSigSendType" SG_ 851 ICM_AvaibleDriveDistance 1;
BA_ "GenSigInvalidValue" SG_ 851 ICM_AvaibleDriveDistance 2047;
BA_ "Remark" SG_ 851 ICM_QDashACCFail "Only for AVNT";
BA_ "GatewayedSignals" SG_ 851 ICM_QDashACCFail 1;
BA_ "GenSigSendType" SG_ 851 ICM_QDashACCFail 1;
BA_ "Remark" SG_ 851 ICM_DisFail "Only for AVNT";
BA_ "GatewayedSignals" SG_ 851 ICM_DisFail 1;
BA_ "GenSigSendType" SG_ 851 ICM_DisFail 1;
BA_ "Remark" SG_ 851 ICM_FuelAverageConsumed "";
BA_ "GenSigSendType" SG_ 851 ICM_FuelAverageConsumed 1;
BA_ "GenSigInvalidValue" SG_ 851 ICM_FuelAverageConsumed 255;
BA_ "GenSigSendType" SG_ 843 ICM_ElcConspAccumAvgClnCmd 1;
BA_ "Remark" SG_ 843 ICM_MaintenanceCycle "";
BA_ "GenSigSendType" SG_ 843 ICM_MaintenanceCycle 1;
BA_ "Remark" SG_ 843 ICM_CancelMaintenanceSt "";
BA_ "GenSigSendType" SG_ 843 ICM_CancelMaintenanceSt 1;
BA_ "Remark" SG_ 843 ICM_MaintenanceReset "";
BA_ "GenSigSendType" SG_ 843 ICM_MaintenanceReset 1;
BA_ "Remark" SG_ 843 ICM_BFLWarning "Only for AVNT";
BA_ "GenSigSendType" SG_ 843 ICM_BFLWarning 1;
BA_ "Remark" SG_ 843 ICM_DispButtonSt "Only for AVNT";
BA_ "GenSigSendType" SG_ 843 ICM_DispButtonSt 1;
BA_ "Remark" SG_ 843 ICM_BackLightLevel "";
BA_ "GenSigSendType" SG_ 843 ICM_BackLightLevel 1;
BA_ "Remark" SG_ 843 ICM_OilPrSt "Only for AVNT";
BA_ "GenSigSendType" SG_ 843 ICM_OilPrSt 1;
BA_ "Remark" SG_ 843 ICM_FuelLevel "";
BA_ "GenSigSendType" SG_ 843 ICM_FuelLevel 1;
BA_ "GenSigInvalidValue" SG_ 843 ICM_FuelLevel 101;
BA_ "Remark" SG_ 843 ICM_TotalOdometer "";
BA_ "GenSigSendType" SG_ 843 ICM_TotalOdometer 1;
BA_ "Remark" SG_ 843 ICM_TPMSDriverResetReq "A8E新增2";
BA_ "GenSigSendType" SG_ 843 ICM_TPMSDriverResetReq 1;
BA_ "Remark" SG_ 843 ICM_WFLWarning "Only for AVNT";
BA_ "GenSigSendType" SG_ 843 ICM_WFLWarning 1;
BA_ "Remark" SG_ 843 ICM_ChargingSt "Only for AVNT";
BA_ "GenSigSendType" SG_ 843 ICM_ChargingSt 1;
BA_ "Remark" SG_ 843 ICM_FuelLevelVD "";
BA_ "GenSigSendType" SG_ 843 ICM_FuelLevelVD 1;
BA_ "GenSigStartValue" SG_ 843 ICM_FuelLevelVD 1;
BA_ "Remark" SG_ 843 ICM_AirbagLampFaultSt "Only for AVNT";
BA_ "GenSigSendType" SG_ 843 ICM_AirbagLampFaultSt 1;
BA_ "GenSigStartValue" SG_ 843 ICM_AirbagLampFaultSt 1;
BA_ "Remark" SG_ 843 ICM_VehicleBrakeSt "";
BA_ "GatewayedSignals" SG_ 843 ICM_VehicleBrakeSt 1;
BA_ "GenSigSendType" SG_ 843 ICM_VehicleBrakeSt 1;
BA_ "GenSigStartValue" SG_ 843 ICM_VehicleBrakeSt 1;
BA_ "Remark" SG_ 662 ICM_SetIACCSt "";
BA_ "GenSigSendType" SG_ 662 ICM_SetIACCSt 1;
BA_ "Remark" SG_ 662 ICM_Type "";
BA_ "GenSigSendType" SG_ 662 ICM_Type 1;
BA_ "Remark" SG_ 662 ICM_SoundWarnSilenceReq "";
BA_ "GenSigSendType" SG_ 662 ICM_SoundWarnSilenceReq 1;
BA_ "Remark" SG_ 662 ICM_MFSButtonSt "";
BA_ "GenSigSendType" SG_ 662 ICM_MFSButtonSt 1;
BA_ "Remark" SG_ 662 ICM_DriveMode "";
BA_ "GenSigSendType" SG_ 662 ICM_DriveMode 1;
BA_ "Remark" SG_ 662 ICM_DispTheme "";
BA_ "GenSigSendType" SG_ 662 ICM_DispTheme 1;
BA_ "Remark" SG_ 662 ICM_DisplayID "";
BA_ "GenSigSendType" SG_ 662 ICM_DisplayID 1;
BA_ "Remark" SG_ 662 ICM_APAParkNoticeFeedbackVD "";
BA_ "GenSigSendType" SG_ 662 ICM_APAParkNoticeFeedbackVD 1;
BA_ "Remark" SG_ 662 ICM_APAParkNoticeFeedback "";
BA_ "GenSigSendType" SG_ 662 ICM_APAParkNoticeFeedback 1;
BA_ "Remark" SG_ 1963 ACU_Diag_Response "";
BA_ "GenSigSendType" SG_ 1963 ACU_Diag_Response 1;
BA_ "Remark" SG_ 156 ACU_ANC_SwitchStatus "";
BA_ "EventCommandSignal" SG_ 156 ACU_ANC_SwitchStatus 1;
BA_ "GenSigInactiveValue" SG_ 156 ACU_ANC_SwitchStatus 3;
BA_ "GenSigStartValue" SG_ 156 ACU_ANC_SwitchStatus 3;
BA_ "Remark" SG_ 156 ACU_Headrest_Mode "";
BA_ "EventCommandSignal" SG_ 156 ACU_Headrest_Mode 1;
BA_ "GenSigInactiveValue" SG_ 156 ACU_Headrest_Mode 3;
BA_ "GenSigStartValue" SG_ 156 ACU_Headrest_Mode 3;
BA_ "Remark" SG_ 156 ACU_SoundmodeSet "";
BA_ "EventCommandSignal" SG_ 156 ACU_SoundmodeSet 1;
BA_ "GenSigInactiveValue" SG_ 156 ACU_SoundmodeSet 3;
BA_ "GenSigStartValue" SG_ 156 ACU_SoundmodeSet 3;
BA_ "Remark" SG_ 156 ACU_A2BSet "";
BA_ "EventCommandSignal" SG_ 156 ACU_A2BSet 1;
BA_ "GenSigInactiveValue" SG_ 156 ACU_A2BSet 3;
BA_ "GenSigStartValue" SG_ 156 ACU_A2BSet 3;
BA_ "Remark" SG_ 156 ACU_ESESts "";
BA_ "EventCommandSignal" SG_ 156 ACU_ESESts 1;
BA_ "GenSigInactiveValue" SG_ 156 ACU_ESESts 10;
BA_ "GenSigStartValue" SG_ 156 ACU_ESESts 7;
BA_ "Remark" SG_ 156 ACU_ICCSts "";
BA_ "EventCommandSignal" SG_ 156 ACU_ICCSts 1;
BA_ "GenSigInactiveValue" SG_ 156 ACU_ICCSts 10;
BA_ "GenSigStartValue" SG_ 156 ACU_ICCSts 7;
BA_ "Remark" SG_ 156 ACU_YamahaSoundMode "";
BA_ "EventCommandSignal" SG_ 156 ACU_YamahaSoundMode 1;
BA_ "GenSigInactiveValue" SG_ 156 ACU_YamahaSoundMode 3;
BA_ "GenSigStartValue" SG_ 156 ACU_YamahaSoundMode 7;
BA_ "Remark" SG_ 156 ACU_AdigoVirtualLiveSetReq "";
BA_ "EventCommandSignal" SG_ 156 ACU_AdigoVirtualLiveSetReq 1;
BA_ "GenSigInactiveValue" SG_ 156 ACU_AdigoVirtualLiveSetReq 3;
BA_ "GenSigStartValue" SG_ 156 ACU_AdigoVirtualLiveSetReq 7;
BA_ "Remark" SG_ 156 ACU_StrSurSet "";
BA_ "EventCommandSignal" SG_ 156 ACU_StrSurSet 1;
BA_ "GenSigInactiveValue" SG_ 156 ACU_StrSurSet 2;
BA_ "GenSigStartValue" SG_ 156 ACU_StrSurSet 3;
BA_ "Remark" SG_ 156 ACU_HeadrestRightVolumeReq "";
BA_ "EventCommandSignal" SG_ 156 ACU_HeadrestRightVolumeReq 1;
BA_ "GenSigInactiveValue" SG_ 156 ACU_HeadrestRightVolumeReq 10;
BA_ "GenSigStartValue" SG_ 156 ACU_HeadrestRightVolumeReq 15;
BA_ "Remark" SG_ 156 ACU_HeadrestLeftVolumeReq "";
BA_ "EventCommandSignal" SG_ 156 ACU_HeadrestLeftVolumeReq 1;
BA_ "GenSigInactiveValue" SG_ 156 ACU_HeadrestLeftVolumeReq 10;
BA_ "GenSigStartValue" SG_ 156 ACU_HeadrestLeftVolumeReq 15;
BA_ "Remark" SG_ 156 ACU_HeadrestPrivateModeMuteReq "";
BA_ "EventCommandSignal" SG_ 156 ACU_HeadrestPrivateModeMuteReq 1;
BA_ "GenSigInactiveValue" SG_ 156 ACU_HeadrestPrivateModeMuteReq 2;
BA_ "GenSigStartValue" SG_ 156 ACU_HeadrestPrivateModeMuteReq 2;
BA_ "Remark" SG_ 156 ACU_VRSourceSet "";
BA_ "EventCommandSignal" SG_ 156 ACU_VRSourceSet 1;
BA_ "GenSigInactiveValue" SG_ 156 ACU_VRSourceSet 7;
BA_ "GenSigStartValue" SG_ 156 ACU_VRSourceSet 7;
BA_ "GenSigInactiveValue" SG_ 156 ACU_TelSourceSet 7;
BA_ "Remark" SG_ 156 ACU_TelSourceSet "";
BA_ "EventCommandSignal" SG_ 156 ACU_TelSourceSet 1;
BA_ "GenSigStartValue" SG_ 156 ACU_TelSourceSet 7;
BA_ "Remark" SG_ 156 ACU_WarningSourceSet "";
BA_ "EventCommandSignal" SG_ 156 ACU_WarningSourceSet 1;
BA_ "GenSigInactiveValue" SG_ 156 ACU_WarningSourceSet 15;
BA_ "GenSigStartValue" SG_ 156 ACU_WarningSourceSet 15;
BA_ "Remark" SG_ 156 ACU_MediaSourceSet "";
BA_ "EventCommandSignal" SG_ 156 ACU_MediaSourceSet 1;
BA_ "GenSigInactiveValue" SG_ 156 ACU_MediaSourceSet 15;
BA_ "GenSigStartValue" SG_ 156 ACU_MediaSourceSet 15;
BA_ "EventCommandSignal" SG_ 185 ACU_RingVolSet 1;
BA_ "GenSigStartValue" SG_ 185 ACU_RingVolSet 15;
BA_ "Remark" SG_ 185 ACU_SetEqMode "";
BA_ "EventCommandSignal" SG_ 185 ACU_SetEqMode 1;
BA_ "GenSigInactiveValue" SG_ 185 ACU_SetEqMode 3;
BA_ "GenSigStartValue" SG_ 185 ACU_SetEqMode 3;
BA_ "Remark" SG_ 185 ACU_GetIntVoltReq "";
BA_ "EventCommandSignal" SG_ 185 ACU_GetIntVoltReq 1;
BA_ "GenSigInactiveValue" SG_ 185 ACU_GetIntVoltReq 3;
BA_ "GenSigStartValue" SG_ 185 ACU_GetIntVoltReq 3;
BA_ "Remark" SG_ 185 ACU_GetTempReq "";
BA_ "EventCommandSignal" SG_ 185 ACU_GetTempReq 1;
BA_ "GenSigInactiveValue" SG_ 185 ACU_GetTempReq 3;
BA_ "GenSigStartValue" SG_ 185 ACU_GetTempReq 3;
BA_ "Remark" SG_ 185 ACU_MainVolSet "";
BA_ "EventCommandSignal" SG_ 185 ACU_MainVolSet 1;
BA_ "GenSigInactiveValue" SG_ 185 ACU_MainVolSet 63;
BA_ "GenSigStartValue" SG_ 185 ACU_MainVolSet 63;
BA_ "Remark" SG_ 185 ACU_NaviVolSet "";
BA_ "EventCommandSignal" SG_ 185 ACU_NaviVolSet 1;
BA_ "GenSigInactiveValue" SG_ 185 ACU_NaviVolSet 63;
BA_ "GenSigStartValue" SG_ 185 ACU_NaviVolSet 63;
BA_ "Remark" SG_ 185 ACU_VRVolSet "";
BA_ "EventCommandSignal" SG_ 185 ACU_VRVolSet 1;
BA_ "GenSigInactiveValue" SG_ 185 ACU_VRVolSet 63;
BA_ "GenSigStartValue" SG_ 185 ACU_VRVolSet 63;
BA_ "Remark" SG_ 185 ACU_TelVolSet "";
BA_ "EventCommandSignal" SG_ 185 ACU_TelVolSet 1;
BA_ "GenSigInactiveValue" SG_ 185 ACU_TelVolSet 63;
BA_ "GenSigStartValue" SG_ 185 ACU_TelVolSet 63;
BA_ "Remark" SG_ 186 ACU_SpeakMid "";
BA_ "EventCommandSignal" SG_ 186 ACU_SpeakMid 1;
BA_ "GenSigInactiveValue" SG_ 186 ACU_SpeakMid 3;
BA_ "GenSigStartValue" SG_ 186 ACU_SpeakMid 3;
BA_ "Remark" SG_ 186 ACU_SpeakRR "";
BA_ "EventCommandSignal" SG_ 186 ACU_SpeakRR 1;
BA_ "GenSigInactiveValue" SG_ 186 ACU_SpeakRR 3;
BA_ "GenSigStartValue" SG_ 186 ACU_SpeakRR 3;
BA_ "Remark" SG_ 186 ACU_SpeakRL "";
BA_ "EventCommandSignal" SG_ 186 ACU_SpeakRL 1;
BA_ "GenSigInactiveValue" SG_ 186 ACU_SpeakRL 3;
BA_ "GenSigStartValue" SG_ 186 ACU_SpeakRL 3;
BA_ "Remark" SG_ 186 ACU_SpeakFR "";
BA_ "EventCommandSignal" SG_ 186 ACU_SpeakFR 1;
BA_ "GenSigInactiveValue" SG_ 186 ACU_SpeakFR 3;
BA_ "GenSigStartValue" SG_ 186 ACU_SpeakFR 3;
BA_ "Remark" SG_ 186 ACU_SpeakFL "";
BA_ "EventCommandSignal" SG_ 186 ACU_SpeakFL 1;
BA_ "GenSigInactiveValue" SG_ 186 ACU_SpeakFL 3;
BA_ "GenSigStartValue" SG_ 186 ACU_SpeakFL 3;
BA_ "Remark" SG_ 186 ACU_ClariFiSet "";
BA_ "EventCommandSignal" SG_ 186 ACU_ClariFiSet 1;
BA_ "GenSigInactiveValue" SG_ 186 ACU_ClariFiSet 3;
BA_ "GenSigStartValue" SG_ 186 ACU_ClariFiSet 3;
BA_ "Remark" SG_ 186 ACU_PowerSet "";
BA_ "EventCommandSignal" SG_ 186 ACU_PowerSet 1;
BA_ "GenSigInactiveValue" SG_ 186 ACU_PowerSet 3;
BA_ "GenSigStartValue" SG_ 186 ACU_PowerSet 3;
BA_ "Remark" SG_ 186 ACU_HighFrqSet "";
BA_ "EventCommandSignal" SG_ 186 ACU_HighFrqSet 1;
BA_ "GenSigInactiveValue" SG_ 186 ACU_HighFrqSet 31;
BA_ "GenSigStartValue" SG_ 186 ACU_HighFrqSet 31;
BA_ "Remark" SG_ 186 ACU_TEL_ECallSet "";
BA_ "EventCommandSignal" SG_ 186 ACU_TEL_ECallSet 1;
BA_ "GenSigInactiveValue" SG_ 186 ACU_TEL_ECallSet 3;
BA_ "GenSigStartValue" SG_ 186 ACU_TEL_ECallSet 3;
BA_ "Remark" SG_ 186 ACU_MuteRearSet "";
BA_ "EventCommandSignal" SG_ 186 ACU_MuteRearSet 1;
BA_ "GenSigInactiveValue" SG_ 186 ACU_MuteRearSet 3;
BA_ "GenSigStartValue" SG_ 186 ACU_MuteRearSet 3;
BA_ "Remark" SG_ 186 ACU_MuteSet "";
BA_ "EventCommandSignal" SG_ 186 ACU_MuteSet 1;
BA_ "GenSigInactiveValue" SG_ 186 ACU_MuteSet 3;
BA_ "GenSigStartValue" SG_ 186 ACU_MuteSet 3;
BA_ "Remark" SG_ 186 ACU_DrvSideSet "";
BA_ "EventCommandSignal" SG_ 186 ACU_DrvSideSet 1;
BA_ "GenSigInactiveValue" SG_ 186 ACU_DrvSideSet 3;
BA_ "GenSigStartValue" SG_ 186 ACU_DrvSideSet 3;
BA_ "Remark" SG_ 186 ACU_MidFrqSet "";
BA_ "EventCommandSignal" SG_ 186 ACU_MidFrqSet 1;
BA_ "GenSigInactiveValue" SG_ 186 ACU_MidFrqSet 31;
BA_ "GenSigStartValue" SG_ 186 ACU_MidFrqSet 31;
BA_ "Remark" SG_ 186 ACU_LowFrqSet "";
BA_ "EventCommandSignal" SG_ 186 ACU_LowFrqSet 1;
BA_ "GenSigInactiveValue" SG_ 186 ACU_LowFrqSet 31;
BA_ "GenSigStartValue" SG_ 186 ACU_LowFrqSet 31;
BA_ "Remark" SG_ 186 ACU_VSCModeReq "";
BA_ "EventCommandSignal" SG_ 186 ACU_VSCModeReq 1;
BA_ "GenSigInactiveValue" SG_ 186 ACU_VSCModeReq 7;
BA_ "GenSigStartValue" SG_ 186 ACU_VSCModeReq 7;
BA_ "Remark" SG_ 186 ACU_NaviSourceSet "";
BA_ "EventCommandSignal" SG_ 186 ACU_NaviSourceSet 1;
BA_ "GenSigInactiveValue" SG_ 186 ACU_NaviSourceSet 7;
BA_ "GenSigStartValue" SG_ 186 ACU_NaviSourceSet 7;
BA_ "Remark" SG_ 186 ACU_FaderSet "";
BA_ "EventCommandSignal" SG_ 186 ACU_FaderSet 1;
BA_ "GenSigInactiveValue" SG_ 186 ACU_FaderSet 31;
BA_ "GenSigStartValue" SG_ 186 ACU_FaderSet 31;
BA_ "Remark" SG_ 186 ACU_BeepSourceSet "";
BA_ "EventCommandSignal" SG_ 186 ACU_BeepSourceSet 1;
BA_ "GenSigInactiveValue" SG_ 186 ACU_BeepSourceSet 7;
BA_ "GenSigStartValue" SG_ 186 ACU_BeepSourceSet 7;
BA_ "Remark" SG_ 186 ACU_BlcSet "";
BA_ "EventCommandSignal" SG_ 186 ACU_BlcSet 1;
BA_ "GenSigInactiveValue" SG_ 186 ACU_BlcSet 31;
BA_ "GenSigStartValue" SG_ 186 ACU_BlcSet 31;
BA_ "Remark" SG_ 1067 ACU_NMDataField "";
BA_ "GenSigSendType" SG_ 1067 ACU_NMDataField 1;
BA_ "Remark" SG_ 1067 ACU_NMWakeupOrigin "";
BA_ "GenSigSendType" SG_ 1067 ACU_NMWakeupOrigin 1;
BA_ "Remark" SG_ 1067 ACU_NMSleepAck "";
BA_ "GenSigSendType" SG_ 1067 ACU_NMSleepAck 1;
BA_ "Remark" SG_ 1067 ACU_NMSleepInd "";
BA_ "GenSigSendType" SG_ 1067 ACU_NMSleepInd 1;
BA_ "Remark" SG_ 1067 ACU_NMLimpHome "";
BA_ "GenSigSendType" SG_ 1067 ACU_NMLimpHome 1;
BA_ "Remark" SG_ 1067 ACU_NMRing "";
BA_ "GenSigSendType" SG_ 1067 ACU_NMRing 1;
BA_ "Remark" SG_ 1067 ACU_NMAlive "";
BA_ "GenSigSendType" SG_ 1067 ACU_NMAlive 1;
BA_ "Remark" SG_ 1067 ACU_NMDestAddress "";
BA_ "GenSigSendType" SG_ 1067 ACU_NMDestAddress 1;
BA_ "Remark" SG_ 72 ACU_PLGMFuncCfg "";
BA_ "EventCommandSignal" SG_ 72 ACU_PLGMFuncCfg 1;
BA_ "Remark" SG_ 72 ACU_PLGMTrunkReleaseReq "";
BA_ "EventCommandSignal" SG_ 72 ACU_PLGMTrunkReleaseReq 1;
BA_ "Remark" SG_ 72 ACU_PLGMMaxPstReq "";
BA_ "EventCommandSignal" SG_ 72 ACU_PLGMMaxPstReq 1;
BA_ "Remark" SG_ 72 ACU_PLGMSetPstClearReq "";
BA_ "EventCommandSignal" SG_ 72 ACU_PLGMSetPstClearReq 1;
BA_ "Remark" SG_ 72 ACU_PLGMCloseReqVD "";
BA_ "EventCommandSignal" SG_ 72 ACU_PLGMCloseReqVD 1;
BA_ "Remark" SG_ 72 ACU_PLGMCloseReq "";
BA_ "EventCommandSignal" SG_ 72 ACU_PLGMCloseReq 1;
BA_ "Remark" SG_ 72 ACU_PLGMOpenReqVD "";
BA_ "EventCommandSignal" SG_ 72 ACU_PLGMOpenReqVD 1;
BA_ "Remark" SG_ 72 ACU_PLGMOpenReq "";
BA_ "EventCommandSignal" SG_ 72 ACU_PLGMOpenReq 1;
BA_ "Remark" SG_ 72 ACU_PLGMCtrl "";
BA_ "EventCommandSignal" SG_ 72 ACU_PLGMCtrl 1;
VAL_ 796 BCM_RearWiperSerPstFuncCfgSt 1 "Active" 0 "Not active" ;
VAL_ 796 BCM_RLSAutoSRWinCloseCfgSt 1 "Active" 0 "Not active" ;
VAL_ 796 BCM_AutoSRWinCloseCfgSt 1 "Active" 0 "Not active" ;
VAL_ 796 BCM_HeadlightDelayCfgSt 1 "Active" 0 "Not active" ;
VAL_ 796 BCM_IGNOffTimeVD 1 "Valid" 0 "Not valid" ;
VAL_ 796 BCM_AutoDomeLightCfgSt 1 "Active" 0 "Not active" ;
VAL_ 796 BCM_AutoWiperCfgSt 1 "Auto" 0 "Intermittent" ;
VAL_ 796 BCM_IALFuncCfgSt 1 "Active" 0 "Not active" ;
VAL_ 796 BCM_OSRMAutoFoldCfgSt 1 "Active" 0 "Not active" ;
VAL_ 796 BCM_HornCfgSt 1 "Active" 0 "Not active" ;
VAL_ 796 BCM_DTRLFuncCfgSt 1 "Active" 0 "Not active" ;
VAL_ 796 BCM_RGearEnableRearWipeCfgSt 1 "Active" 0 "Not active" ;
VAL_ 796 BCM_FrontWiperSerPstFuncCfgSt 1 "Active" 0 "Not active" ;
VAL_ 796 BCM_AutoLightSnsCfgSt 7 "Not used" 6 "Not used" 5 "Not used" 4 "Not used" 3 "Low sensitivity" 2 "Medium sensitivity" 1 "High sensitivity" 0 "Not used" ;
VAL_ 796 BCM_FollowMeHomeCfgSt 3 "Not used" 2 "Low beam and rear fog lamp" 1 "Only low beam" 0 "Not active" ;
VAL_ 796 BCM_AutoUnlockCfgSt 3 "Not used" 2 "Not used" 1 "Active" 0 "Not active" ;
VAL_ 796 BCM_SpdAutoLockCfgSt 1 "Active" 0 "Not active" ;
VAL_ 796 BCM_RemoteUnlockCfgSt 1 "Only driver door" 0 "All doors" ;
VAL_ 796 BCM_FogLampTurnCfgSt 1 "Active" 0 "Not active" ;
VAL_ 796 BCM_RemoteCtrlFDMRMCfgSt 1 "Active" 0 "Not active" ;
VAL_ 605 BCM_CentralLockSWSt 1 "Pressed" 0 "Not pressed" ;
VAL_ 605 BCM_InteriorTrunkReleaseSwitch 1 "Active" 0 "Not active" ;
VAL_ 605 BCM_MainLampSwitchSt 3 "LowBeam sw" 2 "ParkingLamp sw" 1 "AUTO sw" 0 "OFF sw" ;
VAL_ 605 BCM_BeamSwitchSt 3 " Invalid" 2 "High beam" 1 " Low beam" 0 " Flash" ;
VAL_ 605 BCM_AutoHighBeamCtrlSt 1 "Active" 0 "Not active" ;
VAL_ 605 BCM_RightTurnLampFaultSt 1 "Fault" 0 "Not fault" ;
VAL_ 605 BCM_RightTurnLampSt 1 "Active" 0 "Not active" ;
VAL_ 605 BCM_LeftTurnLampFaultSt 1 "Fault" 0 "Not fault" ;
VAL_ 605 BCM_LeftTurnLampSt 1 "Active" 0 "Not active" ;
VAL_ 605 BCM_LowBeamFaultSt 1 "Fault" 0 " Not Fault" ;
VAL_ 605 BCM_PositionLightFaultSt 1 "Fault" 0 " Not Fault" ;
VAL_ 605 BCM_PositionLightswitchSt 1 " Active" 0 " Not active" ;
VAL_ 605 BCM_BrakeLightFaultSt 1 "Fault" 0 " Not Fault" ;
VAL_ 605 BCM_DRLRFaultSt 1 "Fault" 0 "Not fault" ;
VAL_ 605 BCM_DRLLFaultSt 1 "Fault" 0 "Not fault" ;
VAL_ 605 BCM_RearWasherSt 1 "On" 0 "Off" ;
VAL_ 605 BCM_ReverseSwitchSt 1 "Active" 0 "Not active" ;
VAL_ 605 BCM_RearWiperSt 1 "On" 0 "Off" ;
VAL_ 605 BCM_DTRLSt 1 "Active" 0 "Not active" ;
VAL_ 605 BCM_FrontWiperSt 3 "Continuous fast" 2 "Continuous slow" 1 "error" 0 "OFF" ;
VAL_ 792 BCM_RemoteControlSt 15 "Reserved" 14 "Reserved" 13 "Reserved" 12 "Reserved" 11 "Reserved" 10 "Reserved" 9 "Reserved" 8 "Voltage abnormal" 7 "Authentication failure" 6 "Authentication time out" 5 "Manual Operation detected" 4 "EMS alarm error" 3 "Vehicle alarm error" 2 "Vehicle speed error" 1 "Remote control mode" 0 "Default" ;
VAL_ 792 BCM_HornSt 1 "Active" 0 "Not active" ;
VAL_ 792 BCM_FOB_ID 15 "Reserved" 14 "Reserved" 13 "Reserved" 12 "Reserved" 11 "Reserved" 10 "Reserved" 9 "Reserved" 8 "Reserved" 7 "Reserved" 6 "Reserved" 5 "Reserved" 4 "Reserved" 3 "Key3 index" 2 "Key2 index" 1 "Key1 index" 0 "Not used" ;
VAL_ 792 BCM_DRLRFaultSt 1 "Fault" 0 "Not fault" ;
VAL_ 792 BCM_DRLLFaultSt 1 "Fault" 0 "Not fault" ;
VAL_ 792 BCM_FrontWasherSt 1 "On" 0 "Off" ;
VAL_ 792 BCM_SunRoofPstSt 15 "Not used" 14 "Not used" 13 "Not used" 12 "Not used" 11 "Not used" 10 "Not used" 9 "Expanded slide open" 8 "Comfort position" 7 "Fully opened" 6 "Position not trusted" 5 "Reversing" 4 "Closing" 3 "Opening" 2 "Tilt up" 1 "Slide open" 0 "Fully closed" ;
VAL_ 792 BCM_WinMoveSt 3 "Inalid" 2 "Window Openning" 1 "Window Closing" 0 "Stopped" ;
VAL_ 792 BCM_ETWS_St 1 "Warning" 0 "Not warning" ;
VAL_ 792 BCM_RoomlampSt 1 "On" 0 "Off" ;
VAL_ 792 BCM_PsngrDoorLockSt 1 "Lock" 0 "Unlock" ;
VAL_ 792 BCM_DriverDoorLockSt 1 "Lock" 0 "Unlock" ;
VAL_ 792 BCM_ATWS_St 7 "Not used" 6 "Not used" 5 "Not used" 4 "Alarm" 3 "Not used" 2 "Disarmed" 1 "Prearmed" 0 "Armed" ;
VAL_ 792 BCM_AlarmHistory 7 "No history recorded" 6 "IMMO Authentication Failed" 5 "Rear right door intruded" 4 "Rear left door intruded" 3 "Passenger door intruded" 2 "Driver door intruded" 1 "Trunk intruded" 0 "Hood/Bonnet intruded" ;
VAL_ 792 BCM_KeyInsertSt 1 "Key in" 0 "Key out" ;
VAL_ 792 BCM_KeyInReminderWarnReq 1 "Active" 0 "No active" ;
VAL_ 792 BCM_RmtCtrlFobBattLow 1 "True" 0 "False" ;
VAL_ 792 BCM_TransportModeSt 1 "Active" 0 "Not active" ;
VAL_ 792 BCM_SunRoofOpenWarning 1 "Warning" 0 "Not warning" ;
VAL_ 792 BCM_VehReverseSt 1 "Reverse" 0 "Not reverse" ;
VAL_ 792 BCM_BrakeLightSwitchSt 1 "Active" 0 "Not active" ;
VAL_ 792 BCM_ParkingLampSt 1 "Active" 0 "Not active" ;
VAL_ 792 BCM_RearFogLampSt 1 "Active" 0 "Not active" ;
VAL_ 792 BCM_FrontFogLampSt 1 "Active" 0 "Not active" ;
VAL_ 792 BCM_HighBeamSt 1 "Active" 0 "Not active" ;
VAL_ 792 BCM_LowBeamSt 1 "Active" 0 "Not active" ;
VAL_ 792 BCM_RightTurnLampFaultSt 1 "Fault" 0 "Not Fault" ;
VAL_ 792 BCM_RightTurnLampSt 1 "Active" 0 "Not active" ;
VAL_ 792 BCM_LeftTurnLampFaultSt 1 "Fault" 0 "Not Fault" ;
VAL_ 792 BCM_LeftTurnLampSt 1 "Active" 0 "Not active" ;
VAL_ 792 BCM_DTRLSt 1 "Active" 0 "Not active" ;
VAL_ 792 BCM_TrunkReleaseCmd 1 "Active" 0 "Not active" ;
VAL_ 792 BCM_TrunkAjarSt 1 "Open" 0 "Closed" ;
VAL_ 792 BCM_BonnetAjarSt 1 "Open" 0 "Closed" ;
VAL_ 792 BCM_RRDoorAjarSt 1 "Open" 0 "Closed" ;
VAL_ 792 BCM_RLDoorAjarSt 1 "Open" 0 "Closed" ;
VAL_ 792 BCM_PsngrDoorAjarSt 1 "Open" 0 "Closed" ;
VAL_ 792 BCM_DriverDoorAjarSt 1 "Open" 0 "Closed" ;
VAL_ 792 BCM_LampOnWarningReq 1 "Active" 0 "Not active" ;
VAL_ 792 BCM_PGearSt 1 "P gear" 0 "Not P gear" ;
VAL_ 792 BCM_KeySt 3 "CRANK" 2 "ON" 1 "ACC" 0 "OFF                                 " ;
VAL_ 1109 ETC_NMWakeupOrigin 255 "Reserved" 254 "Reserved" 253 "Reserved" 252 "Reserved" 251 "Reserved" 250 "Reserved" 249 "Reserved" 248 "Reserved" 247 "Reserved" 246 "Reserved" 245 "Reserved" 244 "Reserved" 243 "Reserved" 242 "Reserved" 241 "Reserved" 240 "Reserved" 239 "Reserved" 238 "Reserved" 237 "Reserved" 236 "Reserved" 235 "Reserved" 234 "Reserved" 233 "Reserved" 232 "Reserved" 231 "Reserved" 230 "Reserved" 229 "Reserved" 228 "Reserved" 227 "Reserved" 226 "Reserved" 225 "Reserved" 224 "Reserved" 223 "Reserved" 222 "Reserved" 221 "Reserved" 220 "Reserved" 219 "Reserved" 218 "Reserved" 217 "Reserved" 216 "Reserved" 215 "Reserved" 214 "Reserved" 213 "Reserved" 212 "Reserved" 211 "Reserved" 210 "Reserved" 209 "Reserved" 208 "Reserved" 207 "Reserved" 206 "Reserved" 205 "Reserved" 204 "Reserved" 203 "Reserved" 202 "Reserved" 201 "Reserved" 200 "Reserved" 199 "Reserved" 198 "Reserved" 197 "Reserved" 196 "Reserved" 195 "Reserved" 194 "Reserved" 193 "Reserved" 192 "Reserved" 191 "Reserved" 190 "Reserved" 189 "Reserved" 188 "Reserved" 187 "Reserved" 186 "Reserved" 185 "Reserved" 184 "Reserved" 183 "Reserved" 182 "Reserved" 181 "Reserved" 180 "Reserved" 179 "Reserved" 178 "Reserved" 177 "Reserved" 176 "Reserved" 175 "Reserved" 174 "Reserved" 173 "Reserved" 172 "Reserved" 171 "Reserved" 170 "Reserved" 169 "Reserved" 168 "Reserved" 167 "Reserved" 166 "Reserved" 165 "Reserved" 164 "Reserved" 163 "Reserved" 162 "Reserved" 161 "Reserved" 160 "Reserved" 159 "Reserved" 158 "Reserved" 157 "Reserved" 156 "Reserved" 155 "Reserved" 154 "Reserved" 153 "Reserved" 152 "Reserved" 151 "Reserved" 150 "Reserved" 149 "Reserved" 148 "Reserved" 147 "Reserved" 146 "Reserved" 145 "Reserved" 144 "Reserved" 143 "Reserved" 142 "Reserved" 141 "Reserved" 140 "Reserved" 139 "Reserved" 138 "Reserved" 137 "Reserved" 136 "Reserved" 135 "Reserved" 134 "Reserved" 133 "Reserved" 132 "Reserved" 131 "Reserved" 130 "Reserved" 129 "Reserved" 128 "Reserved" 127 "Reserved" 126 "Reserved" 125 "Reserved" 124 "Reserved" 123 "Reserved" 122 "Reserved" 121 "Reserved" 120 "Reserved" 119 "Reserved" 118 "Reserved" 117 "Reserved" 116 "Reserved" 115 "Reserved" 114 "Reserved" 113 "Reserved" 112 "Reserved" 111 "Reserved" 110 "Reserved" 109 "Reserved" 108 "Reserved" 107 "Reserved" 106 "Reserved" 105 "Reserved" 104 "Reserved" 103 "Reserved" 102 "Reserved" 101 "Reserved" 100 "Reserved" 99 "Reserved" 98 "Reserved" 97 "Reserved" 96 "Reserved" 95 "Reserved" 94 "Reserved" 93 "Reserved" 92 "Reserved" 91 "Reserved" 90 "Reserved" 89 "Reserved" 88 "Reserved" 87 "Reserved" 86 "Reserved" 85 "Reserved" 84 "Reserved" 83 "Reserved" 82 "Reserved" 81 "Reserved" 80 "Reserved" 79 "Reserved" 78 "Reserved" 77 "Reserved" 76 "Reserved" 75 "Reserved" 74 "Reserved" 73 "Reserved" 72 "Reserved" 71 "Reserved" 70 "Reserved" 69 "Reserved" 68 "Reserved" 67 "Reserved" 66 "Reserved" 65 "Reserved" 64 "Reserved" 63 "Reserved" 62 "Reserved" 61 "Reserved" 60 "Reserved" 59 "Reserved" 58 "Reserved" 57 "Reserved" 56 "Reserved" 55 "Reserved" 54 "Reserved" 53 "Reserved" 52 "Reserved" 51 "Reserved" 50 "Reserved" 49 "Reserved" 48 "Reserved" 47 "Reserved" 46 "Reserved" 45 "Reserved" 44 "Reserved" 43 "Reserved" 42 "Reserved" 41 "Reserved" 40 "Reserved" 39 "Reserved" 38 "Reserved" 37 "Reserved" 36 "Reserved" 35 "Reserved" 34 "Reserved" 33 "Reserved" 32 "Reserved" 31 "Reserved" 30 "Reserved" 29 "Reserved" 28 "Reserved" 27 "Reserved" 26 "Reserved" 25 "Reserved" 24 "Reserved" 23 "Reserved" 22 "Reserved" 21 "Reserved" 20 "Reserved" 19 "Reserved" 18 "Reserved" 17 "Reserved" 16 "Reserved" 15 "Reserved" 14 "Reserved" 13 "Reserved" 12 "Reserved" 11 "Reserved" 10 "Reserved" 9 "Reserved" 8 "Reserved" 7 "Reserved" 6 "Reserved" 5 "Reserved" 4 "Reserved" 3 "Reserved" 2 "Reserved" 1 "Message wake up" ;
VAL_ 1109 ETC_NMSleepAck 1 "Active" 0 "Not active" ;
VAL_ 1109 ETC_NMSleepInd 1 "Active" 0 "Not active" ;
VAL_ 1109 ETC_NMLimpHome 1 "Active" 0 "Not active" ;
VAL_ 1109 ETC_NMRing 1 "Active" 0 "Not active" ;
VAL_ 1109 ETC_NMAlive 1 "Active" 0 "Not active" ;
VAL_ 1538 ETC_BLEenableCfgst 1 " Enable" 0 " Disable" ;
VAL_ 1538 ETC_ICMDisplayCfgst 1 " Enable" 0 " Disable" ;
VAL_ 1538 ETC_SysCfgst 1 " Enable" 0 " Disable" ;
VAL_ 1538 ETC_SystemSt 1 "abnormal" 0 "nomal" ;
VAL_ 1538 ETC_TradeType 2 "other close toll" 1 "highway close toll" 0 "highway unclose toll" ;
VAL_ 1538 ETC_GateProperty 3 "reserved" 2 "exit" 1 "entrance" 0 "reserved" ;
VAL_ 1538 ETC_SelfcheckSt 3 "trade and BLE system failure" 2 "BLE system failure" 1 "trade system failure" 0 "normal" ;
VAL_ 1538 ETC_DismountSt 3 "reserved" 2 "active, but invalid" 1 "not active" 0 "normal" ;
VAL_ 1096 WCM_NMWakeupOrigin 255 "Reserved" 254 "Reserved" 253 "Reserved" 252 "Reserved" 251 "Reserved" 250 "Reserved" 249 "Reserved" 248 "Reserved" 247 "Reserved" 246 "Reserved" 245 "Reserved" 244 "Reserved" 243 "Reserved" 242 "Reserved" 241 "Reserved" 240 "Reserved" 239 "Reserved" 238 "Reserved" 237 "Reserved" 236 "Reserved" 235 "Reserved" 234 "Reserved" 233 "Reserved" 232 "Reserved" 231 "Reserved" 230 "Reserved" 229 "Reserved" 228 "Reserved" 227 "Reserved" 226 "Reserved" 225 "Reserved" 224 "Reserved" 223 "Reserved" 222 "Reserved" 221 "Reserved" 220 "Reserved" 219 "Reserved" 218 "Reserved" 217 "Reserved" 216 "Reserved" 215 "Reserved" 214 "Reserved" 213 "Reserved" 212 "Reserved" 211 "Reserved" 210 "Reserved" 209 "Reserved" 208 "Reserved" 207 "Reserved" 206 "Reserved" 205 "Reserved" 204 "Reserved" 203 "Reserved" 202 "Reserved" 201 "Reserved" 200 "Reserved" 199 "Reserved" 198 "Reserved" 197 "Reserved" 196 "Reserved" 195 "Reserved" 194 "Reserved" 193 "Reserved" 192 "Reserved" 191 "Reserved" 190 "Reserved" 189 "Reserved" 188 "Reserved" 187 "Reserved" 186 "Reserved" 185 "Reserved" 184 "Reserved" 183 "Reserved" 182 "Reserved" 181 "Reserved" 180 "Reserved" 179 "Reserved" 178 "Reserved" 177 "Reserved" 176 "Reserved" 175 "Reserved" 174 "Reserved" 173 "Reserved" 172 "Reserved" 171 "Reserved" 170 "Reserved" 169 "Reserved" 168 "Reserved" 167 "Reserved" 166 "Reserved" 165 "Reserved" 164 "Reserved" 163 "Reserved" 162 "Reserved" 161 "Reserved" 160 "Reserved" 159 "Reserved" 158 "Reserved" 157 "Reserved" 156 "Reserved" 155 "Reserved" 154 "Reserved" 153 "Reserved" 152 "Reserved" 151 "Reserved" 150 "Reserved" 149 "Reserved" 148 "Reserved" 147 "Reserved" 146 "Reserved" 145 "Reserved" 144 "Reserved" 143 "Reserved" 142 "Reserved" 141 "Reserved" 140 "Reserved" 139 "Reserved" 138 "Reserved" 137 "Reserved" 136 "Reserved" 135 "Reserved" 134 "Reserved" 133 "Reserved" 132 "Reserved" 131 "Reserved" 130 "Reserved" 129 "Reserved" 128 "Reserved" 127 "Reserved" 126 "Reserved" 125 "Reserved" 124 "Reserved" 123 "Reserved" 122 "Reserved" 121 "Reserved" 120 "Reserved" 119 "Reserved" 118 "Reserved" 117 "Reserved" 116 "Reserved" 115 "Reserved" 114 "Reserved" 113 "Reserved" 112 "Reserved" 111 "Reserved" 110 "Reserved" 109 "Reserved" 108 "Reserved" 107 "Reserved" 106 "Reserved" 105 "Reserved" 104 "Reserved" 103 "Reserved" 102 "Reserved" 101 "Reserved" 100 "Reserved" 99 "Reserved" 98 "Reserved" 97 "Reserved" 96 "Reserved" 95 "Reserved" 94 "Reserved" 93 "Reserved" 92 "Reserved" 91 "Reserved" 90 "Reserved" 89 "Reserved" 88 "Reserved" 87 "Reserved" 86 "Reserved" 85 "Reserved" 84 "Reserved" 83 "Reserved" 82 "Reserved" 81 "Reserved" 80 "Reserved" 79 "Reserved" 78 "Reserved" 77 "Reserved" 76 "Reserved" 75 "Reserved" 74 "Reserved" 73 "Reserved" 72 "Reserved" 71 "Reserved" 70 "Reserved" 69 "Reserved" 68 "Reserved" 67 "Reserved" 66 "Reserved" 65 "Reserved" 64 "Reserved" 63 "Reserved" 62 "Reserved" 61 "Reserved" 60 "Reserved" 59 "Reserved" 58 "Reserved" 57 "Reserved" 56 "Reserved" 55 "Reserved" 54 "Reserved" 53 "Reserved" 52 "Reserved" 51 "Reserved" 50 "Reserved" 49 "Reserved" 48 "Reserved" 47 "Reserved" 46 "Reserved" 45 "Reserved" 44 "Reserved" 43 "Reserved" 42 "Reserved" 41 "Reserved" 40 "Reserved" 39 "Reserved" 38 "Reserved" 37 "Reserved" 36 "Reserved" 35 "Reserved" 34 "Reserved" 33 "Reserved" 32 "Reserved" 31 "Reserved" 30 "Reserved" 29 "Reserved" 28 "Reserved" 27 "Reserved" 26 "Reserved" 25 "Reserved" 24 "Reserved" 23 "Reserved" 22 "Reserved" 21 "Reserved" 20 "Reserved" 19 "Reserved" 18 "Reserved" 17 "Reserved" 16 "Reserved" 15 "Reserved" 14 "Reserved" 13 "Reserved" 12 "Reserved" 11 "Reserved" 10 "Reserved" 9 "Reserved" 8 "Reserved" 7 "Reserved" 6 "Reserved" 5 "Reserved" 4 "Reserved" 3 "Reserved" 2 "Reserved" 1 "Message wake up" ;
VAL_ 1096 WCM_NMSleepAck 1 "Active" 0 "Not active" ;
VAL_ 1096 WCM_NMSleepInd 1 "Active" 0 "Not active" ;
VAL_ 1096 WCM_NMLimpHome 1 "Active" 0 "Not active" ;
VAL_ 1096 WCM_NMRing 1 "Active" 0 "Not active" ;
VAL_ 1096 WCM_NMAlive 1 "Active" 0 "Not active" ;
VAL_ 949 WCM_Reminder 1 "phone left in car" 0 "No warning" ;
VAL_ 949 WCM_ControlResult 3 " Reserved" 2 " WCM shutdown by Switch/CAN" 1 " WCM disabled by PEPS " 0 " WCM enabled" ;
VAL_ 994 ADAS_TrkTargt3St 1 " dectected" 0 "not dectected" ;
VAL_ 994 IFC_ELKWarnR 7 "not used" 6 "not used" 5 "not used" 4 "not used" 3 "NELK-re" 2 " ELK-lcs" 1 " ELK-oncoming" 0 " No warning" ;
VAL_ 994 IFC_ELKWarnL 7 "not used" 6 "not used" 5 "not used" 4 "not used" 3 "NELK-re" 2 " ELK-lcs" 1 " ELK-oncoming" 0 " No warning" ;
VAL_ 994 IFC_ELKSt 3 "ELK failure" 2 "ELK active" 1 "ELK passive" 0 "ELK Off" ;
VAL_ 994 ADAS_AdjRLnMrkingDispSt 3 " not used" 2 " not used" 1 " display" 0 " No display" ;
VAL_ 760 PADS_ICM_MenuBtnStVD 1 "Valid" 0 "Not valid" ;
VAL_ 760 PADS_ICM_MenuBtnSt 1 "Press;" 0 "Release;" ;
VAL_ 760 PADS_ACU_CusBtnStVD 1 "Press;" 0 "Release;" ;
VAL_ 760 PADS_ACU_CusBtnSt 1 "Press;" 0 "Release;" ;
VAL_ 760 PADS_ACU_WechatBtnStVD 1 "Valid" 0 "Not valid" ;
VAL_ 760 PADS_ACU_WechatBtnSt 1 "Press" 0 "Release" ;
VAL_ 760 PADS_ICM_SkipslideBtnSt 3 "Not used" 2 "Slide dowm" 1 "Slide up" 0 "Release" ;
VAL_ 760 PADS_ICM_OkBtnStVD 1 "Valid" 0 "Not valid" ;
VAL_ 760 PADS_ICM_OkBtnSt 1 "Press" 0 "Release" ;
VAL_ 760 PADS_ICM_DowmBtnStVD 1 "Valid" 0 "Not valid" ;
VAL_ 760 PADS_ICM_DowmBtnSt 1 "Press" 0 "Release" ;
VAL_ 760 PADS_ICM_UpBtnStVD 1 "Valid" 0 "Not valid" ;
VAL_ 760 PADS_ICM_UpBtnSt 1 "Press" 0 "Release" ;
VAL_ 760 PADS_ACU_PhoneBtnStVD 1 "Valid" 0 "Not valid" ;
VAL_ 760 PADS_ACU_PhoneBtnSt 1 "Press" 0 "Release" ;
VAL_ 760 PADS_ACU_VrBtnStVD 1 "Valid" 0 "Not valid" ;
VAL_ 760 PADS_ACU_VrBtnSt 1 "Press" 0 "Release" ;
VAL_ 760 PADS_ICM_ViewBtnStVD 1 "Valid" 0 "Not valid" ;
VAL_ 760 PADS_ICM_ViewBtnSt 1 "Press" 0 "Release" ;
VAL_ 760 PADS_ACU_SkipslideBtnStVD 1 "Valid" 0 "Not valid" ;
VAL_ 760 PADS_ACU_SkipslideBtnSt 3 "Not used" 2 "slide left" 1 "slide right" 0 "Release" ;
VAL_ 760 PADS_ACU_SkipDecBtnStVD 1 "Valid" 0 "Not valid" ;
VAL_ 760 PADS_ACU_SkipDecBtnSt 1 "Press" 0 "Release" ;
VAL_ 760 PADS_ACU_SkipIncBtnStVD 1 "Valid" 0 "Not valid" ;
VAL_ 760 PADS_ACU_SkipIncBtnSt 1 "Press" 0 "Release" ;
VAL_ 760 PADS_ACU_VolDecBtnStVD 1 "Valid" 0 "Not valid" ;
VAL_ 760 PADS_ACU_VolDecBtnSt 1 "Press" 0 "Release" ;
VAL_ 760 PADS_ACU_VolIncBtnStVD 1 "Valid" 0 "Not valid" ;
VAL_ 760 PADS_ACU_VolIncBtnSt 1 "Press" 0 "Release" ;
VAL_ 760 PADS_ACU_ModeBtnStVD 1 "Valid" 0 "Not valid" ;
VAL_ 760 PADS_ACU_ModeBtnSt 1 "Press" 0 "Release" ;
VAL_ 443 PAS_RAEBWorkSts 3 "Failed" 2 "Active" 1 "Enable" 0 "Off" ;
VAL_ 443 PAS_APAModeInd 3 "POC is active" 2 "cPSC is active" 1 "pPSC is active" 0 "No function is active" ;
VAL_ 443 PAS_BackParkDisplayReq 3 "Reserve" 2 "Space parking" 1 " Image parking " 0 "None" ;
VAL_ 725 PAS_APARecInd 7 " mirror fold" 6 "RCTB active" 5 "Rerserved(APA);Req_Recover_Mobile out ofRange(FAPA)" 4 "Recover_Found Obstacle In Trajectory" 3 "Recover_Door_Closed(Except DriverDoor);Req_Recover_Door_Closed(FAPA)" 2 "Rerserved" 1 "Recover_Press Dead manSwtich(APA);Req_Repress_ Parking Switch(FAPA)" 0 "No Request" ;
VAL_ 725 PAS_VRSwitchFailSt 1 "Fail" 0 "No Fail" ;
VAL_ 725 PAS_APASt 7 " Invalid(Reserved)" 6 " Terminated" 5 " Failure" 4 " Completed" 3 " Guidance active" 2 " Searching" 1 " Standby  " 0 " Off" ;
VAL_ 984 FRR_FCTAWarnR 3 "Not used" 2 " warning level 2" 1 " Warning level 1" 0 " No warning" ;
VAL_ 984 FRR_FCTAWarnL 3 "Not used" 2 " warning level 2" 1 " Warning level 1" 0 " No warning" ;
VAL_ 984 FRR_ErrSt 3 "System Error" 2 " Temporary Error" 1 "sensor blocked" 0 "on" ;
VAL_ 984 FRR_FCTAAssistType 3 "brake and Warning" 2 "Warning" 1 "brake" 0 "No Selected" ;
VAL_ 984 FRR_FCTASt 3 "failure" 2 " Active" 1 " Passive/On/Inactive" 0 "Off" ;
VAL_ 984 ADAS_HWA_ILCTextInfo 5 " retreat" 4 " cancel(by driver)" 3 " abort(by sys)" 2 " lane changing right" 1 " lane changing left" 0 " no display" ;
VAL_ 984 ADAS_HWA_ILCAbortSoundWarn 3 " not used" 2 " not used" 1 " warning" 0 " no warning" ;
VAL_ 984 ADAS_HWA_TrunLampReq 3 " not used" 2 " right request on" 1 " left request on" 0 " no request" ;
VAL_ 984 ADAS_HWA_ILCRighttSt 15 " not used" 14 " not used" 13 " not used" 12 " not used" 11 " not used" 10 " not used" 9 " not used" 8 " Failure" 7 " Retreat" 6 " Abort" 5 " Lane Changed" 4 " Lane Changing" 3 " Wait" 2 " Enabled" 1 " Inhibited" 0 " Off" ;
VAL_ 984 ADAS_HWA_ILCLeftSt 15 " not used" 14 " not used" 13 " not used" 12 " not used" 11 " not used" 10 " not used" 9 " not used" 8 " Failure" 7 " Retreat" 6 " Abort" 5 " Lane Changed" 4 " Lane Changing" 3 " Wait" 2 " Enabled" 1 " Inhibited" 0 " Off" ;
VAL_ 984 ADAS_ILCRightZoneSearch 3 " warning" 2 " acting" 1 " permit" 0 " not possible" ;
VAL_ 984 ADAS_ILCLeftZoneSearch 3 " warning" 2 " acting" 1 " permit" 0 " not possible" ;
VAL_ 984 ADAS_HWA_FailureSt 1 " Failure" 0 " No Failure" ;
VAL_ 984 ADAS_HWA_EnableSt 1 " Enable" 0 " Disable" ;
VAL_ 590 ADAS_WarnTypeSt 3 " Not used" 2 " Both" 1 " Seat Vibation" 0 " Sound" ;
VAL_ 589 ADAS_TrkTargt5St 1 " dectected" 0 "not dectected" ;
VAL_ 588 ADAS_TrkTargt3DispColor 3 " Red" 2 " Yellow" 1 " Blue" 0 " Grey" ;
VAL_ 588 ADAS_TrkTargt4St 1 " dectected" 0 "not dectected" ;
VAL_ 993 ADAS_HWAWDSt 1 "On" 0 "Off" ;
VAL_ 993 ADAS_FVDSt 1 "On" 0 "Off" ;
VAL_ 993 ADAS_TrkTargt2DispColor 3 " Red" 2 " Yellow" 1 " Blue" 0 " Grey" ;
VAL_ 993 ADAS_TrkTargt2St 1 " dectected" 0 "not dectected" ;
VAL_ 993 ADAS_AdjLLnMrkingDispSt 3 " not used" 2 " not used" 1 " display" 0 " No display" ;
VAL_ 992 ADAS_RLnMarkingType 15 " not used" 14 " not used" 13 " not used" 12 "invalid" 11 "DECEL" 9 "parking cars" 8 "cones, poles" 7 "curb" 6 "barrier" 5 "botts" 4 "DLM" 3 "road edge" 2 "undecided" 1 "solid" 0 "dashed" ;
VAL_ 992 ADAS_TrkTargt1DispColor 3 "warning imminent" 2 "warning urgent" 1 "active" 0 "standby" ;
VAL_ 992 ADAS_TrkTargt1St 1 " dectected" 0 "not dectected" ;
VAL_ 992 ADAS_TrkTargt1ObjClass 15 " Reserved" 14 " Reserved" 13 " Reserved" 12 " Reserved" 11 " Reserved" 10 " unidentified vehicle(TBD)" 9 " bicycle" 8 " General on-borad object(TBD)" 7 " animal(TBD)" 6 " tree(TBD)" 5 " Pole(TBD)" 4 " pedestrian" 3 " truck" 2 " motorcycle" 1 " Car" 0 " Underdetemined" ;
VAL_ 992 ADAS_RlnMrkingDispSt 3 " warning" 2 " intervening" 1 " tracking" 0 " No display" ;
VAL_ 991 ADAS_LLnMarkingType 15 " not used" 14 " not used" 13 " not used" 12 "invalid" 11 "DECEL" 9 "parking cars" 8 "cones, poles" 7 "curb" 6 "barrier" 5 "botts" 4 "DLM" 3 "road edge" 2 "undecided" 1 "solid" 0 "dashed" ;
VAL_ 991 ADAS_TrkTargt0DispColor 3 "warning imminent" 2 "warning urgent" 1 "active" 0 "standby" ;
VAL_ 991 ADAS_TrkTargt0St 1 " dectected" 0 "not dectected" ;
VAL_ 991 ADAS_LlnMrkingDispSt 3 " warning" 2 " intervening" 1 " tracking" 0 " No display" ;
VAL_ 931 IFC_TJA_ICA_St 7 "Not used" 6 "Not used" 5 "Not used" 4 "Failure" 3 "Active by target vehicle" 2 "Active by line" 1 "Passive" 0 "Off" ;
VAL_ 931 IFC_TSR_AcousticWarn 1 "warning" 0 "No warning" ;
VAL_ 931 IFC_TSR_VisualWarn 1 "warning" 0 "No warning" ;
VAL_ 931 IFC_IHBC_Enable 1 "Enable" 0 "Disable" ;
VAL_ 931 IFC_TSR_Enable 1 "Enable" 0 "Disable" ;
VAL_ 931 IFC_IHBC_HighBeamReq 1 "High beam request" 0 "Low beam request" ;
VAL_ 931 IFC_IHBC_St 7 "Not used" 6 "Not used" 5 "Not used" 4 "Camera blocked" 3 "HMA failure" 2 "HMA active" 1 "HMA standby" 0 "HMA off" ;
VAL_ 931 IFC_TSR_OperatingSt 7 "Not used" 6 "Not used" 5 "Not used" 4 "TSR failure" 3 "Navigation only mode" 2 "Vision only mode" 1 "Fusion mode" 0 "Off" ;
VAL_ 931 IFC_TSR_SpdLimitUnit 3 "Not used" 2 "Miles/h" 1 "km/h" 0 "Unknown" ;
VAL_ 931 IFC_HWAHF_HandsOnIcon 7 "reserved" 6 "reserved" 5 "reserved" 4 "reserved" 3 "request not met 2" 2 "request not met 1" 1 "request met" 0 "no request" ;
VAL_ 931 IFC_LKS_TakeoverReq 1 "Active" 0 "Not active" ;
VAL_ 931 IFC_RightTrackingSt 3 "Warning" 2 "Intervention" 1 "Line tracking" 0 "No display" ;
VAL_ 931 IFC_LeftTrackingSt 3 "Warning" 2 "Intervention" 1 "Line tracking" 0 "No display" ;
VAL_ 931 IFC_LKS_St 7 "Not used" 6 "Not used" 5 "Not used" 4 "Camera blocked" 3 "LKS failure" 2 "LKS active" 1 "LKS standby" 0 "LKS Off" ;
VAL_ 931 IFC_LKS_LaneAssistType 3 "Steering and Warning" 2 "Warning" 1 "Steering" 0 "Not selected" ;
VAL_ 931 IFC_TSR_AudioWarnEnable 1 "Enable" 0 "Disable" ;
VAL_ 931 IFC_CruiseMode 3 "Not used" 2 "TJA-ICA mode" 1 "ACC mode" 0 "Invalid" ;
VAL_ 931 IFC_TSR_SpdLimType 3 "Not used" 2 "Interval speed detection" 1 "Camera detection" 0 "not specific" ;
VAL_ 931 IFC_TSR_ISDRestOfDis 15 "not used" 14 "not used" 13 "not used" 12 "1" 11 "11/12" 10 "5/6" 9 "3/4" 8 "2/3" 7 "7/12" 6 "1/2" 5 "5/12" 4 "1/3" 3 "1/4" 2 "1/6" 1 "1/12" 0 "0/12" ;
VAL_ 931 IFC_LateralCtrlQuitWarn 1 "Warning" 0 "No warning" ;
VAL_ 931 IFC_CameraBlockageSt 1 "Blocked" 0 "Not blocked" ;
VAL_ 931 IFC_SysCalibrationSt 3 "Not used" 2 "Calibration Failed" 1 "Calibration In Process" 0 "Calibration Success" ;
VAL_ 931 IFC_TSR_SLCAheadDis 15 "not used" 14 "not used" 13 "not used" 12 "1" 11 "11/12" 10 "5/6" 9 "3/4" 8 "2/3" 7 "7/12" 6 "1/2" 5 "5/12" 4 "1/3" 3 "1/4" 2 "1/6" 1 "1/12" 0 "0/12" ;
VAL_ 735 ADAS_IntlCrusMode 7 "Failure mode" 6 "Reserved" 5 "Override" 4 "Brake-only mode" 3 "Active-control mode" 2 "Stand-by mode" 1 "Passive mode" 0 "Off" ;
VAL_ 735 MRR_ACCMinBrakingReq 1 "Request" 0 "No request" ;
VAL_ 735 MRR_ACCUnableActivated 31 "Not used" 30 "Not used" 29 "Not used" 28 "Not used" 27 "Not used" 26 "Not used" 25 "Not used" 24 "Not used" 23 "Not used" 22 "Not used" 21 "Not used" 20 "Not used" 19 "Not used" 18 "Not used" 17 "Brake pedal depressed" 16 "Driver seat belt unfastened" 15 "vehicle door open" 14 "No forward gear" 13 "TCS Active" 12 "Override over 15 Minutes" 11 "Target lost" 10 "Engine off" 9 "ATSDrvMode not normal" 8 "EPB active" 7 "ABS active" 6 "HDC active" 5 "VDC acctive" 4 "AEB Intervention" 3 "Under brakeforce" 2 "Vehicle slip" 1 "ESP off" 0 "ACC no suppression" ;
VAL_ 735 ADAS_LongCtrlTypReqLong 7 " Reserved7" 6 " Reserved6" 5 " Reserved5" 4 " Reserved" 3 " Longitudinal Emergency" 2 "  Reserved" 1 " Longitudinal Comfort" 0 " Longitudinal Off" ;
VAL_ 735 ADAS_LongCtrlTypReqMode 3 " Reserved" 2 "Dvg Req L3" 1 " Dvg Req L12" 0 " None" ;
VAL_ 735 ADAS_LongCtrlModeForBrkSys 7 "Failure mode" 6 "Standstill" 5 "Override" 4 "Brake only mode" 3 "Active control mode" 2 "Standby mode" 1 "passive mode" 0 "Off mode" ;
VAL_ 735 ADAS_LongCtrlDriveOff 1 "Request" 0 "No request" ;
VAL_ 890 IFC_AEBTarConfiLevel 7 "Reserve" 6 "Reserve" 5 "High_2" 4 "High_1" 3 "Mid_2" 2 "Mid_1" 1 "Low_2" 0 "Low_1" ;
VAL_ 890 IFC_HostAEBFeatureDiag 2 "internal sensor plausibility check " 1 "diagnostic allow CIB to enable" 0 "invalid" ;
VAL_ 890 IFC_AEBTarDetSensor 3 "Fusion" 2 "Vision only" 1 "Radar only" 0 "invalid" ;
VAL_ 890 IFC_AEBTarMotionState 2 "moving" 1 "stationary" 0 "invalid" ;
VAL_ 890 IFC_AEBTarCalss 7 "Reserve" 6 "Reserve" 5 "Unknown" 4 "Truck" 3 "Cyclist" 2 "Pedestrian" 1 "Car" 0 "undetermined" ;
VAL_ 890 IFC_AEBCustSetting 3 "brake only" 2 "warning and brake" 1 "warning only" 0 "off" ;
VAL_ 890 IFC_AEBSteeringInhibit 1 "True" 0 "False" ;
VAL_ 890 IFC_AEBAccelePedalOverRide 1 "True" 0 "False" ;
VAL_ 890 IFC_AEBBrePedalPressure 1 "True" 0 "False" ;
VAL_ 890 IFC_AEBBrkPedalOverRide 1 "True" 0 "False" ;
VAL_ 102 IFC_TSR_OvSpdlimType 15 "others" 14 "Not used" 13 "Not used" 12 "Not used" 11 "Not used" 10 "Not used" 9 "Not used" 8 "Not used" 7 "Not used" 6 "Not used" 5 "speed limit cancel" 4 "electronic speed limit" 3 "ramp" 2 "multiple speed limit" 1 "signal speed limit" 0 "not detected" ;
VAL_ 967 DMS_FaceIDVerifyResult 3 "Timeout" 2 "Fail" 1 "Success" 0 "Default" ;
VAL_ 967 DMS_FaceIDDeleteResult 3 "Timeout" 2 "Fail" 1 "Success" 0 "Default" ;
VAL_ 967 DMS_FaceIDRegisterResult 3 "Timeout" 2 "Fail" 1 "Success" 0 "Default" ;
VAL_ 967 DMS_Mode 3 "not used" 2 "fatigue and distraction" 1 "distraction" 0 "Fatigue " ;
VAL_ 967 DMS_FuncSt 3 "failure" 2 "active" 1 "passive" 0 "off" ;
VAL_ 967 DMS_FaceIDWelcomeMode 1 "On" 0 "Off" ;
VAL_ 967 DMS_InterestsRegion 31 "Reserve" 30 "Reserve" 29 "Reserve" 28 "Reserve" 27 "Reserve" 26 "Reserve" 25 "Reserve" 24 "Reserve" 23 "Reserve" 22 "Reserve" 21 "Reserve" 20 "Reserve" 19 "Reserve" 18 "Reserve" 17 "Reserve" 16 "Reserve" 15 "Reserve" 14 "Reserve" 13 "Reserve" 12 "Reserve" 11 "Other area" 10 "Passenger side door panel" 9 "Passenger side footwell" 8 "Driver side footwell" 7 "Driver side door panel" 6 "Infotaiment display" 5 "Instrument cluster" 4 "Passenger side window" 3 "Driver side window" 2 "Rear view mirror" 1 "Windshield" 0 "Unavailable-default value" ;
VAL_ 967 DMS_FaceID 15 "Other" 14 "Other" 13 "Other" 12 "Other" 11 "Other" 10 "Other" 9 "Other" 8 "AUID 8" 7 "AUID 7" 6 "AUID 6" 5 "AUID 5" 4 "AUID 4" 3 "AUID 3" 2 "AUID 2" 1 "AUID 1" 0 "Default" ;
VAL_ 967 DMS_DistrWarnSt 7 "reserved" 6 "reserved" 5 "reserved" 4 "Suspected distractive" 3 "Non-Distractive" 2 "Distractive" 1 "Unknown" 0 "Unavailable" ;
VAL_ 967 DMS_FatigWarnSt 7 "Reserved" 6 "Reserved" 5 "Microsleep --Single Eye closure > 2 seconds" 4 "Severe State--AVECLOS > 11%  of frames with eye closures" 3 "Cautionary State--AVECLOS 4 to 11% of frames with eye closures." 2 "Attentive--AVECLOS < 4% of frames with eye closures" 1 "Unknown--driver detected, but can't determine the fatigue level" 0 "Unavailable--driver not detected" ;
VAL_ 967 DMS_SysErrSt 7 "reserved" 6 "reserved" 5 "IR-proof sunglass detected" 4 "FF lose templates" 3 "DMS system error" 2 "DMC blocked " 1 "DMC blocked by steeringwheel" 0 "Unavailable--default value" ;
VAL_ 967 DMS_FaceIDSt 3 "Erorr" 2 "Recognizing" 1 "Registering" 0 "Defoult" ;
VAL_ 666 PAS_RASt 7 "Reserved" 6 "Terminated" 5 " Failure" 4 "Completed" 3 " Active" 2 "Confirm" 1 "Standby" 0 "Off" ;
VAL_ 666 PAS_RAEnableSt 3 "Failed" 2 "Active" 1 "Enable" 0 "Off" ;
VAL_ 730 APA_VoiceReminder_SwitchSts 1 "open" 0 "Close" ;
VAL_ 730 FAPA_APAActFuncInd 15 "Reserved" 14 "Reserved" 13 "Reserved" 12 "Reserved" 11 "Reserved" 10 "Remote Back out" 9 "Remote Front out" 8 "Remote parallel POC" 7 "Remote crossl POC" 6 "Remote parallel Parkin" 5 "Remote cross Parkin" 4 "Automatic parallel park out" 3 "Automatic crossl park out" 2 "Automatic Parallel Park in" 1 "Automatic cross park in" 0 "No Active" ;
VAL_ 355 PAS_Mode 12 " System Inhibited" 11 "Rear failure and Front inactive(Reserved)" 10 "Front failure and Rear inactive" 9 "SystemFailure" 8 "FrontRearActive" 7 "RearActiveAndFrontFailure" 6 "RearActive(Reserved)" 5 "FrontActiveAndRearFailure" 4 "FrontActive" 3 "StandbyAndRearFailure(Reserved)" 2 "StandbyAndFrontFailure(Reserved)" 1 "Standby" 0 "Off" ;
VAL_ 839 PAS_PCSDisplayReq 1 "request" 0 "no request" ;
VAL_ 839 PAS_BattVoltErrFlag 1 "Fault" 0 "Not fault" ;
VAL_ 839 PAS_CtrlModulerrFlag 1 "Fault" 0 "Not fault" ;
VAL_ 839 PAS_FSRSnsErrFlag 1 "Fault" 0 "Not fault" ;
VAL_ 839 PAS_FSLSnsErrFlag 1 "Fault" 0 "Not fault" ;
VAL_ 839 PAS_FLMidSnsErrFlag 1 "Fault" 0 "Not fault" ;
VAL_ 839 PAS_FRMidSnsErrFlag 1 "Fault" 0 "Not fault" ;
VAL_ 839 PAS_FLSnsErrFlag 1 "Fault" 0 "Not fault" ;
VAL_ 839 PAS_FRSnsErrFlag 1 "Fault" 0 "Not fault" ;
VAL_ 839 PAS_RSRSnsErrFlag 1 "Fault" 0 "Not fault" ;
VAL_ 839 PAS_RSLSnsErrFlag 1 "Fault" 0 "Not fault" ;
VAL_ 839 PAS_RLSnsErrFlag 1 "Fault" 0 "Not fault" ;
VAL_ 839 PAS_RRSnsErrFlag 1 "Fault" 0 "Not fault" ;
VAL_ 839 PAS_RLMidSnsErrFlag 1 "Fault" 0 "Not fault" ;
VAL_ 839 PAS_RRMidSnsErrFlag 1 "Fault" 0 "Not fault" ;
VAL_ 839 PAS_FSLSideDistance 255 "No Obstacle Detected" 254 "Invalid" 253 "Invalid" 252 "Invalid" 251 "Invalid" ;
VAL_ 839 PAS_FSRSideDistance 255 "No Obstacle Detected" 254 "Invalid" 253 "Invalid" 252 "Invalid" 251 "Invalid" ;
VAL_ 839 PAS_FLMidDistance 255 "No Obstacle Detected" 254 "Invalid" 253 "Invalid" 252 "Invalid" 251 "Invalid" ;
VAL_ 839 PAS_FRMidDistance 255 "No Obstacle Detected" 254 "Invalid" 253 "Invalid" 252 "Invalid" 251 "Invalid" ;
VAL_ 839 PAS_FLDistance 255 "No Obstacle Detected" 254 "Invalid" 253 "Invalid" 252 "Invalid" 251 "Invalid" ;
VAL_ 839 PAS_FRDistance 255 "No Obstacle Detected" 254 "Invalid" 253 "Invalid" 252 "Invalid" 251 "Invalid" ;
VAL_ 835 PAS_RSRSideDistance 255 "No Obstacle Detected" 254 "Invalid" 253 "Invalid" 252 "Invalid" 251 "Invalid" ;
VAL_ 835 PAS_RSLSideDistance 255 "No Obstacle Detected" 254 "Invalid" 253 "Invalid" 252 "Invalid" 251 "Invalid" ;
VAL_ 835 PAS_RLDistance 255 "No Obstacle Detected" 254 "Invalid" 253 "Invalid" 252 "Invalid" 251 "Invalid" ;
VAL_ 835 PAS_RRDistance 255 "No Obstacle Detected" 254 "Invalid" 253 "Invalid" 252 "Invalid" 251 "Invalid" ;
VAL_ 835 PAS_RLMidDistance 255 "No Obstacle Detected" 254 "Invalid" 253 "Invalid" 252 "Invalid" 251 "Invalid" ;
VAL_ 835 PAS_RRMidDistance 255 "No Obstacle Detected" 254 "Invalid" 253 "Invalid" 252 "Invalid" 251 "Invalid" ;
VAL_ 835 PAS_SideZoneStatusR 3 "Not used" 2 "Not used" 1 "Left and right" 0 "None" ;
VAL_ 835 PAS_SideZoneStatusF 3 "Not used" 2 "Not used" 1 "Left and right" 0 "None" ;
VAL_ 835 PAS_ButtonPress 1 "Press" 0 "Not press" ;
VAL_ 835 PAS_WarnTone 15 "Not used" 14 "Not used" 13 "Not used" 12 "Not used" 11 "Not used" 10 "Not used" 9 "Not used" 8 "Not used" 7 "Not used" 6 "Not used" 5 "Mute" 4 "Slow intermittent tone" 3 "Medium-speed intermittent tone" 2 "Fast intermittent tone" 1 "Continuous tone" 0 "Not active" ;
VAL_ 835 PAS_SystemType 3 "Not used" 2 "Not used" 1 "APA(Automatic Parking Assistant)" 0 "RPA(Reverse Parking Assistant)" ;
VAL_ 117 ACU_TelModuleResetReq 1 "Reset" 0 "No Request" ;
VAL_ 602 ACU_BCM_VR_DoorlockControlVD 1 "Valid" 0 "Not valid" ;
VAL_ 602 ACU_BCM_VR_DoorlockControl 3 "Not used" 2 "Unlock" 1 "Lock" 0 "No command" ;
VAL_ 602 ACU_RM_VR_RoofControlVD 1 "Valid" 0 "Not valid" ;
VAL_ 602 ACU_RM_VR_RoofControl 109 "stop" 108 "change close(20%) " 107 "change open(20%)" 106 "shade open" 105 "shade close" 104 "roof fully open" 103 "Roof comfort position" 102 "roof tilt up" 101 "roof fully close" ;
VAL_ 602 ACU_DM_VR_RRDMControlVD 1 "Valid" 0 "Not valid" ;
VAL_ 602 ACU_DM_VR_RLDMControlVD 1 "Valid" 0 "Not valid" ;
VAL_ 602 ACU_DM_VR_FRDMControlVD 1 "Valid" 0 "Not valid" ;
VAL_ 602 ACU_DM_VR_FLDMControlVD 1 "Valid" 0 "Not valid" ;
VAL_ 602 ACU_DM_VR_RRDMControl 15 "Not used" 14 "Change close" 13 "Change open" 12 "Wind 90% open" 11 "Wind 80% open" 10 "Wind 70% open" 9 "Wind 60% open" 8 "Wind 50% open" 7 "Wind 40% open" 6 "Wind 30% open" 5 "Wind 20% open" 4 "Wind 10% open" 3 "Wind fully close" 2 "Wind fully open" 1 "Stop" 0 "No command" ;
VAL_ 602 ACU_DM_VR_RLDMControl 15 "Not used" 14 "Change close" 13 "Change open" 12 "Wind 90% open" 11 "Wind 80% open" 10 "Wind 70% open" 9 "Wind 60% open" 8 "Wind 50% open" 7 "Wind 40% open" 6 "Wind 30% open" 5 "Wind 20% open" 4 "Wind 10% open" 3 "Wind fully close" 2 "Wind fully open" 1 "Stop" 0 "No command" ;
VAL_ 602 ACU_DM_VR_FRDMControl 15 "Not used" 14 "Change close" 13 "Change open" 12 "Wind 90% open" 11 "Wind 80% open" 10 "Wind 70% open" 9 "Wind 60% open" 8 "Wind 50% open" 7 "Wind 40% open" 6 "Wind 30% open" 5 "Wind 20% open" 4 "Wind 10% open" 3 "Wind fully close" 2 "Wind fully open" 1 "Stop" 0 "No command" ;
VAL_ 602 ACU_DM_VR_FLDMControl 15 "Not used" 14 "Change close" 13 "Change open" 12 "Wind 90% open" 11 "Wind 80% open" 10 "Wind 70% open" 9 "Wind 60% open" 8 "Wind 50% open" 7 "Wind 40% open" 6 "Wind 30% open" 5 "Wind 20% open" 4 "Wind 10% open" 3 "Wind fully close" 2 "Wind fully open" 1 "Stop" 0 "No command" ;
VAL_ 902 ICM_FuelLevelVD 1 "Valid" 0 "Invalid" ;
VAL_ 902 ICM_Gaspedallvl 7 "reserved" 6 "reserved" 5 " level 5" 4 " level 4" 3 " level 3" 2 " level 2" 1 " level 1" 0 "level 0" ;
VAL_ 902 ICM_FuelSensor2Outofrange 1 "Fault" 0 "Not fault" ;
VAL_ 902 ICM_FuelSensor2ShortToGND 1 "Fault" 0 "Not fault" ;
VAL_ 902 ICM_FuelSensor2ShortToBatt 1 "Fault" 0 "Not fault" ;
VAL_ 902 ICM_FuelLevelEmpty 1 "Fault" 0 "Not fault" ;
VAL_ 902 ICM_FuelSensorOutofrange 1 "Fault" 0 "Not fault" ;
VAL_ 902 ICM_FuelSensor1ShortToGND 1 "Fault" 0 "Not fault" ;
VAL_ 902 ICM_FuelSensor1ShortToBatt 1 "Fault" 0 "Not fault" ;
VAL_ 902 ICM_FuelLevelLowSt 1 "Fuel level low" 0 "Fuel level normal" ;
VAL_ 798 ICM_RearSeatBeltWarnCfgSt 1 "On" 0 "Off" ;
VAL_ 798 ICM_LanguageCfgSt 7 "Not used" 6 "Not used" 5 "Not used" 4 "Arabic" 3 "Russian" 2 "English" 1 "Chinese" 0 "Not used" ;
VAL_ 798 ICM_TimeModeCfgSt 1 "12h mode" 0 "24h mode" ;
VAL_ 798 ICM_WarnSoundVolCfgSt 3 "Not used" 2 "High" 1 "Middle" 0 "Low" ;
VAL_ 850 ICM_FuelEcoDistanceUnitDisp 3 "Reversed" 2 "mpg(US),m" 1 "mpg(GB),m" 0 "L/100km,km" ;
VAL_ 850 ICM_PrUnitDisp 3 "Reserved" 2 "Psi" 1 "Bar" 0 "kPa" ;
VAL_ 850 ICM_TempUnitDisp 1 "℉" 0 "℃" ;
VAL_ 850 ICM_BattVoltVD 1 "Valid" 0 "Not valid" ;
VAL_ 851 ICM_QDashACCFail 3 "Not used" 2 "Not used" 1 "Error" 0 "No error" ;
VAL_ 851 ICM_DisFail 1 "Error" 0 "No error" ;
VAL_ 843 ICM_ElcConspAccumAvgClnCmd 1 "Clean" 0 "Not Clean" ;
VAL_ 843 ICM_MaintenanceCycle 3 "Reserved" 2 "10000km" 1 "7500km" 0 "5000km" ;
VAL_ 843 ICM_CancelMaintenanceSt 1 "On" 0 "Off" ;
VAL_ 843 ICM_MaintenanceReset 1 "Yes" 0 "No" ;
VAL_ 843 ICM_BFLWarning 1 "Low level" 0 "High level" ;
VAL_ 843 ICM_DispButtonSt 1 "Pressed" 0 "Not pressed" ;
VAL_ 843 ICM_BackLightLevel 15 "Not used" 14 "Not used" 13 "Not used" 12 "Not used" 11 "Not used" 10 "Not used" 9 "Not used" 8 "Not used" 7 "Level 8" 6 "Level 7" 5 "Level 6" 4 "Leve l5" 3 "Level 4" 2 "Level 3" 1 "Level 2" 0 "Level 1" ;
VAL_ 843 ICM_OilPrSt 1 "Low level" 0 "High level" ;
VAL_ 843 ICM_TPMSDriverResetReq 1 "Request reset" 0 " No request" ;
VAL_ 843 ICM_WFLWarning 1 "Low level" 0 "High level" ;
VAL_ 843 ICM_ChargingSt 1 "Low level" 0 "High level" ;
VAL_ 843 ICM_FuelLevelVD 1 "Valid" 0 "Invalid" ;
VAL_ 843 ICM_AirbagLampFaultSt 1 "Fault" 0 "Not Fault" ;
VAL_ 843 ICM_VehicleBrakeSt 1 "Brake" 0 "Not brake" ;
VAL_ 662 ICM_SetIACCSt 1 "Active" 0 "Not active " ;
VAL_ 662 ICM_Type 15 "Reverse" 14 "Reverse" 13 "Reverse" 12 "Reverse" 11 "Reverse" 10 "Reverse" 9 "Reverse" 8 "Reverse" 7 "Reverse" 6 "Reverse" 5 "Reverse" 4 "Reverse" 3 "12.3inch cluster" 2 "10inch cluster" 1 "7inch cluster" 0 "Invalid" ;
VAL_ 662 ICM_SoundWarnSilenceReq 1 "Active" 0 "Not active " ;
VAL_ 662 ICM_MFSButtonSt 15 "Rserve" 14 "Rserve" 13 "Rserve" 12 "Rserve" 11 "Rserve" 10 "Rserve" 9 "Rserve" 8 "Rserve" 7 "Rserve" 6 "Rserve" 5 "OK" 4 "RIGHT" 3 "LEFT" 2 "DOWN" 1 "UP" 0 "No Command" ;
VAL_ 662 ICM_DriveMode 7 "Reserved" 6 "Reserved" 5 "Reserved" 4 "Reserved" 3 " Sport" 2 " ECO" 1 " Normal" 0 " No command" ;
VAL_ 662 ICM_DispTheme 7 "Rserve" 6 "Rserve" 5 "Rserve" 4 "Rserve" 3 "Rserve" 2 "Technology" 1 "Classic" 0 "Invalid" ;
VAL_ 662 ICM_APAParkNoticeFeedbackVD 1 "Valid" 0 "Not valid" ;
VAL_ 662 ICM_APAParkNoticeFeedback 63 "Not used" 62 "Not used" 61 "Not used" 60 "Not used" 59 "Not used" 58 "Not used" 57 "Not used" 56 "Not used" 55 "Not used" 54 "Not used" 53 "Not used" 52 "Not used" 51 "Not used" 50 "Searching_Slow_Down" 49 "APA external Failure" 48 "APA internal Failure" 47 "Failure_Sensors Blinded" 46 "Abort_ Userdeactivated" 45 "Abort_Trailor attached" 44 "Abort_max number of maneouvres reached" 43 "Abort_Hand on detect" 42 "Abort_Speed too high" 41 "Abort_ESP Intervention" 40 "Not used" 39 "Parking maneuver completed" 38 "Guidence_Slow_Down" 37 "Guidence_Wait_for_steeringcomplete" 36 "Guidance_Stop" 35 "Guidance_Insert_R_Gear" 34 "Guidance_Insert_D_Gear" 33 "POC_move_fwd_L" 32 "POC_move_fwd_R" 31 "cPSC_move_fwd_L" 30 "cPSC_move_fwd_R" 29 "pPSC_move_fwd_L" 28 "pPSC_move_fwd_R" 27 "POC_move_bwd_L" 26 "POC_move_bwd_R" 25 "cPSC_move_bwd_L" 24 "cPSC_move_bwd_R" 23 "pPSC_move_bwd_L" 22 "pPSC_move_bwd_R" 21 "POC_Turn_ON_Indicator" 20 "Not used" 19 "Not used" 18 "Not used" 17 "PSC_PS_OK_Reactive" 16 "cPSC_PS_OK_R_Gear_L" 15 "cPSC_PS_OK_R_Gear_R" 14 "pPSC_PS_OK_R_Gear_L" 13 "pPSC_PS_OK_R_Gear_R" 12 "cPSC_PS_OK_Stop_L" 11 "cPSC_PS_OK_Stop_R" 10 "pPSC_PS_OK_Stop_L" 9 "pPSC_PS_OK_Stop_R" 8 "cPSC_PS_OK_Pos_NOK_L" 7 "cPSC_PS_OK_Pos_NOK_R" 6 "pPSC_PS_OK_Pos_NOK_L" 5 "pPSC_PS_OK_Pos_NOK_R" 4 "cPSC_Search_L" 3 "cPSC_Search_R" 2 "pPSC_Search_L" 1 "pPSC_Search_R" 0 "Idel" ;
VAL_ 156 ACU_ANC_SwitchStatus 3 "No Command" 2 "Reserved" 1 "on" 0 "off" ;
VAL_ 156 ACU_Headrest_Mode 3 "No Command" 2 "only head" 1 "All Speak" 0 "off" ;
VAL_ 156 ACU_SoundmodeSet 3 "No Command" 2 "Reserved" 1 "adigo" 0 "YAMAHA" ;
VAL_ 156 ACU_A2BSet 3 "No Command" 2 "A2BReady" 1 "A2BNotReady" 0 "none" ;
VAL_ 156 ACU_ESESts 7 "No Command" 6 "Reserved" 5 "Reserved" 4 "Reserved" 3 "HI" 2 "MID" 1 "LOW" 0 "OFF" ;
VAL_ 156 ACU_ICCSts 7 "No Command" 6 "Reserved" 5 "Reserved" 4 "Reserved" 3 "HI" 2 "MID" 1 "LOW" 0 "OFF" ;
VAL_ 156 ACU_TelSourceSet 7 "No Command" 6 "Reserved" 5 "Reserved" 4 "Reserved" 3 "Phone Ring（BT Phone/Carlife Phone/Carlife Phone）" 2 "BT Phone/Carlife Phone/Carlife Phone/Hicar Phone" 1 "E-Call/B-Call" 0 "None" ;
VAL_ 156 ACU_MediaSourceSet 15 " No Command" 14 "Reserved" 13 "Reserved" 12 "Reserved" 11 "projection screen" 10 "Rear Audio and Video" 9 "3rd Party" 8 "Flytek Game" 7 "Flytek Media " 6 "Carlife Audio" 5 "Carplay Audio" 4 "USB2 Media" 3 "USB1 Media" 2 "Radio" 1 "BT Music" 0 "None" ;
VAL_ 185 ACU_SetEqMode 3 "No Command" 2 "rear seats" 1 "All seats" 0 "Front seats" ;
VAL_ 185 ACU_GetIntVoltReq 3 "No Command" 2 "Reserved" 1 "Get info" 0 "No action" ;
VAL_ 185 ACU_GetTempReq 3 "No Command" 2 "Reserved" 1 "Get info" 0 "No action" ;
VAL_ 185 ACU_MainVolSet 63 " No Command" 62 " Reserved" 61 " Reserved" 60 " Reserved" 59 " Reserved" 58 " Reserved" 57 " Reserved" 56 " Reserved" 55 " Reserved" 54 " Reserved" 53 " Reserved" 52 " Reserved" 51 " Reserved" 50 " Reserved" 49 " Reserved" 48 " Reserved" 47 " Reserved" 46 " Reserved" 45 " Reserved" 44 " Reserved" 43 " Reserved" 42 " Reserved" 41 " Reserved" 40 " Reserved" 39 " Main volume step 0-39" 38 " Main volume step 0-39" 37 " Main volume step 0-39" 36 " Main volume step 0-39" 35 " Main volume step 0-39" 34 " Main volume step 0-39" 33 " Main volume step 0-39" 32 " Main volume step 0-39" 31 " Main volume step 0-39" 30 " Main volume step 0-39" 29 " Main volume step 0-39" 28 " Main volume step 0-39" 27 " Main volume step 0-39" 26 " Main volume step 0-39" 25 " Main volume step 0-39" 24 " Main volume step 0-39" 23 " Main volume step 0-39" 22 " Main volume step 0-39" 21 " Main volume step 0-39" 20 " Main volume step 0-39" 19 " Main volume step 0-39" 18 " Main volume step 0-39" 17 " Main volume step 0-39" 16 " Main volume step 0-39" 15 " Main volume step 0-39" 14 " Main volume step 0-39" 13 " Main volume step 0-39" 12 " Main volume step 0-39" 11 " Main volume step 0-39" 10 " Main volume step 0-39" 9 " Main volume step 0-39" 8 " Main volume step 0-39" 7 " Main volume step 0-39" 6 " Main volume step 0-39" 5 " Main volume step 0-39" 4 " Main volume step 0-39" 3 " Main volume step 0-39" 2 " Main volume step 0-39" 1 " Main volume step 0-39" 0 " Main volume step 0-39" ;
VAL_ 185 ACU_NaviVolSet 63 " No Command" 62 " Reserved" 61 " Reserved" 60 " Reserved" 59 " Reserved" 58 " Reserved" 57 " Reserved" 56 " Reserved" 55 " Reserved" 54 " Reserved" 53 " Reserved" 52 " Reserved" 51 " Reserved" 50 " Reserved" 49 " Reserved" 48 " Reserved" 47 " Reserved" 46 " Reserved" 45 " Reserved" 44 " Reserved" 43 " Reserved" 42 " Reserved" 41 " Reserved" 40 " Reserved" 39 " Reserved" 38 " Reserved" 37 " Reserved" 36 " Reserved" 35 " Reserved" 34 " Reserved" 33 " Reserved" 32 " Reserved" 31 " Reserved" 30 " Reserved" 29 " Reserved" 28 " Reserved" 27 " Reserved" 26 " Reserved" 25 " Reserved" 24 " Reserved" 23 " Reserved" 22 " Reserved" 21 " Reserved" 20 " Reserved" 19 " Reserved" 18 " Reserved" 17 " Reserved" 16 " Reserved" 15 " Reserved" 14 " Reserved" 13 " Reserved" 12 " Reserved" 11 " Reserved" 10 " Navi volume step 0-10" 9 " Navi volume step 0-10" 8 " Navi volume step 0-10" 7 " Navi volume step 0-10" 6 " Navi volume step 0-10" 5 " Navi volume step 0-10" 4 " Navi volume step 0-10" 3 " Navi volume step 0-10" 2 " Navi volume step 0-10" 1 " Navi volume step 0-10" 0 " Navi volume step 0-10" ;
VAL_ 185 ACU_VRVolSet 63 " No Command" 62 " Reserved" 61 " Reserved" 60 " Reserved" 59 " Reserved" 58 " Reserved" 57 " Reserved" 56 " Reserved" 55 " Reserved" 54 " Reserved" 53 " Reserved" 52 " Reserved" 51 " Reserved" 50 " Reserved" 49 " Reserved" 48 " Reserved" 47 " Reserved" 46 " Reserved" 45 " Reserved" 44 " Reserved" 43 " Reserved" 42 " Reserved" 41 " Reserved" 40 " Reserved" 39 " Reserved" 38 " Reserved" 37 " Reserved" 36 " Reserved" 35 " Reserved" 34 " Reserved" 33 " Reserved" 32 " Reserved" 31 " Reserved" 30 " Reserved" 29 " Reserved" 28 " Reserved" 27 " Reserved" 26 " Reserved" 25 " Reserved" 24 " Reserved" 23 " Reserved" 22 " Reserved" 21 " Reserved" 20 " Reserved" 19 " Reserved" 18 " Reserved" 17 " Reserved" 16 " Reserved" 15 " Reserved" 14 " Reserved" 13 " Reserved" 12 " Reserved" 11 " Reserved" 10 "VR_ TTS volume step 0-10" 9 "VR_ TTS volume step 0-10" 8 "VR_ TTS volume step 0-10" 7 "VR_ TTS volume step 0-10" 6 "VR_ TTS volume step 0-10" 5 "VR_ TTS volume step 0-10" 4 "VR_ TTS volume step 0-10" 3 "VR_ TTS volume step 0-10" 2 "VR_ TTS volume step 0-10" 1 "VR_ TTS volume step 0-10" 0 "VR_ TTS volume step 0-10" ;
VAL_ 185 ACU_TelVolSet 63 " No Command" 62 " Reserved" 61 " Reserved" 60 " Reserved" 59 " Reserved" 58 " Reserved" 57 " Reserved" 56 " Reserved" 55 " Reserved" 54 " Reserved" 53 " Reserved" 52 " Reserved" 51 " Reserved" 50 " Reserved" 49 " Reserved" 48 " Reserved" 47 " Reserved" 46 " Reserved" 45 " Reserved" 44 " Reserved" 43 " Reserved" 42 " Reserved" 41 " Reserved" 40 " Reserved" 39 " Reserved" 38 " Reserved" 37 " Reserved" 36 " Reserved" 35 " Reserved" 34 " Reserved" 33 " Reserved" 32 " Reserved" 31 " Reserved" 30 " Reserved" 29 " Reserved" 28 " Reserved" 27 " Reserved" 26 " Reserved" 25 " Reserved" 24 " Reserved" 23 " Reserved" 22 " Reserved" 21 " Reserved" 20 " Reserved" 19 " Reserved" 18 " Reserved" 17 " Reserved" 16 " Reserved" 15 " Reserved" 14 " Reserved" 13 " Reserved" 12 " Reserved" 11 " Reserved" 10 " HFM volume step 0-10" 9 " HFM volume step 0-10" 8 " HFM volume step 0-10" 7 " HFM volume step 0-10" 6 " HFM volume step 0-10" 5 " HFM volume step 0-10" 4 " HFM volume step 0-10" 3 " HFM volume step 0-10" 2 " HFM volume step 0-10" 1 " HFM volume step 0-10" 0 " HFM volume step 0-10" ;
VAL_ 186 ACU_SpeakMid 3 "No Command" 2 "Reserved" 1 "ON" 0 "OFF" ;
VAL_ 186 ACU_SpeakRR 3 "No Command" 2 "Reserved" 1 "ON" 0 "OFF" ;
VAL_ 186 ACU_SpeakRL 3 "No Command" 2 "Reserved" 1 "ON" 0 "OFF" ;
VAL_ 186 ACU_SpeakFR 3 "No Command" 2 "Reserved" 1 "ON" 0 "OFF" ;
VAL_ 186 ACU_SpeakFL 3 "No Command" 2 "Reserved" 1 "ON" 0 "OFF" ;
VAL_ 186 ACU_ClariFiSet 3 "No Command" 2 "Reserved" 1 "ON" 0 "OFF" ;
VAL_ 186 ACU_PowerSet 3 "No Command" 2 "Reserved" 1 " ON" 0 " OFF" ;
VAL_ 186 ACU_HighFrqSet 31 "No Command" 30 "Reserved" 29 "Reserved" 28 "Reserved" 27 "Reserved" 26 "Reserved" 25 "Reserved" 24 "Reserved" 23 "Reserved" 22 "Reserved" 21 "Reserved" 20 "10" 19 "9" 18 "8" 17 "7" 16 "6" 15 "5" 14 "4" 13 "3" 12 "2" 11 "1" 10 "0" 9 "-1" 8 "-2" 7 "-3" 6 "-4" 5 "-5" 4 "-6" 3 "-7" 2 "-8" 1 "-9" 0 "-10" ;
VAL_ 186 ACU_TEL_ECallSet 3 "No Command" 2 "Reserved" 1 "ON" 0 "OFF" ;
VAL_ 186 ACU_MuteRearSet 3 "No Command" 2 "Reserved" 1 " Mute" 0 " Unmute" ;
VAL_ 186 ACU_MuteSet 3 "No Command" 2 "Reserved" 1 " Mute" 0 " Unmute" ;
VAL_ 186 ACU_DrvSideSet 3 "No Command" 2 "Reserved" 1 "RHD" 0 "LHD" ;
VAL_ 186 ACU_MidFrqSet 31 "No Command" 30 "Reserved" 29 "Reserved" 28 "Reserved" 27 "Reserved" 26 "Reserved" 25 "Reserved" 24 "Reserved" 23 "Reserved" 22 "Reserved" 21 "Reserved" 20 "10" 19 "9" 18 "8" 17 "7" 16 "6" 15 "5" 14 "4" 13 "3" 12 "2" 11 "1" 10 "0" 9 "-1" 8 "-2" 7 "-3" 6 "-4" 5 "-5" 4 "-6" 3 "-7" 2 "-8" 1 "-9" 0 "-10" ;
VAL_ 186 ACU_LowFrqSet 31 "No Command" 30 "Reserved" 29 "Reserved" 28 "Reserved" 27 "Reserved" 26 "Reserved" 25 "Reserved" 24 "Reserved" 23 "Reserved" 22 "Reserved" 21 "Reserved" 20 "10" 19 "9" 18 "8" 17 "7" 16 "6" 15 "5" 14 "4" 13 "3" 12 "2" 11 "1" 10 "0" 9 "-1" 8 "-2" 7 "-3" 6 "-4" 5 "-5" 4 "-6" 3 "-7" 2 "-8" 1 "-9" 0 "-10" ;
VAL_ 186 ACU_VSCModeReq 7 "No Command" 6 "Reserved" 5 "Reserved" 4 "Reserved" 3 "HI" 2 "MID" 1 "LOW" 0 "OFF" ;
VAL_ 186 ACU_FaderSet 31 "No Command" 30 "Reserved" 29 "Reserved" 28 "Reserved" 27 "Reserved" 26 "Reserved" 25 "Reserved" 24 "Reserved" 23 "Reserved" 22 "Reserved" 21 "Reserved" 20 "Front+1 - Front+10" 19 "Front+1 - Front+10" 18 "Front+1 - Front+10" 17 "Front+1 - Front+10" 16 "Front+1 - Front+10" 15 "Front+1 - Front+10" 14 "Front+1 - Front+10" 13 "Front+1 - Front+10" 12 "Front+1 - Front+10" 11 "Front+1 - Front+10" 10 "Center" 9 "Rear+10 - Rear+1" 8 "Rear+10 - Rear+1" 7 "Rear+10 - Rear+1" 6 "Rear+10 - Rear+1" 5 "Rear+10 - Rear+1" 4 "Rear+10 - Rear+1" 3 "Rear+10 - Rear+1" 2 "Rear+10 - Rear+1" 1 "Rear+10 - Rear+1" 0 "Rear+10 - Rear+1" ;
VAL_ 186 ACU_BlcSet 31 "No Command" 30 "Reserved" 29 "Reserved" 28 "Reserved" 27 "Reserved" 26 "Reserved" 25 "Reserved" 24 "Reserved" 23 "Reserved" 22 "Reserved" 21 "Reserved" 20 "Rch+1 - Rch+10" 19 "Rch+1 - Rch+10" 18 "Rch+1 - Rch+10" 17 "Rch+1 - Rch+10" 16 "Rch+1 - Rch+10" 15 "Rch+1 - Rch+10" 14 "Rch+1 - Rch+10" 13 "Rch+1 - Rch+10" 12 "Rch+1 - Rch+10" 11 "Rch+1 - Rch+10" 10 "Center" 9 "Lch+10 - Lch+1" 8 "Lch+10 - Lch+1" 7 "Lch+10 - Lch+1" 6 "Lch+10 - Lch+1" 5 "Lch+10 - Lch+1" 4 "Lch+10 - Lch+1" 3 "Lch+10 - Lch+1" 2 "Lch+10 - Lch+1" 1 "Lch+10 - Lch+1" 0 "Lch+10 - Lch+1" ;
VAL_ 1067 ACU_NMWakeupOrigin 255 "Reserved" 254 "Reserved" 253 "Reserved" 252 "Reserved" 251 "Reserved" 250 "Reserved" 249 "Reserved" 248 "Reserved" 247 "Reserved" 246 "Reserved" 245 "Reserved" 244 "Reserved" 243 "Reserved" 242 "Reserved" 241 "Reserved" 240 "Reserved" 239 "Reserved" 238 "Reserved" 237 "Reserved" 236 "Reserved" 235 "Reserved" 234 "Reserved" 233 "Reserved" 232 "Reserved" 231 "Reserved" 230 "Reserved" 229 "Reserved" 228 "Reserved" 227 "Reserved" 226 "Reserved" 225 "Reserved" 224 "Reserved" 223 "Reserved" 222 "Reserved" 221 "Reserved" 220 "Reserved" 219 "Reserved" 218 "Reserved" 217 "Reserved" 216 "Reserved" 215 "Reserved" 214 "Reserved" 213 "Reserved" 212 "Reserved" 211 "Reserved" 210 "Reserved" 209 "Reserved" 208 "Reserved" 207 "Reserved" 206 "Reserved" 205 "Reserved" 204 "Reserved" 203 "Reserved" 202 "Reserved" 201 "Reserved" 200 "Reserved" 199 "Reserved" 198 "Reserved" 197 "Reserved" 196 "Reserved" 195 "Reserved" 194 "Reserved" 193 "Reserved" 192 "Reserved" 191 "Reserved" 190 "Reserved" 189 "Reserved" 188 "Reserved" 187 "Reserved" 186 "Reserved" 185 "Reserved" 184 "Reserved" 183 "Reserved" 182 "Reserved" 181 "Reserved" 180 "Reserved" 179 "Reserved" 178 "Reserved" 177 "Reserved" 176 "Reserved" 175 "Reserved" 174 "Reserved" 173 "Reserved" 172 "Reserved" 171 "Reserved" 170 "Reserved" 169 "Reserved" 168 "Reserved" 167 "Reserved" 166 "Reserved" 165 "Reserved" 164 "Reserved" 163 "Reserved" 162 "Reserved" 161 "Reserved" 160 "Reserved" 159 "Reserved" 158 "Reserved" 157 "Reserved" 156 "Reserved" 155 "Reserved" 154 "Reserved" 153 "Reserved" 152 "Reserved" 151 "Reserved" 150 "Reserved" 149 "Reserved" 148 "Reserved" 147 "Reserved" 146 "Reserved" 145 "Reserved" 144 "Reserved" 143 "Reserved" 142 "Reserved" 141 "Reserved" 140 "Reserved" 139 "Reserved" 138 "Reserved" 137 "Reserved" 136 "Reserved" 135 "Reserved" 134 "Reserved" 133 "Reserved" 132 "Reserved" 131 "Reserved" 130 "Reserved" 129 "Reserved" 128 "Reserved" 127 "Reserved" 126 "Reserved" 125 "Reserved" 124 "Reserved" 123 "Reserved" 122 "Reserved" 121 "Reserved" 120 "Reserved" 119 "Reserved" 118 "Reserved" 117 "Reserved" 116 "Reserved" 115 "Reserved" 114 "Reserved" 113 "Reserved" 112 "Reserved" 111 "Reserved" 110 "Reserved" 109 "Reserved" 108 "Reserved" 107 "Reserved" 106 "Reserved" 105 "Reserved" 104 "Reserved" 103 "Reserved" 102 "Reserved" 101 "Reserved" 100 "Reserved" 99 "Reserved" 98 "Reserved" 97 "Reserved" 96 "Reserved" 95 "Reserved" 94 "Reserved" 93 "Reserved" 92 "Reserved" 91 "Reserved" 90 "Reserved" 89 "Reserved" 88 "Reserved" 87 "Reserved" 86 "Reserved" 85 "Reserved" 84 "Reserved" 83 "Reserved" 82 "Reserved" 81 "Reserved" 80 "Reserved" 79 "Reserved" 78 "Reserved" 77 "Reserved" 76 "Reserved" 75 "Reserved" 74 "Reserved" 73 "Reserved" 72 "Reserved" 71 "Reserved" 70 "Reserved" 69 "Reserved" 68 "Reserved" 67 "Reserved" 66 "Reserved" 65 "Reserved" 64 "Reserved" 63 "Reserved" 62 "Reserved" 61 "Reserved" 60 "Reserved" 59 "Reserved" 58 "Reserved" 57 "Reserved" 56 "Reserved" 55 "Reserved" 54 "Reserved" 53 "Reserved" 52 "Reserved" 51 "Reserved" 50 "Reserved" 49 "Reserved" 48 "Reserved" 47 "Reserved" 46 "Reserved" 45 "Reserved" 44 "Reserved" 43 "Reserved" 42 "Reserved" 41 "Reserved" 40 "Reserved" 39 "Reserved" 38 "Reserved" 37 "Reserved" 36 "Reserved" 35 "Reserved" 34 "Reserved" 33 "Reserved" 32 "Reserved" 31 "Reserved" 30 "Reserved" 29 "Reserved" 28 "Reserved" 27 "Reserved" 26 "Reserved" 25 "Reserved" 24 "Reserved" 23 "Reserved" 22 "Reserved" 21 "Reserved" 20 "Reserved" 19 "Reserved" 18 "Reserved" 17 "IGN ACC" 16 "Not used" 15 "Not used" 14 "Not used" 13 "Not used" 12 "Not used" 11 "Not used" 10 "Not used" 9 "Not used" 8 "Not used" 7 "Not used" 6 "Not used" 5 "Not used" 4 "Not used" 3 "Not used" 2 "Not used" 1 "Message wake up" ;
VAL_ 1067 ACU_NMSleepAck 1 "Active" 0 "Not active" ;
VAL_ 1067 ACU_NMSleepInd 1 "Active" 0 "Not active" ;
VAL_ 1067 ACU_NMLimpHome 1 "Active" 0 "Not active" ;
VAL_ 1067 ACU_NMRing 1 "Active" 0 "Not active" ;
VAL_ 1067 ACU_NMAlive 1 "Active" 0 "Not active" ;
VAL_ 72 ACU_PLGMFuncCfg 3 "Not used" 2 "Enable" 1 "Disable" 0 "No command" ;
VAL_ 72 ACU_PLGMTrunkReleaseReq 1 "Active" 0 "Not active" ;
VAL_ 72 ACU_PLGMMaxPstReq 1 "Active" 0 "Not active" ;
VAL_ 72 ACU_PLGMSetPstClearReq 1 "Valid" 0 "Invalid" ;
VAL_ 72 ACU_PLGMCloseReqVD 1 "Valid" 0 "Invalid" ;
VAL_ 72 ACU_PLGMCloseReq 1 "Request" 0 "No request" ;
VAL_ 72 ACU_PLGMOpenReqVD 1 "Valid" 0 "Invalid" ;
VAL_ 72 ACU_PLGMOpenReq 1 "Request" 0 "No request" ;
